[part 1 of 4: package /ComponentTypes]
AUTOSAR XML (schema 00050)
package /ComponentTypes
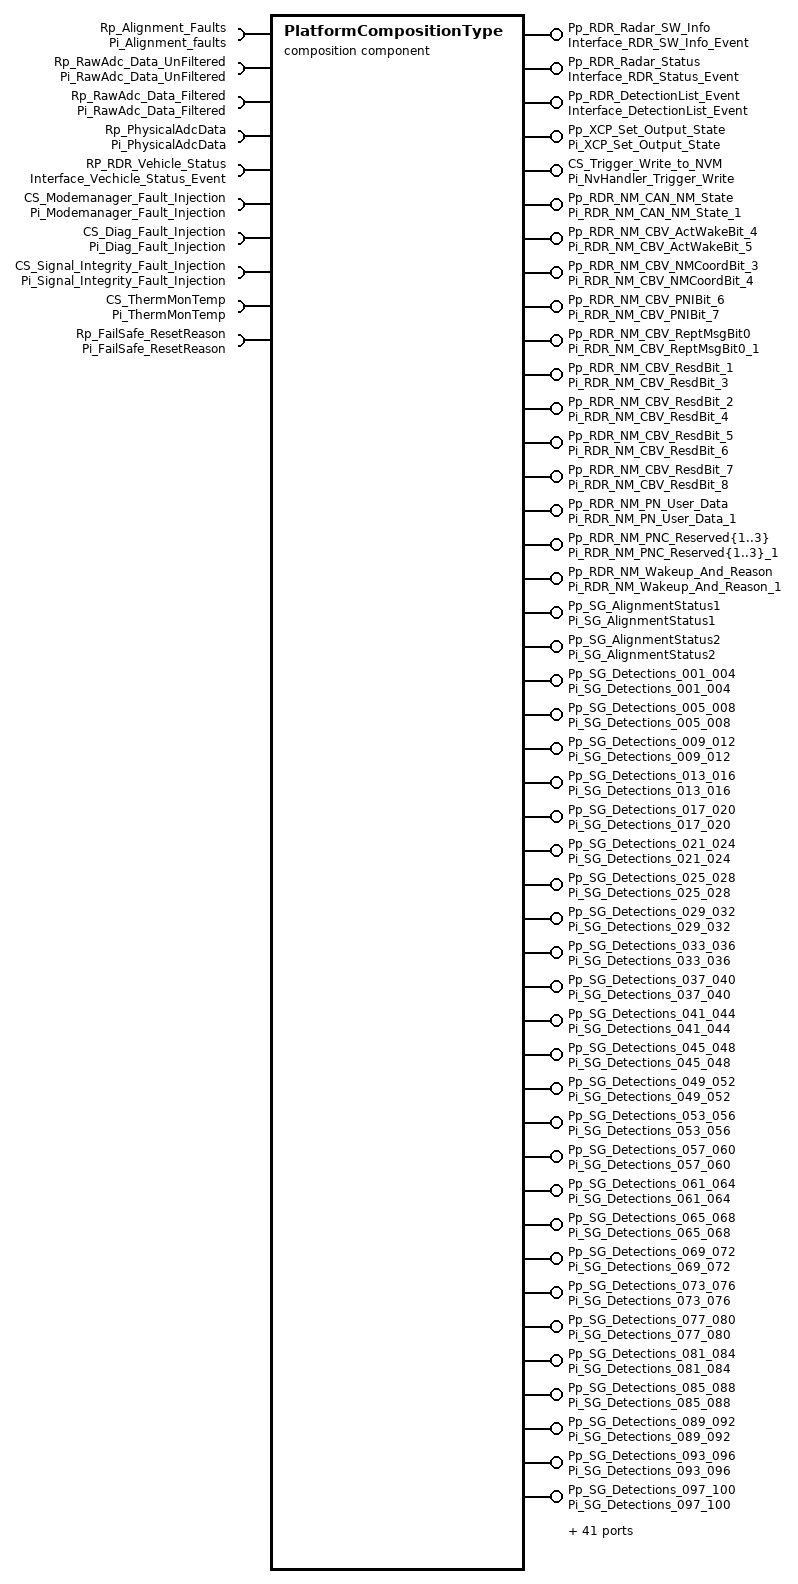
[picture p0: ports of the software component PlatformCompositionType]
  composition sw component type PlatformCompositionType
    4 x require port:
      Rp_Alignment_Faults: nonqueued-receiver-com-spec{data-element=De_Alignment_Faults, filter=data-filter-type=ALWAYS, init-value=constant-reference=C_Alignment_faults}, required-interface=Pi_Alignment_faults
      Rp_RawAdc_Data_UnFiltered: nonqueued-receiver-com-spec{data-element=RawAdcDataUnfiltered, filter=data-filter-type=ALWAYS, init-value=fields=[Adc_Board_Rev:0, Adc_Batt_Volt:0, Adc_Pos_Gnd_A:0, Adc_Pos_Gnd_B:0, Adc_Pos_Gnd_C:0, Adc_Pos_Gnd_D:0, Adc_Eth_0v9:0, Adc_Rdi_Detect:0, Adc_MMIC_Temp:0, Adc_Mcu_Temp:0, Validity_Flag:0]}, required-interface=Pi_RawAdc_Data_UnFiltered
      Rp_RawAdc_Data_Filtered: nonqueued-receiver-com-spec{data-element=De_RawAdcData, filter=data-filter-type=ALWAYS, init-value=fields=[Adc_Board_Rev:0, Adc_Batt_Volt:0, Adc_Pos_Gnd_A:0, Adc_Pos_Gnd_B:0, Adc_Pos_Gnd_C:0, Adc_Pos_Gnd_D:0, Adc_Eth_0v9:0, Adc_Rdi_Detect:0, Adc_MMIC_Temp:0, Adc_Mcu_Temp:0, Validity_Flag:0]}, required-interface=Pi_RawAdc_Data_Filtered
      Rp_PhysicalAdcData: nonqueued-receiver-com-spec{data-element=De_PhysicalAdcData, filter=data-filter-type=ALWAYS, init-value=fields=[Adc_Board_Rev:0, Adc_Batt_Volt:0, Adc_Pos_Gnd_A:0, Adc_Pos_Gnd_B:0, Adc_Pos_Gnd_C:0, Adc_Pos_Gnd_D:0, Adc_Eth_0v9:0, Adc_Rdi_Detect:0, Adc_MMIC_Temp:0, Adc_Mcu_Temp:0, Validity_Flag:0]}, required-interface=Pi_PhysicalAdcData
    provide port Pp_RDR_Radar_SW_Info: nonqueued-sender-com-spec{data-element=RDR_SW_Info, init-value=fields=[{short-label=INFO_CALIBRATION_VERSION, fields=[STS_SMC_CAL_VER_MAJOR:0, STS_SMC_CAL_VER_MINOR:0, STS_SMC_PLATFROM_VERSION:0, STS_SMC_SECTION_COMPTBLITY:0, STS_USC_CAL_VER_MAJOR:0, STS_USC_CAL_VER_MINOR:0, STS_USC_SECTION_COMPTBLITY:0]}, {short-label=INFO_MOUNTING_POS, fields=[STS_SENSOR_HEIGHT:0, STS_SENSOR_MOUNT_LOCATION:0, STS_SENSOR_MOUNT_ORNT_PITCH:0, STS_SENSOR_MOUNT_ORNT_ROLL:0, STS_SENSOR_MOUNT_ORNT_YAW:0, STS_SENSOR_MOUNT_POS_X:0, STS_SENSOR_MOUNT_POS_Y:0, STS_SENSOR_MOUNT_POS_Z:0, STS_SENSOR_POSITION:0]}, {short-label=INFO_SW_VERSION, fields=[STS_PBL_VERSION_FIELD1:0, STS_PBL_VERSION_FIELD2:0, STS_PBL_VERSION_FIELD3:0, STS_PBL_VERSION_FIELD4:0, STS_SW_VERSION_FIELD1:0, STS_SW_VERSION_FIELD2:0, STS_SW_VERSION_FIELD3:0, STS_SW_VERSION_FIELD4:0]}, {short-label=INFO_HW_CAN_VERSION, fields=[STS_DET_DBC_BASE_VER_MAJOR:0, STS_DET_DBC_BASE_VER_MINOR:0, STS_HARDWARE_VERSION:0, STS_PCAN_PROTOCOL_VER_MAJOR:0, STS_PCAN_PROTOCOL_VER_MINOR:0, STS_PLATFORM_VARIANT:0, STS_SERIAL_NUM_JULIAN_DAY:0, STS_SERIAL_NUM_JULIAN_YEAR:0, STS_SERIAL_NUMBER_SEQUENCE:0]}, {short-label=INFO_E2E_HDR, fields=[CRC:0, COUNTER:0, DATA_ID:0, LENGTH:0]}]}, provided-interface=Interface_RDR_SW_Info_Event
    provide port Pp_RDR_Radar_Status: nonqueued-sender-com-spec{data-element=RDR_Status, init-value=fields=[{short-label=STS_ALIGNMENT_HANDLER, fields=[STS_AlignmentAzimuth:0, STS_AlignmentElevation:0, STS_AlignmentError:0, STS_AlignmentModeIn:0, STS_AlignmentModeOut:0, STS_AzimuthStd:0, STS_CalDisplay:0, STS_CalTime:0, STS_CoordinateSystemInput:0, STS_ElevationStd:0, 0, 0, 0, 0, 0, 0, STS_ProgressPercent:0, STS_RadarTypeInput:0]}, {short-label=STS_ALIGNMENT_AUTO, fields=[STS_AAAzimuthStd:0, STS_AACurrentAzimuth:0, STS_AACurrentElevation:0, STS_AAElevationStd:0, STS_AlignmentAutoStatus:0, STS_AutoAlignmentFailRootCause:0, STS_AzimuthErrorNegative:0, STS_AzimuthErrorPositive:0, STS_AzimuthUpdates:0, STS_ElevationErrorNegative:0, STS_ElevationErrorPositive:0, STS_ElevationUpdates:0, STS_HostSpdCompensationFactorQF:0, STS_HostSpeedCompensationFactor:0, STS_RollErrorPositive:0, STS_StartAzimuth:0, STS_StartElevation:0]}, {short-label=STS_ALIGNMENT_STATIC, fields=[STS_AlignmentStaticStatus:0, STS_ImpactByInterference:0, STS_Measured_Range:0, STS_MeasuredRangeRate:0, STS_MeasuredRangeRateStd:0, STS_MeasuredRangeStd:0, STS_MeasuredRCS:0, STS_MeasuredRCSStd:0]}, {short-label=STS_ALIGNMENT_SERVICE, fields=[STS_AlignmentServiceStatus:0, STS_AverageNumberOfDetections:0, STS_AverageSpeed:0, STS_DistanceAbsolute:0, STS_DistanceEffective:0, STS_DurationAbsolute:0, STS_DurationEffective:0, STS_VehicleCondition:0]}, {short-label=STS_ALIGN_SHORT_TRACK, fields=STS_AlignmentShortTrackStatus:0}, {short-label=STS_CAPAB_RDR_PERF, fields=[CAP_BlockageActive:0, CAP_BlockageProbability:0, CAP_BlockageSensitivity:0, CAP_BlockageStatus:0, CAP_BlockageValue:0, CAP_FreeSightCheckActive:0, CAP_FreeSightCheckStatus:0, CAP_SLBlockageFilterValue:0, CAP_SLBlockageFlag:0]}, {short-label=STS_CAPAB_DAMPING, fields=[CAP_DampingActive:0, CAP_DampingCurrent:0, CAP_DampingStandardDeviation:0, CAP_DampingStatus:0]}, {short-label=STS_CAPAB_RANGE_DET, fields=[CAP_AngleAzimuthRangeEnd:0, CAP_AngleAzimuthRangeStart:0, CAP_MaxDetectionRangeCar:[0, 0, 0], CAP_MaxDetRangeMotorbike:[0, 0, 0], CAP_MaxDetRangePedestrian:[0, 0, 0], CAP_RangeEstimationActive:0, CAP_RangeEstimationStatus:0]}, {short-label=STS_CAPAB_SLL_MONITOR, fields=[CAP_SideLobeLevelBeamformer:0, CAP_SLLMonitoringActive:0, CAP_SLLMonitoringStatus:0]}, {short-label=STS_TIMESYNC_STATUS, fields=[STS_NO_TSYN_ERROR:0, STS_POINT_OF_TRIGGER:0, STS_TIME_SYNC_OFFSET:0]}, {short-label=STS_SENSOR_PERF, fields=STS_BRR_STATUS:0}, {short-label=STS_TEMPERATURE, fields=[STS_MCU_TEMP:0, STS_MMIC_TEMP_RX:0, STS_MMIC_TEMP_TX0:0, STS_MMIC_TEMP_TX1_2:0, STS_MMIC_TEMP_TX3_4:0]}, {short-label=STS_FAULTS, fields=STS_CORE_ACTIVE_FAULTS:0}, {short-label=STS_RADAR_PROFILE, fields=[STS_AF_CORE_THROUGHPUT:0, 0, STS_RDD_CORE_THROUGHPUT:0, STS_SCAN_TYPE:0, STS_XCVR_OPERATIONAL:0]}, {short-label=STS_VEHICLE, fields=[STS_STEERING_ANGLE:0, STS_STEERING_ANGLE_SIGN:0, STS_VEH_SPEED_DIRECTION:0, STS_VEHICLE_SPEED_CALC:0, STS_VEHICLE_SUPPLY_VOLTAGE:0, STS_YAW_RATE_BIAS:0]}, {short-label=STS_E2E_HDR, fields=[CRC:0, COUNTER:0, DATA_ID:0, LENGTH:0]}]}, provided-interface=Interface_RDR_Status_Event
    provide port Pp_RDR_DetectionList_Event: nonqueued-sender-com-spec{data-element=DetectionList_Event, init-value=fields=[{short-label=DET_HEADER_STRUCT, fields=[{short-label=HED_SENSOR_COVERAGE, fields=[HED_DET_RANGE_MAX:0, HED_DET_RANGE_MIN:0, HED_DET_SPEED_RANGE_MAX:0, HED_DET_SPEED_RANGE_MIN:0, HED_FOV_HOR_MAX:0, HED_FOV_HOR_MIN:0, HED_FOV_VER_MAX:0, HED_FOV_VER_MIN:0]}, {short-label=HED_RADAR_STATE, fields=[HED_DATA_QUALIFIER:0, HED_LOOK_ID:0, HED_LOOK_INDEX:0, HED_NUM_OF_VALID_DETECTIONS:0, HED_SCAN_INDEX:0]}, {short-label=HED_ALIGNMENT, fields=[HED_ALIGN_HOR_QF:0, HED_ALIGN_HOR_REF:0, HED_ALIGN_VER_QF:0, HED_ALIGN_VER_REF:0]}, {short-label=HED_TIMING_PROFILES, fields=[HED_AF_TIME_INST:0, HED_AF_TIME_PEAK:0, HED_MAIN_CORE_TIME_INST:0, HED_MAIN_CORE_TIME_PEAK:0, HED_RDD_CORE_TIME_INST:0, HED_RDD_CORE_TIME_PEAK:0, HED_SP_CORE_TIME_INST:0, HED_SP_CORE_TIME_PEAK:0]}, {short-label=HED_TIMESTAMP, fields=[HED_SENSOR_TIME_STAMP_NS:0, HED_SENSOR_TIME_STAMP_SEC:0, HED_TIME_SYNC_SRC_MASTER:0, HED_TIME_SYNC_VALIDITY_FLAG:0, HED_TRIGGER_TIME:0]}, {short-label=HED_DETECTION_INFO, fields=[HED_DET_BI_STATIC_COUNT:0, HED_DET_NUM_OF_1PASS:0, HED_DET_NUM_OF_2PASS:0, HED_MAX_NUM_OF_DETECTIONS:0, HED_NUM_OF_RESTBINS_USED:0, HED_OPERATION_MODE:0, HED_PROCESSED_RANGE:0, HED_SLOPE_CORR_EXECUTIONFLAG:0]}, {short-label=HED_INTERFACE_VERSION, fields=[HED_INTRFC_VERSION_ID_MAJOR:0, HED_INTRFC_VERSION_ID_MINOR:0, HED_INTRFC_VERSION_ID_PATCH:0]}]}, {short-label=DET_E2E_HDR, fields=[CRC:0, COUNTER:0, DATA_ID:0, LENGTH:0]}, DETECTIONS_ARRAY:400 x fields=[DET_AZIMUTH:0, DET_AZIMUTH_ERR:0, DET_BI_STATIC_FLAG:0, DET_CONFD_AZIMUTH:0, DET_CONFD_ELEVATION:0, DET_ELEVATION:0, DET_ELEVATION_ERR:0, DET_EXISTENCE_PROB:0, DET_HVC_FLAG:0, DET_OUTSIDE_SECTOR:0, DET_POINT_TARGET_PROB:0, DET_RANGE:0, DET_RANGE_ERR:0, DET_RANGE_VELOCITY:0, DET_RANGE_VELOCITY_ERR:0, DET_RCS:0, DET_SNR:0, DET_SUPER_RES_TARGET:0, DET_VALID_FLAG:0]]}, provided-interface=Interface_DetectionList_Event
    4 x require port:
      RP_RDR_Vehicle_Status: nonqueued-receiver-com-spec{data-element=Vehicle_Status, filter=data-filter-type=ALWAYS, init-value=fields=[{short-label=System_Status_Vehicle, fields=[SSTS_STEERING_ANGLE:0, SSTS_STEERING_ANGLE_SIGN:0, SSTS_VEH_ODOMETER:0, SSTS_VEH_POWER_MODE_STATUS:0, SSTS_VEH_SPD_COMP_FACTOR:0, SSTS_VEH_SYSTEM_VOLTAGE:0, SSTS_VEHICLE_SPEED_CALC:0, SSTS_VEHICLE_SPEED_CALC_QF:0, SSTS_VEHICLE_STATE:0, SSTS_YAW_RATE_BIAS:0, SSTS_YAW_RATE_CALC:0, SSTS_YAW_RATE_CALC_QF:0]}, {short-label=System_Status_Vehicle_State, fields=[SSTS_DRIVE_DIR:0, SSTS_DRIVE_REVERSE:0, SSTS_GEAR_POSITION:0, SSTS_IGN_STATUS:0, SSTS_LROS_DRIVE_DIR:0, SSTS_LROS_DRIVE_REVERSE:0]}, {short-label=System_Status_ADAS_Version, fields=[SSTS_CAN_PCAN_MINOR_ADAS:0, SSTS_CAN_PCAN_MAJOR_ADAS:0, SSTS_SW_VERSION_ADAS:0]}, {short-label=System_Status_Absolute_Time, fields=[SSTS_VEH_AbsoluteTime_Day:0, SSTS_VEH_AbsoluteTime_Hour:0, SSTS_VEH_AbsoluteTime_Minute:0, SSTS_VEH_AbsoluteTime_Month:0, SSTS_VEH_AbsoluteTime_Second:0, SSTS_VEH_AbsoluteTime_Year:0]}, {short-label=SSTS_EtoE_HDR, fields=[EtoE_CRC:0, EtoE_COUNTER:0, EtoE_DATA_ID:0, EtoE_LENGTH:0]}]}, required-interface=Interface_Vechicle_Status_Event
      CS_Modemanager_Fault_Injection: client-com-spec=Read, required-interface=Pi_Modemanager_Fault_Injection
      CS_Diag_Fault_Injection: client-com-spec=Read, required-interface=Pi_Diag_Fault_Injection
      CS_Signal_Integrity_Fault_Injection: client-com-spec=Read, required-interface=Pi_Signal_Integrity_Fault_Injection
    provide port Pp_XCP_Set_Output_State: nonqueued-sender-com-spec{data-element=De_XCP_Set_Output, init-value=constant-reference=C_XCP_Output_State}, provided-interface=Pi_XCP_Set_Output_State
    require port CS_ThermMonTemp: client-com-spec=Read, required-interface=Pi_ThermMonTemp
    require port Rp_FailSafe_ResetReason: nonqueued-receiver-com-spec{data-element=De_FailSafe_ResetReason, filter=data-filter-type=ALWAYS, init-value=constant-reference=C_FailSafe_ResetReason_T}, required-interface=Pi_FailSafe_ResetReason
    189 x provide port:
      CS_Trigger_Write_to_NVM: server-com-spec{operation=NvHandler_Trigger_Write_To_NVM, queue-length=1}, provided-interface=Pi_NvHandler_Trigger_Write
      Pp_RDR_NM_CAN_NM_State: nonqueued-sender-com-spec{data-element=Vdp_RDR_NM_CAN_NM_State, init-value=0}, provided-interface=Pi_RDR_NM_CAN_NM_State_1
      Pp_RDR_NM_CBV_ActWakeBit_4: nonqueued-sender-com-spec{data-element=Vdp_RDR_NM_CBV_ActWakeBit_4, init-value=0}, provided-interface=Pi_RDR_NM_CBV_ActWakeBit_5
      Pp_RDR_NM_CBV_NMCoordBit_3: nonqueued-sender-com-spec{data-element=Vdp_RDR_NM_CBV_NMCoordBit_3, init-value=0}, provided-interface=Pi_RDR_NM_CBV_NMCoordBit_4
      Pp_RDR_NM_CBV_PNIBit_6: nonqueued-sender-com-spec{data-element=Vdp_RDR_NM_CBV_PNIBit_6, init-value=0}, provided-interface=Pi_RDR_NM_CBV_PNIBit_7
      Pp_RDR_NM_CBV_ReptMsgBit0: nonqueued-sender-com-spec{data-element=Vdp_RDR_NM_CBV_ReptMsgBit0, init-value=0}, provided-interface=Pi_RDR_NM_CBV_ReptMsgBit0_1
      Pp_RDR_NM_CBV_ResdBit_1: nonqueued-sender-com-spec{data-element=Vdp_RDR_NM_CBV_ResdBit_1, init-value=0}, provided-interface=Pi_RDR_NM_CBV_ResdBit_3
      Pp_RDR_NM_CBV_ResdBit_2: nonqueued-sender-com-spec{data-element=Vdp_RDR_NM_CBV_ResdBit_2, init-value=0}, provided-interface=Pi_RDR_NM_CBV_ResdBit_4
      Pp_RDR_NM_CBV_ResdBit_5: nonqueued-sender-com-spec{data-element=Vdp_RDR_NM_CBV_ResdBit_5, init-value=0}, provided-interface=Pi_RDR_NM_CBV_ResdBit_6
      Pp_RDR_NM_CBV_ResdBit_7: nonqueued-sender-com-spec{data-element=Vdp_RDR_NM_CBV_ResdBit_7, init-value=0}, provided-interface=Pi_RDR_NM_CBV_ResdBit_8
      Pp_RDR_NM_PN_User_Data: nonqueued-sender-com-spec{data-element=Vdp_RDR_NM_PN_User_Data, init-value=0}, provided-interface=Pi_RDR_NM_PN_User_Data_1
      Pp_RDR_NM_PNC_Reserved{1..3}: nonqueued-sender-com-spec{data-element=Vdp_RDR_NM_PNC_Reserved{1..3}, init-value=0}, provided-interface=Pi_RDR_NM_PNC_Reserved{1..3}_1
      Pp_RDR_NM_Wakeup_And_Reason: nonqueued-sender-com-spec{data-element=Vdp_RDR_NM_Wakeup_And_Reason, init-value=0}, provided-interface=Pi_RDR_NM_Wakeup_And_Reason_1
      Pp_SG_AlignmentStatus1: nonqueued-sender-com-spec{data-element=Vdp_SG_AlignmentStatus1, init-value=fields=[AL_STS_001_CYCLE_COUNTER:0, AL_STS_001_MH_CRC16:0, STS_AAAzimuthStd:0, STS_AACurrentAzimuth:0, STS_AACurrentElevation:0, STS_AAElevationStd:0, STS_AlignmentAutoStatus:0, STS_AlignmentAzimuth:0, STS_AlignmentElevation:0, STS_AlignmentError:0, STS_AlignmentModeIn:0, STS_AlignmentModeOut:0, STS_AutoAlignmentFailRootCause:5, STS_AzimuthErrorNegative:0, STS_AzimuthErrorPositive:0, STS_AzimuthStd:0, STS_AzimuthUpdates:0, STS_CalDisplay:0, STS_CalTime:0, STS_CoordinateSystemInput:0, STS_ElevationErrorNegative:0, STS_ElevationErrorPositive:0, STS_ElevationStd:0, STS_ElevationUpdates:0, STS_HostSpdCompensationFactorQF:0, STS_HostSpeedCompensationFactor:100, 0, 0, 0, 0, 100, 0, STS_ProgressPercent:0, STS_RadarTypeInput:0, STS_RollErrorPositive:0, STS_StartAzimuth:0, STS_StartElevation:0]}, provided-interface=Pi_SG_AlignmentStatus1
      Pp_SG_AlignmentStatus2: nonqueued-sender-com-spec{data-element=Vdp_SG_AlignmentStatus2, init-value=fields=[AL_STS_002_CYCLE_COUNTER:0, AL_STS_002_MH_CRC16:0, STS_AlignmentServiceStatus:0, STS_AlignmentShortTrackStatus:0, STS_AlignmentStaticStatus:0, STS_AverageNumberOfDetections:0, STS_AverageSpeed:0, STS_DistanceAbsolute:0, STS_DistanceEffective:0, STS_DurationAbsolute:0, STS_DurationEffective:0, STS_ImpactByInterference:0, STS_Measured_Range:1200, STS_MeasuredRangeRate:0, STS_MeasuredRangeRateStd:0, STS_MeasuredRangeStd:0, STS_MeasuredRCS:0, STS_MeasuredRCSStd:0, STS_VehicleCondition:6]}, provided-interface=Pi_SG_AlignmentStatus2
      Pp_SG_Detections_001_004: nonqueued-sender-com-spec{data-element=Vdp_SG_Detections_001_004, init-value=fields=[DET_AZIMUTH_001:0, DET_AZIMUTH_002:0, DET_AZIMUTH_003:0, DET_AZIMUTH_004:0, DET_AZIMUTH_ERR_001:0, DET_AZIMUTH_ERR_002:0, DET_AZIMUTH_ERR_003:0, DET_AZIMUTH_ERR_004:0, DET_BI_STATIC_FLAG_001:0, DET_BI_STATIC_FLAG_002:0, DET_BI_STATIC_FLAG_003:0, DET_BI_STATIC_FLAG_004:0, DET_CONFD_AZIMUTH_001:0, DET_CONFD_AZIMUTH_002:0, DET_CONFD_AZIMUTH_003:0, DET_CONFD_AZIMUTH_004:0, DET_CONFD_ELEVATION_001:0, DET_CONFD_ELEVATION_002:0, DET_CONFD_ELEVATION_003:0, DET_CONFD_ELEVATION_004:0, DET_ELEVATION_001:0, DET_ELEVATION_002:0, DET_ELEVATION_003:0, DET_ELEVATION_004:0, DET_ELEVATION_ERR_001:0, DET_ELEVATION_ERR_002:0, DET_ELEVATION_ERR_003:0, DET_ELEVATION_ERR_004:0, DET_EXISTENCE_PROB_001:0, DET_EXISTENCE_PROB_002:0, DET_EXISTENCE_PROB_003:0, DET_EXISTENCE_PROB_004:0, DET_HVC_FLAG_001:0, DET_HVC_FLAG_002:0, DET_HVC_FLAG_003:0, DET_HVC_FLAG_004:0, DET_MH_CRC16_001_004:0, DET_MH_CYCLE_COUNTER_001_004:0, DET_MH_SCAN_INDEX_4LSB_001_004:0, DET_OUTSIDE_SECTOR_001:0, DET_OUTSIDE_SECTOR_002:0, DET_OUTSIDE_SECTOR_003:0, DET_OUTSIDE_SECTOR_004:0, DET_POINT_TARGET_PROB_001:0, DET_POINT_TARGET_PROB_002:0, DET_POINT_TARGET_PROB_003:0, DET_POINT_TARGET_PROB_004:0, DET_RANGE_001:0, DET_RANGE_002:0, DET_RANGE_003:0, DET_RANGE_004:0, DET_RANGE_ERR_001:0, DET_RANGE_ERR_002:0, DET_RANGE_ERR_003:0, DET_RANGE_ERR_004:0, DET_RANGE_VELOCITY_001:16384, DET_RANGE_VELOCITY_002:16384, DET_RANGE_VELOCITY_003:16384, DET_RANGE_VELOCITY_004:16384, DET_RANGE_VELOCITY_ERR_001:0, DET_RANGE_VELOCITY_ERR_002:0, DET_RANGE_VELOCITY_ERR_003:0, DET_RANGE_VELOCITY_ERR_004:0, DET_RCS_001:128, DET_RCS_002:128, DET_RCS_003:128, DET_RCS_004:128, DET_SNR_001:0, DET_SNR_002:0, DET_SNR_003:0, DET_SNR_004:0, DET_SUPER_RES_TARGET_001:0, DET_SUPER_RES_TARGET_002:0, DET_SUPER_RES_TARGET_003:0, DET_SUPER_RES_TARGET_004:0, DET_VALID_FLAG_001:0, DET_VALID_FLAG_002:0, DET_VALID_FLAG_003:0, DET_VALID_FLAG_004:0]}, provided-interface=Pi_SG_Detections_001_004
      Pp_SG_Detections_005_008: nonqueued-sender-com-spec{data-element=Vdp_SG_Detections_005_008, init-value=fields=[DET_AZIMUTH_005:0, DET_AZIMUTH_006:0, DET_AZIMUTH_007:0, DET_AZIMUTH_008:0, DET_AZIMUTH_ERR_005:0, DET_AZIMUTH_ERR_006:0, DET_AZIMUTH_ERR_007:0, DET_AZIMUTH_ERR_008:0, DET_BI_STATIC_FLAG_005:0, DET_BI_STATIC_FLAG_006:0, DET_BI_STATIC_FLAG_007:0, DET_BI_STATIC_FLAG_008:0, DET_CONFD_AZIMUTH_005:0, DET_CONFD_AZIMUTH_006:0, DET_CONFD_AZIMUTH_007:0, DET_CONFD_AZIMUTH_008:0, DET_CONFD_ELEVATION_005:0, DET_CONFD_ELEVATION_006:0, DET_CONFD_ELEVATION_007:0, DET_CONFD_ELEVATION_008:0, DET_ELEVATION_005:0, DET_ELEVATION_006:0, DET_ELEVATION_007:0, DET_ELEVATION_008:0, DET_ELEVATION_ERR_005:0, DET_ELEVATION_ERR_006:0, DET_ELEVATION_ERR_007:0, DET_ELEVATION_ERR_008:0, DET_EXISTENCE_PROB_005:0, DET_EXISTENCE_PROB_006:0, DET_EXISTENCE_PROB_007:0, DET_EXISTENCE_PROB_008:0, DET_HVC_FLAG_005:0, DET_HVC_FLAG_006:0, DET_HVC_FLAG_007:0, DET_HVC_FLAG_008:0, DET_MH_CRC16_005_008:0, DET_MH_CYCLE_COUNTER_005_008:0, DET_MH_SCAN_INDEX_4LSB_005_008:0, DET_OUTSIDE_SECTOR_005:0, DET_OUTSIDE_SECTOR_006:0, DET_OUTSIDE_SECTOR_007:0, DET_OUTSIDE_SECTOR_008:0, DET_POINT_TARGET_PROB_005:0, DET_POINT_TARGET_PROB_006:0, DET_POINT_TARGET_PROB_007:0, DET_POINT_TARGET_PROB_008:0, DET_RANGE_005:0, DET_RANGE_006:0, DET_RANGE_007:0, DET_RANGE_008:0, DET_RANGE_ERR_005:0, DET_RANGE_ERR_006:0, DET_RANGE_ERR_007:0, DET_RANGE_ERR_008:0, DET_RANGE_VELOCITY_005:16384, DET_RANGE_VELOCITY_006:16384, DET_RANGE_VELOCITY_007:16384, DET_RANGE_VELOCITY_008:16384, DET_RANGE_VELOCITY_ERR_005:0, DET_RANGE_VELOCITY_ERR_006:0, DET_RANGE_VELOCITY_ERR_007:0, DET_RANGE_VELOCITY_ERR_008:0, DET_RCS_005:128, DET_RCS_006:128, DET_RCS_007:128, DET_RCS_008:128, DET_SNR_005:0, DET_SNR_006:0, DET_SNR_007:0, DET_SNR_008:0, DET_SUPER_RES_TARGET_005:0, DET_SUPER_RES_TARGET_006:0, DET_SUPER_RES_TARGET_007:0, DET_SUPER_RES_TARGET_008:0, DET_VALID_FLAG_005:0, DET_VALID_FLAG_006:0, DET_VALID_FLAG_007:0, DET_VALID_FLAG_008:0]}, provided-interface=Pi_SG_Detections_005_008
      Pp_SG_Detections_009_012: nonqueued-sender-com-spec{data-element=Vdp_SG_Detections_009_012, init-value=fields=[DET_AZIMUTH_009:0, DET_AZIMUTH_010:0, DET_AZIMUTH_011:0, DET_AZIMUTH_012:0, DET_AZIMUTH_ERR_009:0, DET_AZIMUTH_ERR_010:0, DET_AZIMUTH_ERR_011:0, DET_AZIMUTH_ERR_012:0, DET_BI_STATIC_FLAG_009:0, DET_BI_STATIC_FLAG_010:0, DET_BI_STATIC_FLAG_011:0, DET_BI_STATIC_FLAG_012:0, DET_CONFD_AZIMUTH_009:0, DET_CONFD_AZIMUTH_010:0, DET_CONFD_AZIMUTH_011:0, DET_CONFD_AZIMUTH_012:0, DET_CONFD_ELEVATION_009:0, DET_CONFD_ELEVATION_010:0, DET_CONFD_ELEVATION_011:0, DET_CONFD_ELEVATION_012:0, DET_ELEVATION_009:0, DET_ELEVATION_010:0, DET_ELEVATION_011:0, DET_ELEVATION_012:0, DET_ELEVATION_ERR_009:0, DET_ELEVATION_ERR_010:0, DET_ELEVATION_ERR_011:0, DET_ELEVATION_ERR_012:0, DET_EXISTENCE_PROB_009:0, DET_EXISTENCE_PROB_010:0, DET_EXISTENCE_PROB_011:0, DET_EXISTENCE_PROB_012:0, DET_HVC_FLAG_009:0, DET_HVC_FLAG_010:0, DET_HVC_FLAG_011:0, DET_HVC_FLAG_012:0, DET_MH_CRC16_009_012:0, DET_MH_CYCLE_COUNTER_009_012:0, DET_MH_SCAN_INDEX_4LSB_009_012:0, DET_OUTSIDE_SECTOR_009:0, DET_OUTSIDE_SECTOR_010:0, DET_OUTSIDE_SECTOR_011:0, DET_OUTSIDE_SECTOR_012:0, DET_POINT_TARGET_PROB_009:0, DET_POINT_TARGET_PROB_010:0, DET_POINT_TARGET_PROB_011:0, DET_POINT_TARGET_PROB_012:0, DET_RANGE_009:0, DET_RANGE_010:0, DET_RANGE_011:0, DET_RANGE_012:0, DET_RANGE_ERR_009:0, DET_RANGE_ERR_010:0, DET_RANGE_ERR_011:0, DET_RANGE_ERR_012:0, DET_RANGE_VELOCITY_009:16384, DET_RANGE_VELOCITY_010:16384, DET_RANGE_VELOCITY_011:16384, DET_RANGE_VELOCITY_012:16384, DET_RANGE_VELOCITY_ERR_009:0, DET_RANGE_VELOCITY_ERR_010:0, DET_RANGE_VELOCITY_ERR_011:0, DET_RANGE_VELOCITY_ERR_012:0, DET_RCS_009:128, DET_RCS_010:128, DET_RCS_011:128, DET_RCS_012:128, DET_SNR_009:0, DET_SNR_010:0, DET_SNR_011:0, DET_SNR_012:0, DET_SUPER_RES_TARGET_009:0, DET_SUPER_RES_TARGET_010:0, DET_SUPER_RES_TARGET_011:0, DET_SUPER_RES_TARGET_012:0, DET_VALID_FLAG_009:0, DET_VALID_FLAG_010:0, DET_VALID_FLAG_011:0, DET_VALID_FLAG_012:0]}, provided-interface=Pi_SG_Detections_009_012
      Pp_SG_Detections_013_016: nonqueued-sender-com-spec{data-element=Vdp_SG_Detections_013_016, init-value=fields=[DET_AZIMUTH_013:0, DET_AZIMUTH_014:0, DET_AZIMUTH_015:0, DET_AZIMUTH_016:0, DET_AZIMUTH_ERR_013:0, DET_AZIMUTH_ERR_014:0, DET_AZIMUTH_ERR_015:0, DET_AZIMUTH_ERR_016:0, DET_BI_STATIC_FLAG_013:0, DET_BI_STATIC_FLAG_014:0, DET_BI_STATIC_FLAG_015:0, DET_BI_STATIC_FLAG_016:0, DET_CONFD_AZIMUTH_013:0, DET_CONFD_AZIMUTH_014:0, DET_CONFD_AZIMUTH_015:0, DET_CONFD_AZIMUTH_016:0, DET_CONFD_ELEVATION_013:0, DET_CONFD_ELEVATION_014:0, DET_CONFD_ELEVATION_015:0, DET_CONFD_ELEVATION_016:0, DET_ELEVATION_013:0, DET_ELEVATION_014:0, DET_ELEVATION_015:0, DET_ELEVATION_016:0, DET_ELEVATION_ERR_013:0, DET_ELEVATION_ERR_014:0, DET_ELEVATION_ERR_015:0, DET_ELEVATION_ERR_016:0, DET_EXISTENCE_PROB_013:0, DET_EXISTENCE_PROB_014:0, DET_EXISTENCE_PROB_015:0, DET_EXISTENCE_PROB_016:0, DET_HVC_FLAG_013:0, DET_HVC_FLAG_014:0, DET_HVC_FLAG_015:0, DET_HVC_FLAG_016:0, DET_MH_CRC16_013_016:0, DET_MH_CYCLE_COUNTER_013_016:0, DET_MH_SCAN_INDEX_4LSB_013_016:0, DET_OUTSIDE_SECTOR_013:0, DET_OUTSIDE_SECTOR_014:0, DET_OUTSIDE_SECTOR_015:0, DET_OUTSIDE_SECTOR_016:0, DET_POINT_TARGET_PROB_013:0, DET_POINT_TARGET_PROB_014:0, DET_POINT_TARGET_PROB_015:0, DET_POINT_TARGET_PROB_016:0, DET_RANGE_013:0, DET_RANGE_014:0, DET_RANGE_015:0, DET_RANGE_016:0, DET_RANGE_ERR_013:0, DET_RANGE_ERR_014:0, DET_RANGE_ERR_015:0, DET_RANGE_ERR_016:0, DET_RANGE_VELOCITY_013:16384, DET_RANGE_VELOCITY_014:16384, DET_RANGE_VELOCITY_015:16384, DET_RANGE_VELOCITY_016:16384, DET_RANGE_VELOCITY_ERR_013:0, DET_RANGE_VELOCITY_ERR_014:0, DET_RANGE_VELOCITY_ERR_015:0, DET_RANGE_VELOCITY_ERR_016:0, DET_RCS_013:128, DET_RCS_014:128, DET_RCS_015:128, DET_RCS_016:128, DET_SNR_013:0, DET_SNR_014:0, DET_SNR_015:0, DET_SNR_016:0, DET_SUPER_RES_TARGET_013:0, DET_SUPER_RES_TARGET_014:0, DET_SUPER_RES_TARGET_015:0, DET_SUPER_RES_TARGET_016:0, DET_VALID_FLAG_013:0, DET_VALID_FLAG_014:0, DET_VALID_FLAG_015:0, DET_VALID_FLAG_016:0]}, provided-interface=Pi_SG_Detections_013_016
      Pp_SG_Detections_017_020: nonqueued-sender-com-spec{data-element=Vdp_SG_Detections_017_020, init-value=fields=[DET_AZIMUTH_017:0, DET_AZIMUTH_018:0, DET_AZIMUTH_019:0, DET_AZIMUTH_020:0, DET_AZIMUTH_ERR_017:0, DET_AZIMUTH_ERR_018:0, DET_AZIMUTH_ERR_019:0, DET_AZIMUTH_ERR_020:0, DET_BI_STATIC_FLAG_017:0, DET_BI_STATIC_FLAG_018:0, DET_BI_STATIC_FLAG_019:0, DET_BI_STATIC_FLAG_020:0, DET_CONFD_AZIMUTH_017:0, DET_CONFD_AZIMUTH_018:0, DET_CONFD_AZIMUTH_019:0, DET_CONFD_AZIMUTH_020:0, DET_CONFD_ELEVATION_017:0, DET_CONFD_ELEVATION_018:0, DET_CONFD_ELEVATION_019:0, DET_CONFD_ELEVATION_020:0, DET_ELEVATION_017:0, DET_ELEVATION_018:0, DET_ELEVATION_019:0, DET_ELEVATION_020:0, DET_ELEVATION_ERR_017:0, DET_ELEVATION_ERR_018:0, DET_ELEVATION_ERR_019:0, DET_ELEVATION_ERR_020:0, DET_EXISTENCE_PROB_017:0, DET_EXISTENCE_PROB_018:0, DET_EXISTENCE_PROB_019:0, DET_EXISTENCE_PROB_020:0, DET_HVC_FLAG_017:0, DET_HVC_FLAG_018:0, DET_HVC_FLAG_019:0, DET_HVC_FLAG_020:0, DET_MH_CRC16_017_020:0, DET_MH_CYCLE_COUNTER_017_020:0, DET_MH_SCAN_INDEX_4LSB_017_020:0, DET_OUTSIDE_SECTOR_017:0, DET_OUTSIDE_SECTOR_018:0, DET_OUTSIDE_SECTOR_019:0, DET_OUTSIDE_SECTOR_020:0, DET_POINT_TARGET_PROB_017:0, DET_POINT_TARGET_PROB_018:0, DET_POINT_TARGET_PROB_019:0, DET_POINT_TARGET_PROB_020:0, DET_RANGE_017:0, DET_RANGE_018:0, DET_RANGE_019:0, DET_RANGE_020:0, DET_RANGE_ERR_017:0, DET_RANGE_ERR_018:0, DET_RANGE_ERR_019:0, DET_RANGE_ERR_020:0, DET_RANGE_VELOCITY_017:16384, DET_RANGE_VELOCITY_018:16384, DET_RANGE_VELOCITY_019:16384, DET_RANGE_VELOCITY_020:16384, DET_RANGE_VELOCITY_ERR_017:0, DET_RANGE_VELOCITY_ERR_018:0, DET_RANGE_VELOCITY_ERR_019:0, DET_RANGE_VELOCITY_ERR_020:0, DET_RCS_017:128, DET_RCS_018:128, DET_RCS_019:128, DET_RCS_020:128, DET_SNR_017:0, DET_SNR_018:0, DET_SNR_019:0, DET_SNR_020:0, DET_SUPER_RES_TARGET_017:0, DET_SUPER_RES_TARGET_018:0, DET_SUPER_RES_TARGET_019:0, DET_SUPER_RES_TARGET_020:0, DET_VALID_FLAG_017:0, DET_VALID_FLAG_018:0, DET_VALID_FLAG_019:0, DET_VALID_FLAG_020:0]}, provided-interface=Pi_SG_Detections_017_020
      Pp_SG_Detections_021_024: nonqueued-sender-com-spec{data-element=Vdp_SG_Detections_021_024, init-value=fields=[DET_AZIMUTH_021:0, DET_AZIMUTH_022:0, DET_AZIMUTH_023:0, DET_AZIMUTH_024:0, DET_AZIMUTH_ERR_021:0, DET_AZIMUTH_ERR_022:0, DET_AZIMUTH_ERR_023:0, DET_AZIMUTH_ERR_024:0, DET_BI_STATIC_FLAG_021:0, DET_BI_STATIC_FLAG_022:0, DET_BI_STATIC_FLAG_023:0, DET_BI_STATIC_FLAG_024:0, DET_CONFD_AZIMUTH_021:0, DET_CONFD_AZIMUTH_022:0, DET_CONFD_AZIMUTH_023:0, DET_CONFD_AZIMUTH_024:0, DET_CONFD_ELEVATION_021:0, DET_CONFD_ELEVATION_022:0, DET_CONFD_ELEVATION_023:0, DET_CONFD_ELEVATION_024:0, DET_ELEVATION_021:0, DET_ELEVATION_022:0, DET_ELEVATION_023:0, DET_ELEVATION_024:0, DET_ELEVATION_ERR_021:0, DET_ELEVATION_ERR_022:0, DET_ELEVATION_ERR_023:0, DET_ELEVATION_ERR_024:0, DET_EXISTENCE_PROB_021:0, DET_EXISTENCE_PROB_022:0, DET_EXISTENCE_PROB_023:0, DET_EXISTENCE_PROB_024:0, DET_HVC_FLAG_021:0, DET_HVC_FLAG_022:0, DET_HVC_FLAG_023:0, DET_HVC_FLAG_024:0, DET_MH_CRC16_021_024:0, DET_MH_CYCLE_COUNTER_021_024:0, DET_MH_SCAN_INDEX_4LSB_021_024:0, DET_OUTSIDE_SECTOR_021:0, DET_OUTSIDE_SECTOR_022:0, DET_OUTSIDE_SECTOR_023:0, DET_OUTSIDE_SECTOR_024:0, DET_POINT_TARGET_PROB_021:0, DET_POINT_TARGET_PROB_022:0, DET_POINT_TARGET_PROB_023:0, DET_POINT_TARGET_PROB_024:0, DET_RANGE_021:0, DET_RANGE_022:0, DET_RANGE_023:0, DET_RANGE_024:0, DET_RANGE_ERR_021:0, DET_RANGE_ERR_022:0, DET_RANGE_ERR_023:0, DET_RANGE_ERR_024:0, DET_RANGE_VELOCITY_021:16384, DET_RANGE_VELOCITY_022:16384, DET_RANGE_VELOCITY_023:16384, DET_RANGE_VELOCITY_024:16384, DET_RANGE_VELOCITY_ERR_021:0, DET_RANGE_VELOCITY_ERR_022:0, DET_RANGE_VELOCITY_ERR_023:0, DET_RANGE_VELOCITY_ERR_024:0, DET_RCS_021:128, DET_RCS_022:128, DET_RCS_023:128, DET_RCS_024:128, DET_SNR_021:0, DET_SNR_022:0, DET_SNR_023:0, DET_SNR_024:0, DET_SUPER_RES_TARGET_021:0, DET_SUPER_RES_TARGET_022:0, DET_SUPER_RES_TARGET_023:0, DET_SUPER_RES_TARGET_024:0, DET_VALID_FLAG_021:0, DET_VALID_FLAG_022:0, DET_VALID_FLAG_023:0, DET_VALID_FLAG_024:0]}, provided-interface=Pi_SG_Detections_021_024
      Pp_SG_Detections_025_028: nonqueued-sender-com-spec{data-element=Vdp_SG_Detections_025_028, init-value=fields=[DET_AZIMUTH_025:0, DET_AZIMUTH_026:0, DET_AZIMUTH_027:0, DET_AZIMUTH_028:0, DET_AZIMUTH_ERR_025:0, DET_AZIMUTH_ERR_026:0, DET_AZIMUTH_ERR_027:0, DET_AZIMUTH_ERR_028:0, DET_BI_STATIC_FLAG_025:0, DET_BI_STATIC_FLAG_026:0, DET_BI_STATIC_FLAG_027:0, DET_BI_STATIC_FLAG_028:0, DET_CONFD_AZIMUTH_025:0, DET_CONFD_AZIMUTH_026:0, DET_CONFD_AZIMUTH_027:0, DET_CONFD_AZIMUTH_028:0, DET_CONFD_ELEVATION_025:0, DET_CONFD_ELEVATION_026:0, DET_CONFD_ELEVATION_027:0, DET_CONFD_ELEVATION_028:0, DET_ELEVATION_025:0, DET_ELEVATION_026:0, DET_ELEVATION_027:0, DET_ELEVATION_028:0, DET_ELEVATION_ERR_025:0, DET_ELEVATION_ERR_026:0, DET_ELEVATION_ERR_027:0, DET_ELEVATION_ERR_028:0, DET_EXISTENCE_PROB_025:0, DET_EXISTENCE_PROB_026:0, DET_EXISTENCE_PROB_027:0, DET_EXISTENCE_PROB_028:0, DET_HVC_FLAG_025:0, DET_HVC_FLAG_026:0, DET_HVC_FLAG_027:0, DET_HVC_FLAG_028:0, DET_MH_CRC16_025_028:0, DET_MH_CYCLE_COUNTER_025_028:0, DET_MH_SCAN_INDEX_4LSB_025_028:0, DET_OUTSIDE_SECTOR_025:0, DET_OUTSIDE_SECTOR_026:0, DET_OUTSIDE_SECTOR_027:0, DET_OUTSIDE_SECTOR_028:0, DET_POINT_TARGET_PROB_025:0, DET_POINT_TARGET_PROB_026:0, DET_POINT_TARGET_PROB_027:0, DET_POINT_TARGET_PROB_028:0, DET_RANGE_025:0, DET_RANGE_026:0, DET_RANGE_027:0, DET_RANGE_028:0, DET_RANGE_ERR_025:0, DET_RANGE_ERR_026:0, DET_RANGE_ERR_027:0, DET_RANGE_ERR_028:0, DET_RANGE_VELOCITY_025:16384, DET_RANGE_VELOCITY_026:16384, DET_RANGE_VELOCITY_027:16384, DET_RANGE_VELOCITY_028:16384, DET_RANGE_VELOCITY_ERR_025:0, DET_RANGE_VELOCITY_ERR_026:0, DET_RANGE_VELOCITY_ERR_027:0, DET_RANGE_VELOCITY_ERR_028:0, DET_RCS_025:128, DET_RCS_026:128, DET_RCS_027:128, DET_RCS_028:128, DET_SNR_025:0, DET_SNR_026:0, DET_SNR_027:0, DET_SNR_028:0, DET_SUPER_RES_TARGET_025:0, DET_SUPER_RES_TARGET_026:0, DET_SUPER_RES_TARGET_027:0, DET_SUPER_RES_TARGET_028:0, DET_VALID_FLAG_025:0, DET_VALID_FLAG_026:0, DET_VALID_FLAG_027:0, DET_VALID_FLAG_028:0]}, provided-interface=Pi_SG_Detections_025_028
      Pp_SG_Detections_029_032: nonqueued-sender-com-spec{data-element=Vdp_SG_Detections_029_032, init-value=fields=[DET_AZIMUTH_029:0, DET_AZIMUTH_030:0, DET_AZIMUTH_031:0, DET_AZIMUTH_032:0, DET_AZIMUTH_ERR_029:0, DET_AZIMUTH_ERR_030:0, DET_AZIMUTH_ERR_031:0, DET_AZIMUTH_ERR_032:0, DET_BI_STATIC_FLAG_029:0, DET_BI_STATIC_FLAG_030:0, DET_BI_STATIC_FLAG_031:0, DET_BI_STATIC_FLAG_032:0, DET_CONFD_AZIMUTH_029:0, DET_CONFD_AZIMUTH_030:0, DET_CONFD_AZIMUTH_031:0, DET_CONFD_AZIMUTH_032:0, DET_CONFD_ELEVATION_029:0, DET_CONFD_ELEVATION_030:0, DET_CONFD_ELEVATION_031:0, DET_CONFD_ELEVATION_032:0, DET_ELEVATION_029:0, DET_ELEVATION_030:0, DET_ELEVATION_031:0, DET_ELEVATION_032:0, DET_ELEVATION_ERR_029:0, DET_ELEVATION_ERR_030:0, DET_ELEVATION_ERR_031:0, DET_ELEVATION_ERR_032:0, DET_EXISTENCE_PROB_029:0, DET_EXISTENCE_PROB_030:0, DET_EXISTENCE_PROB_031:0, DET_EXISTENCE_PROB_032:0, DET_HVC_FLAG_029:0, DET_HVC_FLAG_030:0, DET_HVC_FLAG_031:0, DET_HVC_FLAG_032:0, DET_MH_CRC16_029_032:0, DET_MH_CYCLE_COUNTER_029_032:0, DET_MH_SCAN_INDEX_4LSB_029_032:0, DET_OUTSIDE_SECTOR_029:0, DET_OUTSIDE_SECTOR_030:0, DET_OUTSIDE_SECTOR_031:0, DET_OUTSIDE_SECTOR_032:0, DET_POINT_TARGET_PROB_029:0, DET_POINT_TARGET_PROB_030:0, DET_POINT_TARGET_PROB_031:0, DET_POINT_TARGET_PROB_032:0, DET_RANGE_029:0, DET_RANGE_030:0, DET_RANGE_031:0, DET_RANGE_032:0, DET_RANGE_ERR_029:0, DET_RANGE_ERR_030:0, DET_RANGE_ERR_031:0, DET_RANGE_ERR_032:0, DET_RANGE_VELOCITY_029:16384, DET_RANGE_VELOCITY_030:16384, DET_RANGE_VELOCITY_031:16384, DET_RANGE_VELOCITY_032:16384, DET_RANGE_VELOCITY_ERR_029:0, DET_RANGE_VELOCITY_ERR_030:0, DET_RANGE_VELOCITY_ERR_031:0, DET_RANGE_VELOCITY_ERR_032:0, DET_RCS_029:128, DET_RCS_030:128, DET_RCS_031:128, DET_RCS_032:128, DET_SNR_029:0, DET_SNR_030:0, DET_SNR_031:0, DET_SNR_032:0, DET_SUPER_RES_TARGET_029:0, DET_SUPER_RES_TARGET_030:0, DET_SUPER_RES_TARGET_031:0, DET_SUPER_RES_TARGET_032:0, DET_VALID_FLAG_029:0, DET_VALID_FLAG_030:0, DET_VALID_FLAG_031:0, DET_VALID_FLAG_032:0]}, provided-interface=Pi_SG_Detections_029_032
      Pp_SG_Detections_033_036: nonqueued-sender-com-spec{data-element=Vdp_SG_Detections_033_036, init-value=fields=[DET_AZIMUTH_033:0, DET_AZIMUTH_034:0, DET_AZIMUTH_035:0, DET_AZIMUTH_036:0, DET_AZIMUTH_ERR_033:0, DET_AZIMUTH_ERR_034:0, DET_AZIMUTH_ERR_035:0, DET_AZIMUTH_ERR_036:0, DET_BI_STATIC_FLAG_033:0, DET_BI_STATIC_FLAG_034:0, DET_BI_STATIC_FLAG_035:0, DET_BI_STATIC_FLAG_036:0, DET_CONFD_AZIMUTH_033:0, DET_CONFD_AZIMUTH_034:0, DET_CONFD_AZIMUTH_035:0, DET_CONFD_AZIMUTH_036:0, DET_CONFD_ELEVATION_033:0, DET_CONFD_ELEVATION_034:0, DET_CONFD_ELEVATION_035:0, DET_CONFD_ELEVATION_036:0, DET_ELEVATION_033:0, DET_ELEVATION_034:0, DET_ELEVATION_035:0, DET_ELEVATION_036:0, DET_ELEVATION_ERR_033:0, DET_ELEVATION_ERR_034:0, DET_ELEVATION_ERR_035:0, DET_ELEVATION_ERR_036:0, DET_EXISTENCE_PROB_033:0, DET_EXISTENCE_PROB_034:0, DET_EXISTENCE_PROB_035:0, DET_EXISTENCE_PROB_036:0, DET_HVC_FLAG_033:0, DET_HVC_FLAG_034:0, DET_HVC_FLAG_035:0, DET_HVC_FLAG_036:0, DET_MH_CRC16_033_036:0, DET_MH_CYCLE_COUNTER_033_036:0, DET_MH_SCAN_INDEX_4LSB_033_036:0, DET_OUTSIDE_SECTOR_033:0, DET_OUTSIDE_SECTOR_034:0, DET_OUTSIDE_SECTOR_035:0, DET_OUTSIDE_SECTOR_036:0, DET_POINT_TARGET_PROB_033:0, DET_POINT_TARGET_PROB_034:0, DET_POINT_TARGET_PROB_035:0, DET_POINT_TARGET_PROB_036:0, DET_RANGE_033:0, DET_RANGE_034:0, DET_RANGE_035:0, DET_RANGE_036:0, DET_RANGE_ERR_033:0, DET_RANGE_ERR_034:0, DET_RANGE_ERR_035:0, DET_RANGE_ERR_036:0, DET_RANGE_VELOCITY_033:16384, DET_RANGE_VELOCITY_034:16384, DET_RANGE_VELOCITY_035:16384, DET_RANGE_VELOCITY_036:16384, DET_RANGE_VELOCITY_ERR_033:0, DET_RANGE_VELOCITY_ERR_034:0, DET_RANGE_VELOCITY_ERR_035:0, DET_RANGE_VELOCITY_ERR_036:0, DET_RCS_033:128, DET_RCS_034:128, DET_RCS_035:128, DET_RCS_036:128, DET_SNR_033:0, DET_SNR_034:0, DET_SNR_035:0, DET_SNR_036:0, DET_SUPER_RES_TARGET_033:0, DET_SUPER_RES_TARGET_034:0, DET_SUPER_RES_TARGET_035:0, DET_SUPER_RES_TARGET_036:0, DET_VALID_FLAG_033:0, DET_VALID_FLAG_034:0, DET_VALID_FLAG_035:0, DET_VALID_FLAG_036:0]}, provided-interface=Pi_SG_Detections_033_036
      Pp_SG_Detections_037_040: nonqueued-sender-com-spec{data-element=Vdp_SG_Detections_037_040, init-value=fields=[DET_AZIMUTH_037:0, DET_AZIMUTH_038:0, DET_AZIMUTH_039:0, DET_AZIMUTH_040:0, DET_AZIMUTH_ERR_037:0, DET_AZIMUTH_ERR_038:0, DET_AZIMUTH_ERR_039:0, DET_AZIMUTH_ERR_040:0, DET_BI_STATIC_FLAG_037:0, DET_BI_STATIC_FLAG_038:0, DET_BI_STATIC_FLAG_039:0, DET_BI_STATIC_FLAG_040:0, DET_CONFD_AZIMUTH_037:0, DET_CONFD_AZIMUTH_038:0, DET_CONFD_AZIMUTH_039:0, DET_CONFD_AZIMUTH_040:0, DET_CONFD_ELEVATION_037:0, DET_CONFD_ELEVATION_038:0, DET_CONFD_ELEVATION_039:0, DET_CONFD_ELEVATION_040:0, DET_ELEVATION_037:0, DET_ELEVATION_038:0, DET_ELEVATION_039:0, DET_ELEVATION_040:0, DET_ELEVATION_ERR_037:0, DET_ELEVATION_ERR_038:0, DET_ELEVATION_ERR_039:0, DET_ELEVATION_ERR_040:0, DET_EXISTENCE_PROB_037:0, DET_EXISTENCE_PROB_038:0, DET_EXISTENCE_PROB_039:0, DET_EXISTENCE_PROB_040:0, DET_HVC_FLAG_037:0, DET_HVC_FLAG_038:0, DET_HVC_FLAG_039:0, DET_HVC_FLAG_040:0, DET_MH_CRC16_037_040:0, DET_MH_CYCLE_COUNTER_037_040:0, DET_MH_SCAN_INDEX_4LSB_037_040:0, DET_OUTSIDE_SECTOR_037:0, DET_OUTSIDE_SECTOR_038:0, DET_OUTSIDE_SECTOR_039:0, DET_OUTSIDE_SECTOR_040:0, DET_POINT_TARGET_PROB_037:0, DET_POINT_TARGET_PROB_038:0, DET_POINT_TARGET_PROB_039:0, DET_POINT_TARGET_PROB_040:0, DET_RANGE_037:0, DET_RANGE_038:0, DET_RANGE_039:0, DET_RANGE_040:0, DET_RANGE_ERR_037:0, DET_RANGE_ERR_038:0, DET_RANGE_ERR_039:0, DET_RANGE_ERR_040:0, DET_RANGE_VELOCITY_037:16384, DET_RANGE_VELOCITY_038:16384, DET_RANGE_VELOCITY_039:16384, DET_RANGE_VELOCITY_040:16384, DET_RANGE_VELOCITY_ERR_037:0, DET_RANGE_VELOCITY_ERR_038:0, DET_RANGE_VELOCITY_ERR_039:0, DET_RANGE_VELOCITY_ERR_040:0, DET_RCS_037:128, DET_RCS_038:128, DET_RCS_039:128, DET_RCS_040:128, DET_SNR_037:0, DET_SNR_038:0, DET_SNR_039:0, DET_SNR_040:0, DET_SUPER_RES_TARGET_037:0, DET_SUPER_RES_TARGET_038:0, DET_SUPER_RES_TARGET_039:0, DET_SUPER_RES_TARGET_040:0, DET_VALID_FLAG_037:0, DET_VALID_FLAG_038:0, DET_VALID_FLAG_039:0, DET_VALID_FLAG_040:0]}, provided-interface=Pi_SG_Detections_037_040
      Pp_SG_Detections_041_044: nonqueued-sender-com-spec{data-element=Vdp_SG_Detections_041_044, init-value=fields=[DET_AZIMUTH_041:0, DET_AZIMUTH_042:0, DET_AZIMUTH_043:0, DET_AZIMUTH_044:0, DET_AZIMUTH_ERR_041:0, DET_AZIMUTH_ERR_042:0, DET_AZIMUTH_ERR_043:0, DET_AZIMUTH_ERR_044:0, DET_BI_STATIC_FLAG_041:0, DET_BI_STATIC_FLAG_042:0, DET_BI_STATIC_FLAG_043:0, DET_BI_STATIC_FLAG_044:0, DET_CONFD_AZIMUTH_041:0, DET_CONFD_AZIMUTH_042:0, DET_CONFD_AZIMUTH_043:0, DET_CONFD_AZIMUTH_044:0, DET_CONFD_ELEVATION_041:0, DET_CONFD_ELEVATION_042:0, DET_CONFD_ELEVATION_043:0, DET_CONFD_ELEVATION_044:0, DET_ELEVATION_041:0, DET_ELEVATION_042:0, DET_ELEVATION_043:0, DET_ELEVATION_044:0, DET_ELEVATION_ERR_041:0, DET_ELEVATION_ERR_042:0, DET_ELEVATION_ERR_043:0, DET_ELEVATION_ERR_044:0, DET_EXISTENCE_PROB_041:0, DET_EXISTENCE_PROB_042:0, DET_EXISTENCE_PROB_043:0, DET_EXISTENCE_PROB_044:0, DET_HVC_FLAG_041:0, DET_HVC_FLAG_042:0, DET_HVC_FLAG_043:0, DET_HVC_FLAG_044:0, DET_MH_CRC16_041_044:0, DET_MH_CYCLE_COUNTER_041_044:0, DET_MH_SCAN_INDEX_4LSB_041_044:0, DET_OUTSIDE_SECTOR_041:0, DET_OUTSIDE_SECTOR_042:0, DET_OUTSIDE_SECTOR_043:0, DET_OUTSIDE_SECTOR_044:0, DET_POINT_TARGET_PROB_041:0, DET_POINT_TARGET_PROB_042:0, DET_POINT_TARGET_PROB_043:0, DET_POINT_TARGET_PROB_044:0, DET_RANGE_041:0, DET_RANGE_042:0, DET_RANGE_043:0, DET_RANGE_044:0, DET_RANGE_ERR_041:0, DET_RANGE_ERR_042:0, DET_RANGE_ERR_043:0, DET_RANGE_ERR_044:0, DET_RANGE_VELOCITY_041:16384, DET_RANGE_VELOCITY_042:16384, DET_RANGE_VELOCITY_043:16384, DET_RANGE_VELOCITY_044:16384, DET_RANGE_VELOCITY_ERR_041:0, DET_RANGE_VELOCITY_ERR_042:0, DET_RANGE_VELOCITY_ERR_043:0, DET_RANGE_VELOCITY_ERR_044:0, DET_RCS_041:128, DET_RCS_042:128, DET_RCS_043:128, DET_RCS_044:128, DET_SNR_041:0, DET_SNR_042:0, DET_SNR_043:0, DET_SNR_044:0, DET_SUPER_RES_TARGET_041:0, DET_SUPER_RES_TARGET_042:0, DET_SUPER_RES_TARGET_043:0, DET_SUPER_RES_TARGET_044:0, DET_VALID_FLAG_041:0, DET_VALID_FLAG_042:0, DET_VALID_FLAG_043:0, DET_VALID_FLAG_044:0]}, provided-interface=Pi_SG_Detections_041_044
      Pp_SG_Detections_045_048: nonqueued-sender-com-spec{data-element=Vdp_SG_Detections_045_048, init-value=fields=[DET_AZIMUTH_045:0, DET_AZIMUTH_046:0, DET_AZIMUTH_047:0, DET_AZIMUTH_048:0, DET_AZIMUTH_ERR_045:0, DET_AZIMUTH_ERR_046:0, DET_AZIMUTH_ERR_047:0, DET_AZIMUTH_ERR_048:0, DET_BI_STATIC_FLAG_045:0, DET_BI_STATIC_FLAG_046:0, DET_BI_STATIC_FLAG_047:0, DET_BI_STATIC_FLAG_048:0, DET_CONFD_AZIMUTH_045:0, DET_CONFD_AZIMUTH_046:0, DET_CONFD_AZIMUTH_047:0, DET_CONFD_AZIMUTH_048:0, DET_CONFD_ELEVATION_045:0, DET_CONFD_ELEVATION_046:0, DET_CONFD_ELEVATION_047:0, DET_CONFD_ELEVATION_048:0, DET_ELEVATION_045:0, DET_ELEVATION_046:0, DET_ELEVATION_047:0, DET_ELEVATION_048:0, DET_ELEVATION_ERR_045:0, DET_ELEVATION_ERR_046:0, DET_ELEVATION_ERR_047:0, DET_ELEVATION_ERR_048:0, DET_EXISTENCE_PROB_045:0, DET_EXISTENCE_PROB_046:0, DET_EXISTENCE_PROB_047:0, DET_EXISTENCE_PROB_048:0, DET_HVC_FLAG_045:0, DET_HVC_FLAG_046:0, DET_HVC_FLAG_047:0, DET_HVC_FLAG_048:0, DET_MH_CRC16_045_048:0, DET_MH_CYCLE_COUNTER_045_048:0, DET_MH_SCAN_INDEX_4LSB_045_048:0, DET_OUTSIDE_SECTOR_045:0, DET_OUTSIDE_SECTOR_046:0, DET_OUTSIDE_SECTOR_047:0, DET_OUTSIDE_SECTOR_048:0, DET_POINT_TARGET_PROB_045:0, DET_POINT_TARGET_PROB_046:0, DET_POINT_TARGET_PROB_047:0, DET_POINT_TARGET_PROB_048:0, DET_RANGE_045:0, DET_RANGE_046:0, DET_RANGE_047:0, DET_RANGE_048:0, DET_RANGE_ERR_045:0, DET_RANGE_ERR_046:0, DET_RANGE_ERR_047:0, DET_RANGE_ERR_048:0, DET_RANGE_VELOCITY_045:16384, DET_RANGE_VELOCITY_046:16384, DET_RANGE_VELOCITY_047:16384, DET_RANGE_VELOCITY_048:16384, DET_RANGE_VELOCITY_ERR_045:0, DET_RANGE_VELOCITY_ERR_046:0, DET_RANGE_VELOCITY_ERR_047:0, DET_RANGE_VELOCITY_ERR_048:0, DET_RCS_045:128, DET_RCS_046:128, DET_RCS_047:128, DET_RCS_048:128, DET_SNR_045:0, DET_SNR_046:0, DET_SNR_047:0, DET_SNR_048:0, DET_SUPER_RES_TARGET_045:0, DET_SUPER_RES_TARGET_046:0, DET_SUPER_RES_TARGET_047:0, DET_SUPER_RES_TARGET_048:0, DET_VALID_FLAG_045:0, DET_VALID_FLAG_046:0, DET_VALID_FLAG_047:0, DET_VALID_FLAG_048:0]}, provided-interface=Pi_SG_Detections_045_048
      Pp_SG_Detections_049_052: nonqueued-sender-com-spec{data-element=Vdp_SG_Detections_049_052, init-value=fields=[DET_AZIMUTH_049:0, DET_AZIMUTH_050:0, DET_AZIMUTH_051:0, DET_AZIMUTH_052:0, DET_AZIMUTH_ERR_049:0, DET_AZIMUTH_ERR_050:0, DET_AZIMUTH_ERR_051:0, DET_AZIMUTH_ERR_052:0, DET_BI_STATIC_FLAG_049:0, DET_BI_STATIC_FLAG_050:0, DET_BI_STATIC_FLAG_051:0, DET_BI_STATIC_FLAG_052:0, DET_CONFD_AZIMUTH_049:0, DET_CONFD_AZIMUTH_050:0, DET_CONFD_AZIMUTH_051:0, DET_CONFD_AZIMUTH_052:0, DET_CONFD_ELEVATION_049:0, DET_CONFD_ELEVATION_050:0, DET_CONFD_ELEVATION_051:0, DET_CONFD_ELEVATION_052:0, DET_ELEVATION_049:0, DET_ELEVATION_050:0, DET_ELEVATION_051:0, DET_ELEVATION_052:0, DET_ELEVATION_ERR_049:0, DET_ELEVATION_ERR_050:0, DET_ELEVATION_ERR_051:0, DET_ELEVATION_ERR_052:0, DET_EXISTENCE_PROB_049:0, DET_EXISTENCE_PROB_050:0, DET_EXISTENCE_PROB_051:0, DET_EXISTENCE_PROB_052:0, DET_HVC_FLAG_049:0, DET_HVC_FLAG_050:0, DET_HVC_FLAG_051:0, DET_HVC_FLAG_052:0, DET_MH_CRC16_049_052:0, DET_MH_CYCLE_COUNTER_049_052:0, DET_MH_SCAN_INDEX_4LSB_049_052:0, DET_OUTSIDE_SECTOR_049:0, DET_OUTSIDE_SECTOR_050:0, DET_OUTSIDE_SECTOR_051:0, DET_OUTSIDE_SECTOR_052:0, DET_POINT_TARGET_PROB_049:0, DET_POINT_TARGET_PROB_050:0, DET_POINT_TARGET_PROB_051:0, DET_POINT_TARGET_PROB_052:0, DET_RANGE_049:0, DET_RANGE_050:0, DET_RANGE_051:0, DET_RANGE_052:0, DET_RANGE_ERR_049:0, DET_RANGE_ERR_050:0, DET_RANGE_ERR_051:0, DET_RANGE_ERR_052:0, DET_RANGE_VELOCITY_049:16384, DET_RANGE_VELOCITY_050:16384, DET_RANGE_VELOCITY_051:16384, DET_RANGE_VELOCITY_052:16384, DET_RANGE_VELOCITY_ERR_049:0, DET_RANGE_VELOCITY_ERR_050:0, DET_RANGE_VELOCITY_ERR_051:0, DET_RANGE_VELOCITY_ERR_052:0, DET_RCS_049:128, DET_RCS_050:128, DET_RCS_051:128, DET_RCS_052:128, DET_SNR_049:0, DET_SNR_050:0, DET_SNR_051:0, DET_SNR_052:0, DET_SUPER_RES_TARGET_049:0, DET_SUPER_RES_TARGET_050:0, DET_SUPER_RES_TARGET_051:0, DET_SUPER_RES_TARGET_052:0, DET_VALID_FLAG_049:0, DET_VALID_FLAG_050:0, DET_VALID_FLAG_051:0, DET_VALID_FLAG_052:0]}, provided-interface=Pi_SG_Detections_049_052
      Pp_SG_Detections_053_056: nonqueued-sender-com-spec{data-element=Vdp_SG_Detections_053_056, init-value=fields=[DET_AZIMUTH_053:0, DET_AZIMUTH_054:0, DET_AZIMUTH_055:0, DET_AZIMUTH_056:0, DET_AZIMUTH_ERR_053:0, DET_AZIMUTH_ERR_054:0, DET_AZIMUTH_ERR_055:0, DET_AZIMUTH_ERR_056:0, DET_BI_STATIC_FLAG_053:0, DET_BI_STATIC_FLAG_054:0, DET_BI_STATIC_FLAG_055:0, DET_BI_STATIC_FLAG_056:0, DET_CONFD_AZIMUTH_053:0, DET_CONFD_AZIMUTH_054:0, DET_CONFD_AZIMUTH_055:0, DET_CONFD_AZIMUTH_056:0, DET_CONFD_ELEVATION_053:0, DET_CONFD_ELEVATION_054:0, DET_CONFD_ELEVATION_055:0, DET_CONFD_ELEVATION_056:0, DET_ELEVATION_053:0, DET_ELEVATION_054:0, DET_ELEVATION_055:0, DET_ELEVATION_056:0, DET_ELEVATION_ERR_053:0, DET_ELEVATION_ERR_054:0, DET_ELEVATION_ERR_055:0, DET_ELEVATION_ERR_056:0, DET_EXISTENCE_PROB_053:0, DET_EXISTENCE_PROB_054:0, DET_EXISTENCE_PROB_055:0, DET_EXISTENCE_PROB_056:0, DET_HVC_FLAG_053:0, DET_HVC_FLAG_054:0, DET_HVC_FLAG_055:0, DET_HVC_FLAG_056:0, DET_MH_CRC16_053_056:0, DET_MH_CYCLE_COUNTER_053_056:0, DET_MH_SCAN_INDEX_4LSB_053_056:0, DET_OUTSIDE_SECTOR_053:0, DET_OUTSIDE_SECTOR_054:0, DET_OUTSIDE_SECTOR_055:0, DET_OUTSIDE_SECTOR_056:0, DET_POINT_TARGET_PROB_053:0, DET_POINT_TARGET_PROB_054:0, DET_POINT_TARGET_PROB_055:0, DET_POINT_TARGET_PROB_056:0, DET_RANGE_053:0, DET_RANGE_054:0, DET_RANGE_055:0, DET_RANGE_056:0, DET_RANGE_ERR_053:0, DET_RANGE_ERR_054:0, DET_RANGE_ERR_055:0, DET_RANGE_ERR_056:0, DET_RANGE_VELOCITY_053:16384, DET_RANGE_VELOCITY_054:16384, DET_RANGE_VELOCITY_055:16384, DET_RANGE_VELOCITY_056:16384, DET_RANGE_VELOCITY_ERR_053:0, DET_RANGE_VELOCITY_ERR_054:0, DET_RANGE_VELOCITY_ERR_055:0, DET_RANGE_VELOCITY_ERR_056:0, DET_RCS_053:128, DET_RCS_054:128, DET_RCS_055:128, DET_RCS_056:128, DET_SNR_053:0, DET_SNR_054:0, DET_SNR_055:0, DET_SNR_056:0, DET_SUPER_RES_TARGET_053:0, DET_SUPER_RES_TARGET_054:0, DET_SUPER_RES_TARGET_055:0, DET_SUPER_RES_TARGET_056:0, DET_VALID_FLAG_053:0, DET_VALID_FLAG_054:0, DET_VALID_FLAG_055:0, DET_VALID_FLAG_056:0]}, provided-interface=Pi_SG_Detections_053_056
      Pp_SG_Detections_057_060: nonqueued-sender-com-spec{data-element=Vdp_SG_Detections_057_060, init-value=fields=[DET_AZIMUTH_057:0, DET_AZIMUTH_058:0, DET_AZIMUTH_059:0, DET_AZIMUTH_060:0, DET_AZIMUTH_ERR_057:0, DET_AZIMUTH_ERR_058:0, DET_AZIMUTH_ERR_059:0, DET_AZIMUTH_ERR_060:0, DET_BI_STATIC_FLAG_057:0, DET_BI_STATIC_FLAG_058:0, DET_BI_STATIC_FLAG_059:0, DET_BI_STATIC_FLAG_060:0, DET_CONFD_AZIMUTH_057:0, DET_CONFD_AZIMUTH_058:0, DET_CONFD_AZIMUTH_059:0, DET_CONFD_AZIMUTH_060:0, DET_CONFD_ELEVATION_057:0, DET_CONFD_ELEVATION_058:0, DET_CONFD_ELEVATION_059:0, DET_CONFD_ELEVATION_060:0, DET_ELEVATION_057:0, DET_ELEVATION_058:0, DET_ELEVATION_059:0, DET_ELEVATION_060:0, DET_ELEVATION_ERR_057:0, DET_ELEVATION_ERR_058:0, DET_ELEVATION_ERR_059:0, DET_ELEVATION_ERR_060:0, DET_EXISTENCE_PROB_057:0, DET_EXISTENCE_PROB_058:0, DET_EXISTENCE_PROB_059:0, DET_EXISTENCE_PROB_060:0, DET_HVC_FLAG_057:0, DET_HVC_FLAG_058:0, DET_HVC_FLAG_059:0, DET_HVC_FLAG_060:0, DET_MH_CRC16_057_060:0, DET_MH_CYCLE_COUNTER_057_060:0, DET_MH_SCAN_INDEX_4LSB_057_060:0, DET_OUTSIDE_SECTOR_057:0, DET_OUTSIDE_SECTOR_058:0, DET_OUTSIDE_SECTOR_059:0, DET_OUTSIDE_SECTOR_060:0, DET_POINT_TARGET_PROB_057:0, DET_POINT_TARGET_PROB_058:0, DET_POINT_TARGET_PROB_059:0, DET_POINT_TARGET_PROB_060:0, DET_RANGE_057:0, DET_RANGE_058:0, DET_RANGE_059:0, DET_RANGE_060:0, DET_RANGE_ERR_057:0, DET_RANGE_ERR_058:0, DET_RANGE_ERR_059:0, DET_RANGE_ERR_060:0, DET_RANGE_VELOCITY_057:16384, DET_RANGE_VELOCITY_058:16384, DET_RANGE_VELOCITY_059:16384, DET_RANGE_VELOCITY_060:16384, DET_RANGE_VELOCITY_ERR_057:0, DET_RANGE_VELOCITY_ERR_058:0, DET_RANGE_VELOCITY_ERR_059:0, DET_RANGE_VELOCITY_ERR_060:0, DET_RCS_057:128, DET_RCS_058:128, DET_RCS_059:128, DET_RCS_060:128, DET_SNR_057:0, DET_SNR_058:0, DET_SNR_059:0, DET_SNR_060:0, DET_SUPER_RES_TARGET_057:0, DET_SUPER_RES_TARGET_058:0, DET_SUPER_RES_TARGET_059:0, DET_SUPER_RES_TARGET_060:0, DET_VALID_FLAG_057:0, DET_VALID_FLAG_058:0, DET_VALID_FLAG_059:0, DET_VALID_FLAG_060:0]}, provided-interface=Pi_SG_Detections_057_060
      Pp_SG_Detections_061_064: nonqueued-sender-com-spec{data-element=Vdp_SG_Detections_061_064, init-value=fields=[DET_AZIMUTH_061:0, DET_AZIMUTH_062:0, DET_AZIMUTH_063:0, DET_AZIMUTH_064:0, DET_AZIMUTH_ERR_061:0, DET_AZIMUTH_ERR_062:0, DET_AZIMUTH_ERR_063:0, DET_AZIMUTH_ERR_064:0, DET_BI_STATIC_FLAG_061:0, DET_BI_STATIC_FLAG_062:0, DET_BI_STATIC_FLAG_063:0, DET_BI_STATIC_FLAG_064:0, DET_CONFD_AZIMUTH_061:0, DET_CONFD_AZIMUTH_062:0, DET_CONFD_AZIMUTH_063:0, DET_CONFD_AZIMUTH_064:0, DET_CONFD_ELEVATION_061:0, DET_CONFD_ELEVATION_062:0, DET_CONFD_ELEVATION_063:0, DET_CONFD_ELEVATION_064:0, DET_ELEVATION_061:0, DET_ELEVATION_062:0, DET_ELEVATION_063:0, DET_ELEVATION_064:0, DET_ELEVATION_ERR_061:0, DET_ELEVATION_ERR_062:0, DET_ELEVATION_ERR_063:0, DET_ELEVATION_ERR_064:0, DET_EXISTENCE_PROB_061:0, DET_EXISTENCE_PROB_062:0, DET_EXISTENCE_PROB_063:0, DET_EXISTENCE_PROB_064:0, DET_HVC_FLAG_061:0, DET_HVC_FLAG_062:0, DET_HVC_FLAG_063:0, DET_HVC_FLAG_064:0, DET_MH_CRC16_061_064:0, DET_MH_CYCLE_COUNTER_061_064:0, DET_MH_SCAN_INDEX_4LSB_061_064:0, DET_OUTSIDE_SECTOR_061:0, DET_OUTSIDE_SECTOR_062:0, DET_OUTSIDE_SECTOR_063:0, DET_OUTSIDE_SECTOR_064:0, DET_POINT_TARGET_PROB_061:0, DET_POINT_TARGET_PROB_062:0, DET_POINT_TARGET_PROB_063:0, DET_POINT_TARGET_PROB_064:0, DET_RANGE_061:0, DET_RANGE_062:0, DET_RANGE_063:0, DET_RANGE_064:0, DET_RANGE_ERR_061:0, DET_RANGE_ERR_062:0, DET_RANGE_ERR_063:0, DET_RANGE_ERR_064:0, DET_RANGE_VELOCITY_061:16384, DET_RANGE_VELOCITY_062:16384, DET_RANGE_VELOCITY_063:16384, DET_RANGE_VELOCITY_064:16384, DET_RANGE_VELOCITY_ERR_061:0, DET_RANGE_VELOCITY_ERR_062:0, DET_RANGE_VELOCITY_ERR_063:0, DET_RANGE_VELOCITY_ERR_064:0, DET_RCS_061:128, DET_RCS_062:128, DET_RCS_063:128, DET_RCS_064:128, DET_SNR_061:0, DET_SNR_062:0, DET_SNR_063:0, DET_SNR_064:0, DET_SUPER_RES_TARGET_061:0, DET_SUPER_RES_TARGET_062:0, DET_SUPER_RES_TARGET_063:0, DET_SUPER_RES_TARGET_064:0, DET_VALID_FLAG_061:0, DET_VALID_FLAG_062:0, DET_VALID_FLAG_063:0, DET_VALID_FLAG_064:0]}, provided-interface=Pi_SG_Detections_061_064
      Pp_SG_Detections_065_068: nonqueued-sender-com-spec{data-element=Vdp_SG_Detections_065_068, init-value=fields=[DET_AZIMUTH_065:0, DET_AZIMUTH_066:0, DET_AZIMUTH_067:0, DET_AZIMUTH_068:0, DET_AZIMUTH_ERR_065:0, DET_AZIMUTH_ERR_066:0, DET_AZIMUTH_ERR_067:0, DET_AZIMUTH_ERR_068:0, DET_BI_STATIC_FLAG_065:0, DET_BI_STATIC_FLAG_066:0, DET_BI_STATIC_FLAG_067:0, DET_BI_STATIC_FLAG_068:0, DET_CONFD_AZIMUTH_065:0, DET_CONFD_AZIMUTH_066:0, DET_CONFD_AZIMUTH_067:0, DET_CONFD_AZIMUTH_068:0, DET_CONFD_ELEVATION_065:0, DET_CONFD_ELEVATION_066:0, DET_CONFD_ELEVATION_067:0, DET_CONFD_ELEVATION_068:0, DET_ELEVATION_065:0, DET_ELEVATION_066:0, DET_ELEVATION_067:0, DET_ELEVATION_068:0, DET_ELEVATION_ERR_065:0, DET_ELEVATION_ERR_066:0, DET_ELEVATION_ERR_067:0, DET_ELEVATION_ERR_068:0, DET_EXISTENCE_PROB_065:0, DET_EXISTENCE_PROB_066:0, DET_EXISTENCE_PROB_067:0, DET_EXISTENCE_PROB_068:0, DET_HVC_FLAG_065:0, DET_HVC_FLAG_066:0, DET_HVC_FLAG_067:0, DET_HVC_FLAG_068:0, DET_MH_CRC16_065_068:0, DET_MH_CYCLE_COUNTER_065_068:0, DET_MH_SCAN_INDEX_4LSB_065_068:0, DET_OUTSIDE_SECTOR_065:0, DET_OUTSIDE_SECTOR_066:0, DET_OUTSIDE_SECTOR_067:0, DET_OUTSIDE_SECTOR_068:0, DET_POINT_TARGET_PROB_065:0, DET_POINT_TARGET_PROB_066:0, DET_POINT_TARGET_PROB_067:0, DET_POINT_TARGET_PROB_068:0, DET_RANGE_065:0, DET_RANGE_066:0, DET_RANGE_067:0, DET_RANGE_068:0, DET_RANGE_ERR_065:0, DET_RANGE_ERR_066:0, DET_RANGE_ERR_067:0, DET_RANGE_ERR_068:0, DET_RANGE_VELOCITY_065:16384, DET_RANGE_VELOCITY_066:16384, DET_RANGE_VELOCITY_067:16384, DET_RANGE_VELOCITY_068:16384, DET_RANGE_VELOCITY_ERR_065:0, DET_RANGE_VELOCITY_ERR_066:0, DET_RANGE_VELOCITY_ERR_067:0, DET_RANGE_VELOCITY_ERR_068:0, DET_RCS_065:128, DET_RCS_066:128, DET_RCS_067:128, DET_RCS_068:128, DET_SNR_065:0, DET_SNR_066:0, DET_SNR_067:0, DET_SNR_068:0, DET_SUPER_RES_TARGET_065:0, DET_SUPER_RES_TARGET_066:0, DET_SUPER_RES_TARGET_067:0, DET_SUPER_RES_TARGET_068:0, DET_VALID_FLAG_065:0, DET_VALID_FLAG_066:0, DET_VALID_FLAG_067:0, DET_VALID_FLAG_068:0]}, provided-interface=Pi_SG_Detections_065_068
      Pp_SG_Detections_069_072: nonqueued-sender-com-spec{data-element=Vdp_SG_Detections_069_072, init-value=fields=[DET_AZIMUTH_069:0, DET_AZIMUTH_070:0, DET_AZIMUTH_071:0, DET_AZIMUTH_072:0, DET_AZIMUTH_ERR_069:0, DET_AZIMUTH_ERR_070:0, DET_AZIMUTH_ERR_071:0, DET_AZIMUTH_ERR_072:0, DET_BI_STATIC_FLAG_069:0, DET_BI_STATIC_FLAG_070:0, DET_BI_STATIC_FLAG_071:0, DET_BI_STATIC_FLAG_072:0, DET_CONFD_AZIMUTH_069:0, DET_CONFD_AZIMUTH_070:0, DET_CONFD_AZIMUTH_071:0, DET_CONFD_AZIMUTH_072:0, DET_CONFD_ELEVATION_069:0, DET_CONFD_ELEVATION_070:0, DET_CONFD_ELEVATION_071:0, DET_CONFD_ELEVATION_072:0, DET_ELEVATION_069:0, DET_ELEVATION_070:0, DET_ELEVATION_071:0, DET_ELEVATION_072:0, DET_ELEVATION_ERR_069:0, DET_ELEVATION_ERR_070:0, DET_ELEVATION_ERR_071:0, DET_ELEVATION_ERR_072:0, DET_EXISTENCE_PROB_069:0, DET_EXISTENCE_PROB_070:0, DET_EXISTENCE_PROB_071:0, DET_EXISTENCE_PROB_072:0, DET_HVC_FLAG_069:0, DET_HVC_FLAG_070:0, DET_HVC_FLAG_071:0, DET_HVC_FLAG_072:0, DET_MH_CRC16_069_072:0, DET_MH_CYCLE_COUNTER_069_072:0, DET_MH_SCAN_INDEX_4LSB_069_072:0, DET_OUTSIDE_SECTOR_069:0, DET_OUTSIDE_SECTOR_070:0, DET_OUTSIDE_SECTOR_071:0, DET_OUTSIDE_SECTOR_072:0, DET_POINT_TARGET_PROB_069:0, DET_POINT_TARGET_PROB_070:0, DET_POINT_TARGET_PROB_071:0, DET_POINT_TARGET_PROB_072:0, DET_RANGE_069:0, DET_RANGE_070:0, DET_RANGE_071:0, DET_RANGE_072:0, DET_RANGE_ERR_069:0, DET_RANGE_ERR_070:0, DET_RANGE_ERR_071:0, DET_RANGE_ERR_072:0, DET_RANGE_VELOCITY_069:16384, DET_RANGE_VELOCITY_070:16384, DET_RANGE_VELOCITY_071:16384, DET_RANGE_VELOCITY_072:16384, DET_RANGE_VELOCITY_ERR_069:0, DET_RANGE_VELOCITY_ERR_070:0, DET_RANGE_VELOCITY_ERR_071:0, DET_RANGE_VELOCITY_ERR_072:0, DET_RCS_069:128, DET_RCS_070:128, DET_RCS_071:128, DET_RCS_072:128, DET_SNR_069:0, DET_SNR_070:0, DET_SNR_071:0, DET_SNR_072:0, DET_SUPER_RES_TARGET_069:0, DET_SUPER_RES_TARGET_070:0, DET_SUPER_RES_TARGET_071:0, DET_SUPER_RES_TARGET_072:0, DET_VALID_FLAG_069:0, DET_VALID_FLAG_070:0, DET_VALID_FLAG_071:0, DET_VALID_FLAG_072:0]}, provided-interface=Pi_SG_Detections_069_072
      Pp_SG_Detections_073_076: nonqueued-sender-com-spec{data-element=Vdp_SG_Detections_073_076, init-value=fields=[DET_AZIMUTH_073:0, DET_AZIMUTH_074:0, DET_AZIMUTH_075:0, DET_AZIMUTH_076:0, DET_AZIMUTH_ERR_073:0, DET_AZIMUTH_ERR_074:0, DET_AZIMUTH_ERR_075:0, DET_AZIMUTH_ERR_076:0, DET_BI_STATIC_FLAG_073:0, DET_BI_STATIC_FLAG_074:0, DET_BI_STATIC_FLAG_075:0, DET_BI_STATIC_FLAG_076:0, DET_CONFD_AZIMUTH_073:0, DET_CONFD_AZIMUTH_074:0, DET_CONFD_AZIMUTH_075:0, DET_CONFD_AZIMUTH_076:0, DET_CONFD_ELEVATION_073:0, DET_CONFD_ELEVATION_074:0, DET_CONFD_ELEVATION_075:0, DET_CONFD_ELEVATION_076:0, DET_ELEVATION_073:0, DET_ELEVATION_074:0, DET_ELEVATION_075:0, DET_ELEVATION_076:0, DET_ELEVATION_ERR_073:0, DET_ELEVATION_ERR_074:0, DET_ELEVATION_ERR_075:0, DET_ELEVATION_ERR_076:0, DET_EXISTENCE_PROB_073:0, DET_EXISTENCE_PROB_074:0, DET_EXISTENCE_PROB_075:0, DET_EXISTENCE_PROB_076:0, DET_HVC_FLAG_073:0, DET_HVC_FLAG_074:0, DET_HVC_FLAG_075:0, DET_HVC_FLAG_076:0, DET_MH_CRC16_073_076:0, DET_MH_CYCLE_COUNTER_073_076:0, DET_MH_SCAN_INDEX_4LSB_073_076:0, DET_OUTSIDE_SECTOR_073:0, DET_OUTSIDE_SECTOR_074:0, DET_OUTSIDE_SECTOR_075:0, DET_OUTSIDE_SECTOR_076:0, DET_POINT_TARGET_PROB_073:0, DET_POINT_TARGET_PROB_074:0, DET_POINT_TARGET_PROB_075:0, DET_POINT_TARGET_PROB_076:0, DET_RANGE_073:0, DET_RANGE_074:0, DET_RANGE_075:0, DET_RANGE_076:0, DET_RANGE_ERR_073:0, DET_RANGE_ERR_074:0, DET_RANGE_ERR_075:0, DET_RANGE_ERR_076:0, DET_RANGE_VELOCITY_073:16384, DET_RANGE_VELOCITY_074:16384, DET_RANGE_VELOCITY_075:16384, DET_RANGE_VELOCITY_076:16384, DET_RANGE_VELOCITY_ERR_073:0, DET_RANGE_VELOCITY_ERR_074:0, DET_RANGE_VELOCITY_ERR_075:0, DET_RANGE_VELOCITY_ERR_076:0, DET_RCS_073:128, DET_RCS_074:128, DET_RCS_075:128, DET_RCS_076:128, DET_SNR_073:0, DET_SNR_074:0, DET_SNR_075:0, DET_SNR_076:0, DET_SUPER_RES_TARGET_073:0, DET_SUPER_RES_TARGET_074:0, DET_SUPER_RES_TARGET_075:0, DET_SUPER_RES_TARGET_076:0, DET_VALID_FLAG_073:0, DET_VALID_FLAG_074:0, DET_VALID_FLAG_075:0, DET_VALID_FLAG_076:0]}, provided-interface=Pi_SG_Detections_073_076
      Pp_SG_Detections_077_080: nonqueued-sender-com-spec{data-element=Vdp_SG_Detections_077_080, init-value=fields=[DET_AZIMUTH_077:0, DET_AZIMUTH_078:0, DET_AZIMUTH_079:0, DET_AZIMUTH_080:0, DET_AZIMUTH_ERR_077:0, DET_AZIMUTH_ERR_078:0, DET_AZIMUTH_ERR_079:0, DET_AZIMUTH_ERR_080:0, DET_BI_STATIC_FLAG_077:0, DET_BI_STATIC_FLAG_078:0, DET_BI_STATIC_FLAG_079:0, DET_BI_STATIC_FLAG_080:0, DET_CONFD_AZIMUTH_077:0, DET_CONFD_AZIMUTH_078:0, DET_CONFD_AZIMUTH_079:0, DET_CONFD_AZIMUTH_080:0, DET_CONFD_ELEVATION_077:0, DET_CONFD_ELEVATION_078:0, DET_CONFD_ELEVATION_079:0, DET_CONFD_ELEVATION_080:0, DET_ELEVATION_077:0, DET_ELEVATION_078:0, DET_ELEVATION_079:0, DET_ELEVATION_080:0, DET_ELEVATION_ERR_077:0, DET_ELEVATION_ERR_078:0, DET_ELEVATION_ERR_079:0, DET_ELEVATION_ERR_080:0, DET_EXISTENCE_PROB_077:0, DET_EXISTENCE_PROB_078:0, DET_EXISTENCE_PROB_079:0, DET_EXISTENCE_PROB_080:0, DET_HVC_FLAG_077:0, DET_HVC_FLAG_078:0, DET_HVC_FLAG_079:0, DET_HVC_FLAG_080:0, DET_MH_CRC16_077_080:0, DET_MH_CYCLE_COUNTER_077_080:0, DET_MH_SCAN_INDEX_4LSB_077_080:0, DET_OUTSIDE_SECTOR_077:0, DET_OUTSIDE_SECTOR_078:0, DET_OUTSIDE_SECTOR_079:0, DET_OUTSIDE_SECTOR_080:0, DET_POINT_TARGET_PROB_077:0, DET_POINT_TARGET_PROB_078:0, DET_POINT_TARGET_PROB_079:0, DET_POINT_TARGET_PROB_080:0, DET_RANGE_077:0, DET_RANGE_078:0, DET_RANGE_079:0, DET_RANGE_080:0, DET_RANGE_ERR_077:0, DET_RANGE_ERR_078:0, DET_RANGE_ERR_079:0, DET_RANGE_ERR_080:0, DET_RANGE_VELOCITY_077:16384, DET_RANGE_VELOCITY_078:16384, DET_RANGE_VELOCITY_079:16384, DET_RANGE_VELOCITY_080:16384, DET_RANGE_VELOCITY_ERR_077:0, DET_RANGE_VELOCITY_ERR_078:0, DET_RANGE_VELOCITY_ERR_079:0, DET_RANGE_VELOCITY_ERR_080:0, DET_RCS_077:128, DET_RCS_078:128, DET_RCS_079:128, DET_RCS_080:128, DET_SNR_077:0, DET_SNR_078:0, DET_SNR_079:0, DET_SNR_080:0, DET_SUPER_RES_TARGET_077:0, DET_SUPER_RES_TARGET_078:0, DET_SUPER_RES_TARGET_079:0, DET_SUPER_RES_TARGET_080:0, DET_VALID_FLAG_077:0, DET_VALID_FLAG_078:0, DET_VALID_FLAG_079:0, DET_VALID_FLAG_080:0]}, provided-interface=Pi_SG_Detections_077_080
      Pp_SG_Detections_081_084: nonqueued-sender-com-spec{data-element=Vdp_SG_Detections_081_084, init-value=fields=[DET_AZIMUTH_081:0, DET_AZIMUTH_082:0, DET_AZIMUTH_083:0, DET_AZIMUTH_084:0, DET_AZIMUTH_ERR_081:0, DET_AZIMUTH_ERR_082:0, DET_AZIMUTH_ERR_083:0, DET_AZIMUTH_ERR_084:0, DET_BI_STATIC_FLAG_081:0, DET_BI_STATIC_FLAG_082:0, DET_BI_STATIC_FLAG_083:0, DET_BI_STATIC_FLAG_084:0, DET_CONFD_AZIMUTH_081:0, DET_CONFD_AZIMUTH_082:0, DET_CONFD_AZIMUTH_083:0, DET_CONFD_AZIMUTH_084:0, DET_CONFD_ELEVATION_081:0, DET_CONFD_ELEVATION_082:0, DET_CONFD_ELEVATION_083:0, DET_CONFD_ELEVATION_084:0, DET_ELEVATION_081:0, DET_ELEVATION_082:0, DET_ELEVATION_083:0, DET_ELEVATION_084:0, DET_ELEVATION_ERR_081:0, DET_ELEVATION_ERR_082:0, DET_ELEVATION_ERR_083:0, DET_ELEVATION_ERR_084:0, DET_EXISTENCE_PROB_081:0, DET_EXISTENCE_PROB_082:0, DET_EXISTENCE_PROB_083:0, DET_EXISTENCE_PROB_084:0, DET_HVC_FLAG_081:0, DET_HVC_FLAG_082:0, DET_HVC_FLAG_083:0, DET_HVC_FLAG_084:0, DET_MH_CRC16_081_084:0, DET_MH_CYCLE_COUNTER_081_084:0, DET_MH_SCAN_INDEX_4LSB_081_084:0, DET_OUTSIDE_SECTOR_081:0, DET_OUTSIDE_SECTOR_082:0, DET_OUTSIDE_SECTOR_083:0, DET_OUTSIDE_SECTOR_084:0, DET_POINT_TARGET_PROB_081:0, DET_POINT_TARGET_PROB_082:0, DET_POINT_TARGET_PROB_083:0, DET_POINT_TARGET_PROB_084:0, DET_RANGE_081:0, DET_RANGE_082:0, DET_RANGE_083:0, DET_RANGE_084:0, DET_RANGE_ERR_081:0, DET_RANGE_ERR_082:0, DET_RANGE_ERR_083:0, DET_RANGE_ERR_084:0, DET_RANGE_VELOCITY_081:16384, DET_RANGE_VELOCITY_082:16384, DET_RANGE_VELOCITY_083:16384, DET_RANGE_VELOCITY_084:16384, DET_RANGE_VELOCITY_ERR_081:0, DET_RANGE_VELOCITY_ERR_082:0, DET_RANGE_VELOCITY_ERR_083:0, DET_RANGE_VELOCITY_ERR_084:0, DET_RCS_081:128, DET_RCS_082:128, DET_RCS_083:128, DET_RCS_084:128, DET_SNR_081:0, DET_SNR_082:0, DET_SNR_083:0, DET_SNR_084:0, DET_SUPER_RES_TARGET_081:0, DET_SUPER_RES_TARGET_082:0, DET_SUPER_RES_TARGET_083:0, DET_SUPER_RES_TARGET_084:0, DET_VALID_FLAG_081:0, DET_VALID_FLAG_082:0, DET_VALID_FLAG_083:0, DET_VALID_FLAG_084:0]}, provided-interface=Pi_SG_Detections_081_084
      Pp_SG_Detections_085_088: nonqueued-sender-com-spec{data-element=Vdp_SG_Detections_085_088, init-value=fields=[DET_AZIMUTH_085:0, DET_AZIMUTH_086:0, DET_AZIMUTH_087:0, DET_AZIMUTH_088:0, DET_AZIMUTH_ERR_085:0, DET_AZIMUTH_ERR_086:0, DET_AZIMUTH_ERR_087:0, DET_AZIMUTH_ERR_088:0, DET_BI_STATIC_FLAG_085:0, DET_BI_STATIC_FLAG_086:0, DET_BI_STATIC_FLAG_087:0, DET_BI_STATIC_FLAG_088:0, DET_CONFD_AZIMUTH_085:0, DET_CONFD_AZIMUTH_086:0, DET_CONFD_AZIMUTH_087:0, DET_CONFD_AZIMUTH_088:0, DET_CONFD_ELEVATION_085:0, DET_CONFD_ELEVATION_086:0, DET_CONFD_ELEVATION_087:0, DET_CONFD_ELEVATION_088:0, DET_ELEVATION_085:0, DET_ELEVATION_086:0, DET_ELEVATION_087:0, DET_ELEVATION_088:0, DET_ELEVATION_ERR_085:0, DET_ELEVATION_ERR_086:0, DET_ELEVATION_ERR_087:0, DET_ELEVATION_ERR_088:0, DET_EXISTENCE_PROB_085:0, DET_EXISTENCE_PROB_086:0, DET_EXISTENCE_PROB_087:0, DET_EXISTENCE_PROB_088:0, DET_HVC_FLAG_085:0, DET_HVC_FLAG_086:0, DET_HVC_FLAG_087:0, DET_HVC_FLAG_088:0, DET_MH_CRC16_085_088:0, DET_MH_CYCLE_COUNTER_085_088:0, DET_MH_SCAN_INDEX_4LSB_085_088:0, DET_OUTSIDE_SECTOR_085:0, DET_OUTSIDE_SECTOR_086:0, DET_OUTSIDE_SECTOR_087:0, DET_OUTSIDE_SECTOR_088:0, DET_POINT_TARGET_PROB_085:0, DET_POINT_TARGET_PROB_086:0, DET_POINT_TARGET_PROB_087:0, DET_POINT_TARGET_PROB_088:0, DET_RANGE_085:0, DET_RANGE_086:0, DET_RANGE_087:0, DET_RANGE_088:0, DET_RANGE_ERR_085:0, DET_RANGE_ERR_086:0, DET_RANGE_ERR_087:0, DET_RANGE_ERR_088:0, DET_RANGE_VELOCITY_085:16384, DET_RANGE_VELOCITY_086:16384, DET_RANGE_VELOCITY_087:16384, DET_RANGE_VELOCITY_088:16384, DET_RANGE_VELOCITY_ERR_085:0, DET_RANGE_VELOCITY_ERR_086:0, DET_RANGE_VELOCITY_ERR_087:0, DET_RANGE_VELOCITY_ERR_088:0, DET_RCS_085:128, DET_RCS_086:128, DET_RCS_087:128, DET_RCS_088:128, DET_SNR_085:0, DET_SNR_086:0, DET_SNR_087:0, DET_SNR_088:0, DET_SUPER_RES_TARGET_085:0, DET_SUPER_RES_TARGET_086:0, DET_SUPER_RES_TARGET_087:0, DET_SUPER_RES_TARGET_088:0, DET_VALID_FLAG_085:0, DET_VALID_FLAG_086:0, DET_VALID_FLAG_087:0, DET_VALID_FLAG_088:0]}, provided-interface=Pi_SG_Detections_085_088
      Pp_SG_Detections_089_092: nonqueued-sender-com-spec{data-element=Vdp_SG_Detections_089_092, init-value=fields=[DET_AZIMUTH_089:0, DET_AZIMUTH_090:0, DET_AZIMUTH_091:0, DET_AZIMUTH_092:0, DET_AZIMUTH_ERR_089:0, DET_AZIMUTH_ERR_090:0, DET_AZIMUTH_ERR_091:0, DET_AZIMUTH_ERR_092:0, DET_BI_STATIC_FLAG_089:0, DET_BI_STATIC_FLAG_090:0, DET_BI_STATIC_FLAG_091:0, DET_BI_STATIC_FLAG_092:0, DET_CONFD_AZIMUTH_089:0, DET_CONFD_AZIMUTH_090:0, DET_CONFD_AZIMUTH_091:0, DET_CONFD_AZIMUTH_092:0, DET_CONFD_ELEVATION_089:0, DET_CONFD_ELEVATION_090:0, DET_CONFD_ELEVATION_091:0, DET_CONFD_ELEVATION_092:0, DET_ELEVATION_089:0, DET_ELEVATION_090:0, DET_ELEVATION_091:0, DET_ELEVATION_092:0, DET_ELEVATION_ERR_089:0, DET_ELEVATION_ERR_090:0, DET_ELEVATION_ERR_091:0, DET_ELEVATION_ERR_092:0, DET_EXISTENCE_PROB_089:0, DET_EXISTENCE_PROB_090:0, DET_EXISTENCE_PROB_091:0, DET_EXISTENCE_PROB_092:0, DET_HVC_FLAG_089:0, DET_HVC_FLAG_090:0, DET_HVC_FLAG_091:0, DET_HVC_FLAG_092:0, DET_MH_CRC16_089_092:0, DET_MH_CYCLE_COUNTER_089_092:0, DET_MH_SCAN_INDEX_4LSB_089_092:0, DET_OUTSIDE_SECTOR_089:0, DET_OUTSIDE_SECTOR_090:0, DET_OUTSIDE_SECTOR_091:0, DET_OUTSIDE_SECTOR_092:0, DET_POINT_TARGET_PROB_089:0, DET_POINT_TARGET_PROB_090:0, DET_POINT_TARGET_PROB_091:0, DET_POINT_TARGET_PROB_092:0, DET_RANGE_089:0, DET_RANGE_090:0, DET_RANGE_091:0, DET_RANGE_092:0, DET_RANGE_ERR_089:0, DET_RANGE_ERR_090:0, DET_RANGE_ERR_091:0, DET_RANGE_ERR_092:0, DET_RANGE_VELOCITY_089:16384, DET_RANGE_VELOCITY_090:16384, DET_RANGE_VELOCITY_091:16384, DET_RANGE_VELOCITY_092:16384, DET_RANGE_VELOCITY_ERR_089:0, DET_RANGE_VELOCITY_ERR_090:0, DET_RANGE_VELOCITY_ERR_091:0, DET_RANGE_VELOCITY_ERR_092:0, DET_RCS_089:128, DET_RCS_090:128, DET_RCS_091:128, DET_RCS_092:128, DET_SNR_089:0, DET_SNR_090:0, DET_SNR_091:0, DET_SNR_092:0, DET_SUPER_RES_TARGET_089:0, DET_SUPER_RES_TARGET_090:0, DET_SUPER_RES_TARGET_091:0, DET_SUPER_RES_TARGET_092:0, DET_VALID_FLAG_089:0, DET_VALID_FLAG_090:0, DET_VALID_FLAG_091:0, DET_VALID_FLAG_092:0]}, provided-interface=Pi_SG_Detections_089_092
      Pp_SG_Detections_093_096: nonqueued-sender-com-spec{data-element=Vdp_SG_Detections_093_096, init-value=fields=[DET_AZIMUTH_093:0, DET_AZIMUTH_094:0, DET_AZIMUTH_095:0, DET_AZIMUTH_096:0, DET_AZIMUTH_ERR_093:0, DET_AZIMUTH_ERR_094:0, DET_AZIMUTH_ERR_095:0, DET_AZIMUTH_ERR_096:0, DET_BI_STATIC_FLAG_093:0, DET_BI_STATIC_FLAG_094:0, DET_BI_STATIC_FLAG_095:0, DET_BI_STATIC_FLAG_096:0, DET_CONFD_AZIMUTH_093:0, DET_CONFD_AZIMUTH_094:0, DET_CONFD_AZIMUTH_095:0, DET_CONFD_AZIMUTH_096:0, DET_CONFD_ELEVATION_093:0, DET_CONFD_ELEVATION_094:0, DET_CONFD_ELEVATION_095:0, DET_CONFD_ELEVATION_096:0, DET_ELEVATION_093:0, DET_ELEVATION_094:0, DET_ELEVATION_095:0, DET_ELEVATION_096:0, DET_ELEVATION_ERR_093:0, DET_ELEVATION_ERR_094:0, DET_ELEVATION_ERR_095:0, DET_ELEVATION_ERR_096:0, DET_EXISTENCE_PROB_093:0, DET_EXISTENCE_PROB_094:0, DET_EXISTENCE_PROB_095:0, DET_EXISTENCE_PROB_096:0, DET_HVC_FLAG_093:0, DET_HVC_FLAG_094:0, DET_HVC_FLAG_095:0, DET_HVC_FLAG_096:0, DET_MH_CRC16_093_096:0, DET_MH_CYCLE_COUNTER_093_096:0, DET_MH_SCAN_INDEX_4LSB_093_096:0, DET_OUTSIDE_SECTOR_093:0, DET_OUTSIDE_SECTOR_094:0, DET_OUTSIDE_SECTOR_095:0, DET_OUTSIDE_SECTOR_096:0, DET_POINT_TARGET_PROB_093:0, DET_POINT_TARGET_PROB_094:0, DET_POINT_TARGET_PROB_095:0, DET_POINT_TARGET_PROB_096:0, DET_RANGE_093:0, DET_RANGE_094:0, DET_RANGE_095:0, DET_RANGE_096:0, DET_RANGE_ERR_093:0, DET_RANGE_ERR_094:0, DET_RANGE_ERR_095:0, DET_RANGE_ERR_096:0, DET_RANGE_VELOCITY_093:16384, DET_RANGE_VELOCITY_094:16384, DET_RANGE_VELOCITY_095:16384, DET_RANGE_VELOCITY_096:16384, DET_RANGE_VELOCITY_ERR_093:0, DET_RANGE_VELOCITY_ERR_094:0, DET_RANGE_VELOCITY_ERR_095:0, DET_RANGE_VELOCITY_ERR_096:0, DET_RCS_093:128, DET_RCS_094:128, DET_RCS_095:128, DET_RCS_096:128, DET_SNR_093:0, DET_SNR_094:0, DET_SNR_095:0, DET_SNR_096:0, DET_SUPER_RES_TARGET_093:0, DET_SUPER_RES_TARGET_094:0, DET_SUPER_RES_TARGET_095:0, DET_SUPER_RES_TARGET_096:0, DET_VALID_FLAG_093:0, DET_VALID_FLAG_094:0, DET_VALID_FLAG_095:0, DET_VALID_FLAG_096:0]}, provided-interface=Pi_SG_Detections_093_096
      Pp_SG_Detections_097_100: nonqueued-sender-com-spec{data-element=Vdp_SG_Detections_097_100, init-value=fields=[DET_AZIMUTH_097:0, DET_AZIMUTH_098:0, DET_AZIMUTH_099:0, DET_AZIMUTH_100:0, DET_AZIMUTH_ERR_097:0, DET_AZIMUTH_ERR_098:0, DET_AZIMUTH_ERR_099:0, DET_AZIMUTH_ERR_100:0, DET_BI_STATIC_FLAG_097:0, DET_BI_STATIC_FLAG_098:0, DET_BI_STATIC_FLAG_099:0, DET_BI_STATIC_FLAG_100:0, DET_CONFD_AZIMUTH_097:0, DET_CONFD_AZIMUTH_098:0, DET_CONFD_AZIMUTH_099:0, DET_CONFD_AZIMUTH_100:0, DET_CONFD_ELEVATION_097:0, DET_CONFD_ELEVATION_098:0, DET_CONFD_ELEVATION_099:0, DET_CONFD_ELEVATION_100:0, DET_ELEVATION_097:0, DET_ELEVATION_098:0, DET_ELEVATION_099:0, DET_ELEVATION_100:0, DET_ELEVATION_ERR_097:0, DET_ELEVATION_ERR_098:0, DET_ELEVATION_ERR_099:0, DET_ELEVATION_ERR_100:0, DET_EXISTENCE_PROB_097:0, DET_EXISTENCE_PROB_098:0, DET_EXISTENCE_PROB_099:0, DET_EXISTENCE_PROB_100:0, DET_HVC_FLAG_097:0, DET_HVC_FLAG_098:0, DET_HVC_FLAG_099:0, DET_HVC_FLAG_100:0, DET_MH_CRC16_097_100:0, DET_MH_CYCLE_COUNTER_097_100:0, DET_MH_SCAN_INDEX_4LSB_097_100:0, DET_OUTSIDE_SECTOR_097:0, DET_OUTSIDE_SECTOR_098:0, DET_OUTSIDE_SECTOR_099:0, DET_OUTSIDE_SECTOR_100:0, DET_POINT_TARGET_PROB_097:0, DET_POINT_TARGET_PROB_098:0, DET_POINT_TARGET_PROB_099:0, DET_POINT_TARGET_PROB_100:0, DET_RANGE_097:0, DET_RANGE_098:0, DET_RANGE_099:0, DET_RANGE_100:0, DET_RANGE_ERR_097:0, DET_RANGE_ERR_098:0, DET_RANGE_ERR_099:0, DET_RANGE_ERR_100:0, DET_RANGE_VELOCITY_097:16384, DET_RANGE_VELOCITY_098:16384, DET_RANGE_VELOCITY_099:16384, DET_RANGE_VELOCITY_100:16384, DET_RANGE_VELOCITY_ERR_097:0, DET_RANGE_VELOCITY_ERR_098:0, DET_RANGE_VELOCITY_ERR_099:0, DET_RANGE_VELOCITY_ERR_100:0, DET_RCS_097:128, DET_RCS_098:128, DET_RCS_099:128, DET_RCS_100:128, DET_SNR_097:0, DET_SNR_098:0, DET_SNR_099:0, DET_SNR_100:0, DET_SUPER_RES_TARGET_097:0, DET_SUPER_RES_TARGET_098:0, DET_SUPER_RES_TARGET_099:0, DET_SUPER_RES_TARGET_100:0, DET_VALID_FLAG_097:0, DET_VALID_FLAG_098:0, DET_VALID_FLAG_099:0, DET_VALID_FLAG_100:0]}, provided-interface=Pi_SG_Detections_097_100
      Pp_SG_Detections_101_104: nonqueued-sender-com-spec{data-element=Vdp_SG_Detections_101_104, init-value=fields=[DET_AZIMUTH_101:0, DET_AZIMUTH_102:0, DET_AZIMUTH_103:0, DET_AZIMUTH_104:0, DET_AZIMUTH_ERR_101:0, DET_AZIMUTH_ERR_102:0, DET_AZIMUTH_ERR_103:0, DET_AZIMUTH_ERR_104:0, DET_BI_STATIC_FLAG_101:0, DET_BI_STATIC_FLAG_102:0, DET_BI_STATIC_FLAG_103:0, DET_BI_STATIC_FLAG_104:0, DET_CONFD_AZIMUTH_101:0, DET_CONFD_AZIMUTH_102:0, DET_CONFD_AZIMUTH_103:0, DET_CONFD_AZIMUTH_104:0, DET_CONFD_ELEVATION_101:0, DET_CONFD_ELEVATION_102:0, DET_CONFD_ELEVATION_103:0, DET_CONFD_ELEVATION_104:0, DET_ELEVATION_101:0, DET_ELEVATION_102:0, DET_ELEVATION_103:0, DET_ELEVATION_104:0, DET_ELEVATION_ERR_101:0, DET_ELEVATION_ERR_102:0, DET_ELEVATION_ERR_103:0, DET_ELEVATION_ERR_104:0, DET_EXISTENCE_PROB_101:0, DET_EXISTENCE_PROB_102:0, DET_EXISTENCE_PROB_103:0, DET_EXISTENCE_PROB_104:0, DET_HVC_FLAG_101:0, DET_HVC_FLAG_102:0, DET_HVC_FLAG_103:0, DET_HVC_FLAG_104:0, DET_MH_CRC16_101_104:0, DET_MH_CYCLE_COUNTER_101_104:0, DET_MH_SCAN_INDEX_4LSB_101_104:0, DET_OUTSIDE_SECTOR_101:0, DET_OUTSIDE_SECTOR_102:0, DET_OUTSIDE_SECTOR_103:0, DET_OUTSIDE_SECTOR_104:0, DET_POINT_TARGET_PROB_101:0, DET_POINT_TARGET_PROB_102:0, DET_POINT_TARGET_PROB_103:0, DET_POINT_TARGET_PROB_104:0, DET_RANGE_101:0, DET_RANGE_102:0, DET_RANGE_103:0, DET_RANGE_104:0, DET_RANGE_ERR_101:0, DET_RANGE_ERR_102:0, DET_RANGE_ERR_103:0, DET_RANGE_ERR_104:0, DET_RANGE_VELOCITY_101:16384, DET_RANGE_VELOCITY_102:16384, DET_RANGE_VELOCITY_103:16384, DET_RANGE_VELOCITY_104:16384, DET_RANGE_VELOCITY_ERR_101:0, DET_RANGE_VELOCITY_ERR_102:0, DET_RANGE_VELOCITY_ERR_103:0, DET_RANGE_VELOCITY_ERR_104:0, DET_RCS_101:128, DET_RCS_102:128, DET_RCS_103:128, DET_RCS_104:128, DET_SNR_101:0, DET_SNR_102:0, DET_SNR_103:0, DET_SNR_104:0, DET_SUPER_RES_TARGET_101:0, DET_SUPER_RES_TARGET_102:0, DET_SUPER_RES_TARGET_103:0, DET_SUPER_RES_TARGET_104:0, DET_VALID_FLAG_101:0, DET_VALID_FLAG_102:0, DET_VALID_FLAG_103:0, DET_VALID_FLAG_104:0]}, provided-interface=Pi_SG_Detections_101_104
      Pp_SG_Detections_105_108: nonqueued-sender-com-spec{data-element=Vdp_SG_Detections_105_108, init-value=fields=[DET_AZIMUTH_105:0, DET_AZIMUTH_106:0, DET_AZIMUTH_107:0, DET_AZIMUTH_108:0, DET_AZIMUTH_ERR_105:0, DET_AZIMUTH_ERR_106:0, DET_AZIMUTH_ERR_107:0, DET_AZIMUTH_ERR_108:0, DET_BI_STATIC_FLAG_105:0, DET_BI_STATIC_FLAG_106:0, DET_BI_STATIC_FLAG_107:0, DET_BI_STATIC_FLAG_108:0, DET_CONFD_AZIMUTH_105:0, DET_CONFD_AZIMUTH_106:0, DET_CONFD_AZIMUTH_107:0, DET_CONFD_AZIMUTH_108:0, DET_CONFD_ELEVATION_105:0, DET_CONFD_ELEVATION_106:0, DET_CONFD_ELEVATION_107:0, DET_CONFD_ELEVATION_108:0, DET_ELEVATION_105:0, DET_ELEVATION_106:0, DET_ELEVATION_107:0, DET_ELEVATION_108:0, DET_ELEVATION_ERR_105:0, DET_ELEVATION_ERR_106:0, DET_ELEVATION_ERR_107:0, DET_ELEVATION_ERR_108:0, DET_EXISTENCE_PROB_105:0, DET_EXISTENCE_PROB_106:0, DET_EXISTENCE_PROB_107:0, DET_EXISTENCE_PROB_108:0, DET_HVC_FLAG_105:0, DET_HVC_FLAG_106:0, DET_HVC_FLAG_107:0, DET_HVC_FLAG_108:0, DET_MH_CRC16_105_108:0, DET_MH_CYCLE_COUNTER_105_108:0, DET_MH_SCAN_INDEX_4LSB_105_108:0, DET_OUTSIDE_SECTOR_105:0, DET_OUTSIDE_SECTOR_106:0, DET_OUTSIDE_SECTOR_107:0, DET_OUTSIDE_SECTOR_108:0, DET_POINT_TARGET_PROB_105:0, DET_POINT_TARGET_PROB_106:0, DET_POINT_TARGET_PROB_107:0, DET_POINT_TARGET_PROB_108:0, DET_RANGE_105:0, DET_RANGE_106:0, DET_RANGE_107:0, DET_RANGE_108:0, DET_RANGE_ERR_105:0, DET_RANGE_ERR_106:0, DET_RANGE_ERR_107:0, DET_RANGE_ERR_108:0, DET_RANGE_VELOCITY_105:16384, DET_RANGE_VELOCITY_106:16384, DET_RANGE_VELOCITY_107:16384, DET_RANGE_VELOCITY_108:16384, DET_RANGE_VELOCITY_ERR_105:0, DET_RANGE_VELOCITY_ERR_106:0, DET_RANGE_VELOCITY_ERR_107:0, DET_RANGE_VELOCITY_ERR_108:0, DET_RCS_105:128, DET_RCS_106:128, DET_RCS_107:128, DET_RCS_108:128, DET_SNR_105:0, DET_SNR_106:0, DET_SNR_107:0, DET_SNR_108:0, DET_SUPER_RES_TARGET_105:0, DET_SUPER_RES_TARGET_106:0, DET_SUPER_RES_TARGET_107:0, DET_SUPER_RES_TARGET_108:0, DET_VALID_FLAG_105:0, DET_VALID_FLAG_106:0, DET_VALID_FLAG_107:0, DET_VALID_FLAG_108:0]}, provided-interface=Pi_SG_Detections_105_108
      Pp_SG_Detections_109_112: nonqueued-sender-com-spec{data-element=Vdp_SG_Detections_109_112, init-value=fields=[DET_AZIMUTH_109:0, DET_AZIMUTH_110:0, DET_AZIMUTH_111:0, DET_AZIMUTH_112:0, DET_AZIMUTH_ERR_109:0, DET_AZIMUTH_ERR_110:0, DET_AZIMUTH_ERR_111:0, DET_AZIMUTH_ERR_112:0, DET_BI_STATIC_FLAG_109:0, DET_BI_STATIC_FLAG_110:0, DET_BI_STATIC_FLAG_111:0, DET_BI_STATIC_FLAG_112:0, DET_CONFD_AZIMUTH_109:0, DET_CONFD_AZIMUTH_110:0, DET_CONFD_AZIMUTH_111:0, DET_CONFD_AZIMUTH_112:0, DET_CONFD_ELEVATION_109:0, DET_CONFD_ELEVATION_110:0, DET_CONFD_ELEVATION_111:0, DET_CONFD_ELEVATION_112:0, DET_ELEVATION_109:0, DET_ELEVATION_110:0, DET_ELEVATION_111:0, DET_ELEVATION_112:0, DET_ELEVATION_ERR_109:0, DET_ELEVATION_ERR_110:0, DET_ELEVATION_ERR_111:0, DET_ELEVATION_ERR_112:0, DET_EXISTENCE_PROB_109:0, DET_EXISTENCE_PROB_110:0, DET_EXISTENCE_PROB_111:0, DET_EXISTENCE_PROB_112:0, DET_HVC_FLAG_109:0, DET_HVC_FLAG_110:0, DET_HVC_FLAG_111:0, DET_HVC_FLAG_112:0, DET_MH_CRC16_109_112:0, DET_MH_CYCLE_COUNTER_109_112:0, DET_MH_SCAN_INDEX_4LSB_109_112:0, DET_OUTSIDE_SECTOR_109:0, DET_OUTSIDE_SECTOR_110:0, DET_OUTSIDE_SECTOR_111:0, DET_OUTSIDE_SECTOR_112:0, DET_POINT_TARGET_PROB_109:0, DET_POINT_TARGET_PROB_110:0, DET_POINT_TARGET_PROB_111:0, DET_POINT_TARGET_PROB_112:0, DET_RANGE_109:0, DET_RANGE_110:0, DET_RANGE_111:0, DET_RANGE_112:0, DET_RANGE_ERR_109:0, DET_RANGE_ERR_110:0, DET_RANGE_ERR_111:0, DET_RANGE_ERR_112:0, DET_RANGE_VELOCITY_109:16384, DET_RANGE_VELOCITY_110:16384, DET_RANGE_VELOCITY_111:16384, DET_RANGE_VELOCITY_112:16384, DET_RANGE_VELOCITY_ERR_109:0, DET_RANGE_VELOCITY_ERR_110:0, DET_RANGE_VELOCITY_ERR_111:0, DET_RANGE_VELOCITY_ERR_112:0, DET_RCS_109:128, DET_RCS_110:128, DET_RCS_111:128, DET_RCS_112:128, DET_SNR_109:0, DET_SNR_110:0, DET_SNR_111:0, DET_SNR_112:0, DET_SUPER_RES_TARGET_109:0, DET_SUPER_RES_TARGET_110:0, DET_SUPER_RES_TARGET_111:0, DET_SUPER_RES_TARGET_112:0, DET_VALID_FLAG_109:0, DET_VALID_FLAG_110:0, DET_VALID_FLAG_111:0, DET_VALID_FLAG_112:0]}, provided-interface=Pi_SG_Detections_109_112
      Pp_SG_Detections_113_116: nonqueued-sender-com-spec{data-element=Vdp_SG_Detections_113_116, init-value=fields=[DET_AZIMUTH_113:0, DET_AZIMUTH_114:0, DET_AZIMUTH_115:0, DET_AZIMUTH_116:0, DET_AZIMUTH_ERR_113:0, DET_AZIMUTH_ERR_114:0, DET_AZIMUTH_ERR_115:0, DET_AZIMUTH_ERR_116:0, DET_BI_STATIC_FLAG_113:0, DET_BI_STATIC_FLAG_114:0, DET_BI_STATIC_FLAG_115:0, DET_BI_STATIC_FLAG_116:0, DET_CONFD_AZIMUTH_113:0, DET_CONFD_AZIMUTH_114:0, DET_CONFD_AZIMUTH_115:0, DET_CONFD_AZIMUTH_116:0, DET_CONFD_ELEVATION_113:0, DET_CONFD_ELEVATION_114:0, DET_CONFD_ELEVATION_115:0, DET_CONFD_ELEVATION_116:0, DET_ELEVATION_113:0, DET_ELEVATION_114:0, DET_ELEVATION_115:0, DET_ELEVATION_116:0, DET_ELEVATION_ERR_113:0, DET_ELEVATION_ERR_114:0, DET_ELEVATION_ERR_115:0, DET_ELEVATION_ERR_116:0, DET_EXISTENCE_PROB_113:0, DET_EXISTENCE_PROB_114:0, DET_EXISTENCE_PROB_115:0, DET_EXISTENCE_PROB_116:0, DET_HVC_FLAG_113:0, DET_HVC_FLAG_114:0, DET_HVC_FLAG_115:0, DET_HVC_FLAG_116:0, DET_MH_CRC16_113_116:0, DET_MH_CYCLE_COUNTER_113_116:0, DET_MH_SCAN_INDEX_4LSB_113_116:0, DET_OUTSIDE_SECTOR_113:0, DET_OUTSIDE_SECTOR_114:0, DET_OUTSIDE_SECTOR_115:0, DET_OUTSIDE_SECTOR_116:0, DET_POINT_TARGET_PROB_113:0, DET_POINT_TARGET_PROB_114:0, DET_POINT_TARGET_PROB_115:0, DET_POINT_TARGET_PROB_116:0, DET_RANGE_113:0, DET_RANGE_114:0, DET_RANGE_115:0, DET_RANGE_116:0, DET_RANGE_ERR_113:0, DET_RANGE_ERR_114:0, DET_RANGE_ERR_115:0, DET_RANGE_ERR_116:0, DET_RANGE_VELOCITY_113:16384, DET_RANGE_VELOCITY_114:16384, DET_RANGE_VELOCITY_115:16384, DET_RANGE_VELOCITY_116:16384, DET_RANGE_VELOCITY_ERR_113:0, DET_RANGE_VELOCITY_ERR_114:0, DET_RANGE_VELOCITY_ERR_115:0, DET_RANGE_VELOCITY_ERR_116:0, DET_RCS_113:128, DET_RCS_114:128, DET_RCS_115:128, DET_RCS_116:128, DET_SNR_113:0, DET_SNR_114:0, DET_SNR_115:0, DET_SNR_116:0, DET_SUPER_RES_TARGET_113:0, DET_SUPER_RES_TARGET_114:0, DET_SUPER_RES_TARGET_115:0, DET_SUPER_RES_TARGET_116:0, DET_VALID_FLAG_113:0, DET_VALID_FLAG_114:0, DET_VALID_FLAG_115:0, DET_VALID_FLAG_116:0]}, provided-interface=Pi_SG_Detections_113_116
      Pp_SG_Detections_117_120: nonqueued-sender-com-spec{data-element=Vdp_SG_Detections_117_120, init-value=fields=[DET_AZIMUTH_117:0, DET_AZIMUTH_118:0, DET_AZIMUTH_119:0, DET_AZIMUTH_120:0, DET_AZIMUTH_ERR_117:0, DET_AZIMUTH_ERR_118:0, DET_AZIMUTH_ERR_119:0, DET_AZIMUTH_ERR_120:0, DET_BI_STATIC_FLAG_117:0, DET_BI_STATIC_FLAG_118:0, DET_BI_STATIC_FLAG_119:0, DET_BI_STATIC_FLAG_120:0, DET_CONFD_AZIMUTH_117:0, DET_CONFD_AZIMUTH_118:0, DET_CONFD_AZIMUTH_119:0, DET_CONFD_AZIMUTH_120:0, DET_CONFD_ELEVATION_117:0, DET_CONFD_ELEVATION_118:0, DET_CONFD_ELEVATION_119:0, DET_CONFD_ELEVATION_120:0, DET_ELEVATION_117:0, DET_ELEVATION_118:0, DET_ELEVATION_119:0, DET_ELEVATION_120:0, DET_ELEVATION_ERR_117:0, DET_ELEVATION_ERR_118:0, DET_ELEVATION_ERR_119:0, DET_ELEVATION_ERR_120:0, DET_EXISTENCE_PROB_117:0, DET_EXISTENCE_PROB_118:0, DET_EXISTENCE_PROB_119:0, DET_EXISTENCE_PROB_120:0, DET_HVC_FLAG_117:0, DET_HVC_FLAG_118:0, DET_HVC_FLAG_119:0, DET_HVC_FLAG_120:0, DET_MH_CRC16_117_120:0, DET_MH_CYCLE_COUNTER_117_120:0, DET_MH_SCAN_INDEX_4LSB_117_120:0, DET_OUTSIDE_SECTOR_117:0, DET_OUTSIDE_SECTOR_118:0, DET_OUTSIDE_SECTOR_119:0, DET_OUTSIDE_SECTOR_120:0, DET_POINT_TARGET_PROB_117:0, DET_POINT_TARGET_PROB_118:0, DET_POINT_TARGET_PROB_119:0, DET_POINT_TARGET_PROB_120:0, DET_RANGE_117:0, DET_RANGE_118:0, DET_RANGE_119:0, DET_RANGE_120:0, DET_RANGE_ERR_117:0, DET_RANGE_ERR_118:0, DET_RANGE_ERR_119:0, DET_RANGE_ERR_120:0, DET_RANGE_VELOCITY_117:16384, DET_RANGE_VELOCITY_118:16384, DET_RANGE_VELOCITY_119:16384, DET_RANGE_VELOCITY_120:16384, DET_RANGE_VELOCITY_ERR_117:0, DET_RANGE_VELOCITY_ERR_118:0, DET_RANGE_VELOCITY_ERR_119:0, DET_RANGE_VELOCITY_ERR_120:0, DET_RCS_117:128, DET_RCS_118:128, DET_RCS_119:128, DET_RCS_120:128, DET_SNR_117:0, DET_SNR_118:0, DET_SNR_119:0, DET_SNR_120:0, DET_SUPER_RES_TARGET_117:0, DET_SUPER_RES_TARGET_118:0, DET_SUPER_RES_TARGET_119:0, DET_SUPER_RES_TARGET_120:0, DET_VALID_FLAG_117:0, DET_VALID_FLAG_118:0, DET_VALID_FLAG_119:0, DET_VALID_FLAG_120:0]}, provided-interface=Pi_SG_Detections_117_120
      Pp_SG_Detections_121_124: nonqueued-sender-com-spec{data-element=Vdp_SG_Detections_121_124, init-value=fields=[DET_AZIMUTH_121:0, DET_AZIMUTH_122:0, DET_AZIMUTH_123:0, DET_AZIMUTH_124:0, DET_AZIMUTH_ERR_121:0, DET_AZIMUTH_ERR_122:0, DET_AZIMUTH_ERR_123:0, DET_AZIMUTH_ERR_124:0, DET_BI_STATIC_FLAG_121:0, DET_BI_STATIC_FLAG_122:0, DET_BI_STATIC_FLAG_123:0, DET_BI_STATIC_FLAG_124:0, DET_CONFD_AZIMUTH_121:0, DET_CONFD_AZIMUTH_122:0, DET_CONFD_AZIMUTH_123:0, DET_CONFD_AZIMUTH_124:0, DET_CONFD_ELEVATION_121:0, DET_CONFD_ELEVATION_122:0, DET_CONFD_ELEVATION_123:0, DET_CONFD_ELEVATION_124:0, DET_ELEVATION_121:0, DET_ELEVATION_122:0, DET_ELEVATION_123:0, DET_ELEVATION_124:0, DET_ELEVATION_ERR_121:0, DET_ELEVATION_ERR_122:0, DET_ELEVATION_ERR_123:0, DET_ELEVATION_ERR_124:0, DET_EXISTENCE_PROB_121:0, DET_EXISTENCE_PROB_122:0, DET_EXISTENCE_PROB_123:0, DET_EXISTENCE_PROB_124:0, DET_HVC_FLAG_121:0, DET_HVC_FLAG_122:0, DET_HVC_FLAG_123:0, DET_HVC_FLAG_124:0, DET_MH_CRC16_121_124:0, DET_MH_CYCLE_COUNTER_121_124:0, DET_MH_SCAN_INDEX_4LSB_121_124:0, DET_OUTSIDE_SECTOR_121:0, DET_OUTSIDE_SECTOR_122:0, DET_OUTSIDE_SECTOR_123:0, DET_OUTSIDE_SECTOR_124:0, DET_POINT_TARGET_PROB_121:0, DET_POINT_TARGET_PROB_122:0, DET_POINT_TARGET_PROB_123:0, DET_POINT_TARGET_PROB_124:0, DET_RANGE_121:0, DET_RANGE_122:0, DET_RANGE_123:0, DET_RANGE_124:0, DET_RANGE_ERR_121:0, DET_RANGE_ERR_122:0, DET_RANGE_ERR_123:0, DET_RANGE_ERR_124:0, DET_RANGE_VELOCITY_121:16384, DET_RANGE_VELOCITY_122:16384, DET_RANGE_VELOCITY_123:16384, DET_RANGE_VELOCITY_124:16384, DET_RANGE_VELOCITY_ERR_121:0, DET_RANGE_VELOCITY_ERR_122:0, DET_RANGE_VELOCITY_ERR_123:0, DET_RANGE_VELOCITY_ERR_124:0, DET_RCS_121:128, DET_RCS_122:128, DET_RCS_123:128, DET_RCS_124:128, DET_SNR_121:0, DET_SNR_122:0, DET_SNR_123:0, DET_SNR_124:0, DET_SUPER_RES_TARGET_121:0, DET_SUPER_RES_TARGET_122:0, DET_SUPER_RES_TARGET_123:0, DET_SUPER_RES_TARGET_124:0, DET_VALID_FLAG_121:0, DET_VALID_FLAG_122:0, DET_VALID_FLAG_123:0, DET_VALID_FLAG_124:0]}, provided-interface=Pi_SG_Detections_121_124
      Pp_SG_Detections_125_128: nonqueued-sender-com-spec{data-element=Vdp_SG_Detections_125_128, init-value=fields=[DET_AZIMUTH_125:0, DET_AZIMUTH_126:0, DET_AZIMUTH_127:0, DET_AZIMUTH_128:0, DET_AZIMUTH_ERR_125:0, DET_AZIMUTH_ERR_126:0, DET_AZIMUTH_ERR_127:0, DET_AZIMUTH_ERR_128:0, DET_BI_STATIC_FLAG_125:0, DET_BI_STATIC_FLAG_126:0, DET_BI_STATIC_FLAG_127:0, DET_BI_STATIC_FLAG_128:0, DET_CONFD_AZIMUTH_125:0, DET_CONFD_AZIMUTH_126:0, DET_CONFD_AZIMUTH_127:0, DET_CONFD_AZIMUTH_128:0, DET_CONFD_ELEVATION_125:0, DET_CONFD_ELEVATION_126:0, DET_CONFD_ELEVATION_127:0, DET_CONFD_ELEVATION_128:0, DET_ELEVATION_125:0, DET_ELEVATION_126:0, DET_ELEVATION_127:0, DET_ELEVATION_128:0, DET_ELEVATION_ERR_125:0, DET_ELEVATION_ERR_126:0, DET_ELEVATION_ERR_127:0, DET_ELEVATION_ERR_128:0, DET_EXISTENCE_PROB_125:0, DET_EXISTENCE_PROB_126:0, DET_EXISTENCE_PROB_127:0, DET_EXISTENCE_PROB_128:0, DET_HVC_FLAG_125:0, DET_HVC_FLAG_126:0, DET_HVC_FLAG_127:0, DET_HVC_FLAG_128:0, DET_MH_CRC16_125_128:0, DET_MH_CYCLE_COUNTER_125_128:0, DET_MH_SCAN_INDEX_4LSB_125_128:0, DET_OUTSIDE_SECTOR_125:0, DET_OUTSIDE_SECTOR_126:0, DET_OUTSIDE_SECTOR_127:0, DET_OUTSIDE_SECTOR_128:0, DET_POINT_TARGET_PROB_125:0, DET_POINT_TARGET_PROB_126:0, DET_POINT_TARGET_PROB_127:0, DET_POINT_TARGET_PROB_128:0, DET_RANGE_125:0, DET_RANGE_126:0, DET_RANGE_127:0, DET_RANGE_128:0, DET_RANGE_ERR_125:0, DET_RANGE_ERR_126:0, DET_RANGE_ERR_127:0, DET_RANGE_ERR_128:0, DET_RANGE_VELOCITY_125:16384, DET_RANGE_VELOCITY_126:16384, DET_RANGE_VELOCITY_127:16384, DET_RANGE_VELOCITY_128:16384, DET_RANGE_VELOCITY_ERR_125:0, DET_RANGE_VELOCITY_ERR_126:0, DET_RANGE_VELOCITY_ERR_127:0, DET_RANGE_VELOCITY_ERR_128:0, DET_RCS_125:128, DET_RCS_126:128, DET_RCS_127:128, DET_RCS_128:128, DET_SNR_125:0, DET_SNR_126:0, DET_SNR_127:0, DET_SNR_128:0, DET_SUPER_RES_TARGET_125:0, DET_SUPER_RES_TARGET_126:0, DET_SUPER_RES_TARGET_127:0, DET_SUPER_RES_TARGET_128:0, DET_VALID_FLAG_125:0, DET_VALID_FLAG_126:0, DET_VALID_FLAG_127:0, DET_VALID_FLAG_128:0]}, provided-interface=Pi_SG_Detections_125_128
      Pp_SG_Detections_129_132: nonqueued-sender-com-spec{data-element=Vdp_SG_Detections_129_132, init-value=fields=[DET_AZIMUTH_129:0, DET_AZIMUTH_130:0, DET_AZIMUTH_131:0, DET_AZIMUTH_132:0, DET_AZIMUTH_ERR_129:0, DET_AZIMUTH_ERR_130:0, DET_AZIMUTH_ERR_131:0, DET_AZIMUTH_ERR_132:0, DET_BI_STATIC_FLAG_129:0, DET_BI_STATIC_FLAG_130:0, DET_BI_STATIC_FLAG_131:0, DET_BI_STATIC_FLAG_132:0, DET_CONFD_AZIMUTH_129:0, DET_CONFD_AZIMUTH_130:0, DET_CONFD_AZIMUTH_131:0, DET_CONFD_AZIMUTH_132:0, DET_CONFD_ELEVATION_129:0, DET_CONFD_ELEVATION_130:0, DET_CONFD_ELEVATION_131:0, DET_CONFD_ELEVATION_132:0, DET_ELEVATION_129:0, DET_ELEVATION_130:0, DET_ELEVATION_131:0, DET_ELEVATION_132:0, DET_ELEVATION_ERR_129:0, DET_ELEVATION_ERR_130:0, DET_ELEVATION_ERR_131:0, DET_ELEVATION_ERR_132:0, DET_EXISTENCE_PROB_129:0, DET_EXISTENCE_PROB_130:0, DET_EXISTENCE_PROB_131:0, DET_EXISTENCE_PROB_132:0, DET_HVC_FLAG_129:0, DET_HVC_FLAG_130:0, DET_HVC_FLAG_131:0, DET_HVC_FLAG_132:0, DET_MH_CRC16_129_132:0, DET_MH_CYCLE_COUNTER_129_132:0, DET_MH_SCAN_INDEX_4LSB_129_132:0, DET_OUTSIDE_SECTOR_129:0, DET_OUTSIDE_SECTOR_130:0, DET_OUTSIDE_SECTOR_131:0, DET_OUTSIDE_SECTOR_132:0, DET_POINT_TARGET_PROB_129:0, DET_POINT_TARGET_PROB_130:0, DET_POINT_TARGET_PROB_131:0, DET_POINT_TARGET_PROB_132:0, DET_RANGE_129:0, DET_RANGE_130:0, DET_RANGE_131:0, DET_RANGE_132:0, DET_RANGE_ERR_129:0, DET_RANGE_ERR_130:0, DET_RANGE_ERR_131:0, DET_RANGE_ERR_132:0, DET_RANGE_VELOCITY_129:16384, DET_RANGE_VELOCITY_130:16384, DET_RANGE_VELOCITY_131:16384, DET_RANGE_VELOCITY_132:16384, DET_RANGE_VELOCITY_ERR_129:0, DET_RANGE_VELOCITY_ERR_130:0, DET_RANGE_VELOCITY_ERR_131:0, DET_RANGE_VELOCITY_ERR_132:0, DET_RCS_129:128, DET_RCS_130:128, DET_RCS_131:128, DET_RCS_132:128, DET_SNR_129:0, DET_SNR_130:0, DET_SNR_131:0, DET_SNR_132:0, DET_SUPER_RES_TARGET_129:0, DET_SUPER_RES_TARGET_130:0, DET_SUPER_RES_TARGET_131:0, DET_SUPER_RES_TARGET_132:0, DET_VALID_FLAG_129:0, DET_VALID_FLAG_130:0, DET_VALID_FLAG_131:0, DET_VALID_FLAG_132:0]}, provided-interface=Pi_SG_Detections_129_132
      Pp_SG_Detections_133_136: nonqueued-sender-com-spec{data-element=Vdp_SG_Detections_133_136, init-value=fields=[DET_AZIMUTH_133:0, DET_AZIMUTH_134:0, DET_AZIMUTH_135:0, DET_AZIMUTH_136:0, DET_AZIMUTH_ERR_133:0, DET_AZIMUTH_ERR_134:0, DET_AZIMUTH_ERR_135:0, DET_AZIMUTH_ERR_136:0, DET_BI_STATIC_FLAG_133:0, DET_BI_STATIC_FLAG_134:0, DET_BI_STATIC_FLAG_135:0, DET_BI_STATIC_FLAG_136:0, DET_CONFD_AZIMUTH_133:0, DET_CONFD_AZIMUTH_134:0, DET_CONFD_AZIMUTH_135:0, DET_CONFD_AZIMUTH_136:0, DET_CONFD_ELEVATION_133:0, DET_CONFD_ELEVATION_134:0, DET_CONFD_ELEVATION_135:0, DET_CONFD_ELEVATION_136:0, DET_ELEVATION_133:0, DET_ELEVATION_134:0, DET_ELEVATION_135:0, DET_ELEVATION_136:0, DET_ELEVATION_ERR_133:0, DET_ELEVATION_ERR_134:0, DET_ELEVATION_ERR_135:0, DET_ELEVATION_ERR_136:0, DET_EXISTENCE_PROB_133:0, DET_EXISTENCE_PROB_134:0, DET_EXISTENCE_PROB_135:0, DET_EXISTENCE_PROB_136:0, DET_HVC_FLAG_133:0, DET_HVC_FLAG_134:0, DET_HVC_FLAG_135:0, DET_HVC_FLAG_136:0, DET_MH_CRC16_133_136:0, DET_MH_CYCLE_COUNTER_133_136:0, DET_MH_SCAN_INDEX_4LSB_133_136:0, DET_OUTSIDE_SECTOR_133:0, DET_OUTSIDE_SECTOR_134:0, DET_OUTSIDE_SECTOR_135:0, DET_OUTSIDE_SECTOR_136:0, DET_POINT_TARGET_PROB_133:0, DET_POINT_TARGET_PROB_134:0, DET_POINT_TARGET_PROB_135:0, DET_POINT_TARGET_PROB_136:0, DET_RANGE_133:0, DET_RANGE_134:0, DET_RANGE_135:0, DET_RANGE_136:0, DET_RANGE_ERR_133:0, DET_RANGE_ERR_134:0, DET_RANGE_ERR_135:0, DET_RANGE_ERR_136:0, DET_RANGE_VELOCITY_133:16384, DET_RANGE_VELOCITY_134:16384, DET_RANGE_VELOCITY_135:16384, DET_RANGE_VELOCITY_136:16384, DET_RANGE_VELOCITY_ERR_133:0, DET_RANGE_VELOCITY_ERR_134:0, DET_RANGE_VELOCITY_ERR_135:0, DET_RANGE_VELOCITY_ERR_136:0, DET_RCS_133:128, DET_RCS_134:128, DET_RCS_135:128, DET_RCS_136:128, DET_SNR_133:0, DET_SNR_134:0, DET_SNR_135:0, DET_SNR_136:0, DET_SUPER_RES_TARGET_133:0, DET_SUPER_RES_TARGET_134:0, DET_SUPER_RES_TARGET_135:0, DET_SUPER_RES_TARGET_136:0, DET_VALID_FLAG_133:0, DET_VALID_FLAG_134:0, DET_VALID_FLAG_135:0, DET_VALID_FLAG_136:0]}, provided-interface=Pi_SG_Detections_133_136
      Pp_SG_Detections_137_140: nonqueued-sender-com-spec{data-element=Vdp_SG_Detections_137_140, init-value=fields=[DET_AZIMUTH_137:0, DET_AZIMUTH_138:0, DET_AZIMUTH_139:0, DET_AZIMUTH_140:0, DET_AZIMUTH_ERR_137:0, DET_AZIMUTH_ERR_138:0, DET_AZIMUTH_ERR_139:0, DET_AZIMUTH_ERR_140:0, DET_BI_STATIC_FLAG_137:0, DET_BI_STATIC_FLAG_138:0, DET_BI_STATIC_FLAG_139:0, DET_BI_STATIC_FLAG_140:0, DET_CONFD_AZIMUTH_137:0, DET_CONFD_AZIMUTH_138:0, DET_CONFD_AZIMUTH_139:0, DET_CONFD_AZIMUTH_140:0, DET_CONFD_ELEVATION_137:0, DET_CONFD_ELEVATION_138:0, DET_CONFD_ELEVATION_139:0, DET_CONFD_ELEVATION_140:0, DET_ELEVATION_137:0, DET_ELEVATION_138:0, DET_ELEVATION_139:0, DET_ELEVATION_140:0, DET_ELEVATION_ERR_137:0, DET_ELEVATION_ERR_138:0, DET_ELEVATION_ERR_139:0, DET_ELEVATION_ERR_140:0, DET_EXISTENCE_PROB_137:0, DET_EXISTENCE_PROB_138:0, DET_EXISTENCE_PROB_139:0, DET_EXISTENCE_PROB_140:0, DET_HVC_FLAG_137:0, DET_HVC_FLAG_138:0, DET_HVC_FLAG_139:0, DET_HVC_FLAG_140:0, DET_MH_CRC16_137_140:0, DET_MH_CYCLE_COUNTER_137_140:0, DET_MH_SCAN_INDEX_4LSB_137_140:0, DET_OUTSIDE_SECTOR_137:0, DET_OUTSIDE_SECTOR_138:0, DET_OUTSIDE_SECTOR_139:0, DET_OUTSIDE_SECTOR_140:0, DET_POINT_TARGET_PROB_137:0, DET_POINT_TARGET_PROB_138:0, DET_POINT_TARGET_PROB_139:0, DET_POINT_TARGET_PROB_140:0, DET_RANGE_137:0, DET_RANGE_138:0, DET_RANGE_139:0, DET_RANGE_140:0, DET_RANGE_ERR_137:0, DET_RANGE_ERR_138:0, DET_RANGE_ERR_139:0, DET_RANGE_ERR_140:0, DET_RANGE_VELOCITY_137:16384, DET_RANGE_VELOCITY_138:16384, DET_RANGE_VELOCITY_139:16384, DET_RANGE_VELOCITY_140:16384, DET_RANGE_VELOCITY_ERR_137:0, DET_RANGE_VELOCITY_ERR_138:0, DET_RANGE_VELOCITY_ERR_139:0, DET_RANGE_VELOCITY_ERR_140:0, DET_RCS_137:128, DET_RCS_138:128, DET_RCS_139:128, DET_RCS_140:128, DET_SNR_137:0, DET_SNR_138:0, DET_SNR_139:0, DET_SNR_140:0, DET_SUPER_RES_TARGET_137:0, DET_SUPER_RES_TARGET_138:0, DET_SUPER_RES_TARGET_139:0, DET_SUPER_RES_TARGET_140:0, DET_VALID_FLAG_137:0, DET_VALID_FLAG_138:0, DET_VALID_FLAG_139:0, DET_VALID_FLAG_140:0]}, provided-interface=Pi_SG_Detections_137_140
      Pp_SG_Detections_141_144: nonqueued-sender-com-spec{data-element=Vdp_SG_Detections_141_144, init-value=fields=[DET_AZIMUTH_141:0, DET_AZIMUTH_142:0, DET_AZIMUTH_143:0, DET_AZIMUTH_144:0, DET_AZIMUTH_ERR_141:0, DET_AZIMUTH_ERR_142:0, DET_AZIMUTH_ERR_143:0, DET_AZIMUTH_ERR_144:0, DET_BI_STATIC_FLAG_141:0, DET_BI_STATIC_FLAG_142:0, DET_BI_STATIC_FLAG_143:0, DET_BI_STATIC_FLAG_144:0, DET_CONFD_AZIMUTH_141:0, DET_CONFD_AZIMUTH_142:0, DET_CONFD_AZIMUTH_143:0, DET_CONFD_AZIMUTH_144:0, DET_CONFD_ELEVATION_141:0, DET_CONFD_ELEVATION_142:0, DET_CONFD_ELEVATION_143:0, DET_CONFD_ELEVATION_144:0, DET_ELEVATION_141:0, DET_ELEVATION_142:0, DET_ELEVATION_143:0, DET_ELEVATION_144:0, DET_ELEVATION_ERR_141:0, DET_ELEVATION_ERR_142:0, DET_ELEVATION_ERR_143:0, DET_ELEVATION_ERR_144:0, DET_EXISTENCE_PROB_141:0, DET_EXISTENCE_PROB_142:0, DET_EXISTENCE_PROB_143:0, DET_EXISTENCE_PROB_144:0, DET_HVC_FLAG_141:0, DET_HVC_FLAG_142:0, DET_HVC_FLAG_143:0, DET_HVC_FLAG_144:0, DET_MH_CRC16_141_144:0, DET_MH_CYCLE_COUNTER_141_144:0, DET_MH_SCAN_INDEX_4LSB_141_144:0, DET_OUTSIDE_SECTOR_141:0, DET_OUTSIDE_SECTOR_142:0, DET_OUTSIDE_SECTOR_143:0, DET_OUTSIDE_SECTOR_144:0, DET_POINT_TARGET_PROB_141:0, DET_POINT_TARGET_PROB_142:0, DET_POINT_TARGET_PROB_143:0, DET_POINT_TARGET_PROB_144:0, DET_RANGE_141:0, DET_RANGE_142:0, DET_RANGE_143:0, DET_RANGE_144:0, DET_RANGE_ERR_141:0, DET_RANGE_ERR_142:0, DET_RANGE_ERR_143:0, DET_RANGE_ERR_144:0, DET_RANGE_VELOCITY_141:16384, DET_RANGE_VELOCITY_142:16384, DET_RANGE_VELOCITY_143:16384, DET_RANGE_VELOCITY_144:16384, DET_RANGE_VELOCITY_ERR_141:0, DET_RANGE_VELOCITY_ERR_142:0, DET_RANGE_VELOCITY_ERR_143:0, DET_RANGE_VELOCITY_ERR_144:0, DET_RCS_141:128, DET_RCS_142:128, DET_RCS_143:128, DET_RCS_144:128, DET_SNR_141:0, DET_SNR_142:0, DET_SNR_143:0, DET_SNR_144:0, DET_SUPER_RES_TARGET_141:0, DET_SUPER_RES_TARGET_142:0, DET_SUPER_RES_TARGET_143:0, DET_SUPER_RES_TARGET_144:0, DET_VALID_FLAG_141:0, DET_VALID_FLAG_142:0, DET_VALID_FLAG_143:0, DET_VALID_FLAG_144:0]}, provided-interface=Pi_SG_Detections_141_144
      Pp_SG_Detections_145_148: nonqueued-sender-com-spec{data-element=Vdp_SG_Detections_145_148, init-value=fields=[DET_AZIMUTH_145:0, DET_AZIMUTH_146:0, DET_AZIMUTH_147:0, DET_AZIMUTH_148:0, DET_AZIMUTH_ERR_145:0, DET_AZIMUTH_ERR_146:0, DET_AZIMUTH_ERR_147:0, DET_AZIMUTH_ERR_148:0, DET_BI_STATIC_FLAG_145:0, DET_BI_STATIC_FLAG_146:0, DET_BI_STATIC_FLAG_147:0, DET_BI_STATIC_FLAG_148:0, DET_CONFD_AZIMUTH_145:0, DET_CONFD_AZIMUTH_146:0, DET_CONFD_AZIMUTH_147:0, DET_CONFD_AZIMUTH_148:0, DET_CONFD_ELEVATION_145:0, DET_CONFD_ELEVATION_146:0, DET_CONFD_ELEVATION_147:0, DET_CONFD_ELEVATION_148:0, DET_ELEVATION_145:0, DET_ELEVATION_146:0, DET_ELEVATION_147:0, DET_ELEVATION_148:0, DET_ELEVATION_ERR_145:0, DET_ELEVATION_ERR_146:0, DET_ELEVATION_ERR_147:0, DET_ELEVATION_ERR_148:0, DET_EXISTENCE_PROB_145:0, DET_EXISTENCE_PROB_146:0, DET_EXISTENCE_PROB_147:0, DET_EXISTENCE_PROB_148:0, DET_HVC_FLAG_145:0, DET_HVC_FLAG_146:0, DET_HVC_FLAG_147:0, DET_HVC_FLAG_148:0, DET_MH_CRC16_145_148:0, DET_MH_CYCLE_COUNTER_145_148:0, DET_MH_SCAN_INDEX_4LSB_145_148:0, DET_OUTSIDE_SECTOR_145:0, DET_OUTSIDE_SECTOR_146:0, DET_OUTSIDE_SECTOR_147:0, DET_OUTSIDE_SECTOR_148:0, DET_POINT_TARGET_PROB_145:0, DET_POINT_TARGET_PROB_146:0, DET_POINT_TARGET_PROB_147:0, DET_POINT_TARGET_PROB_148:0, DET_RANGE_145:0, DET_RANGE_146:0, DET_RANGE_147:0, DET_RANGE_148:0, DET_RANGE_ERR_145:0, DET_RANGE_ERR_146:0, DET_RANGE_ERR_147:0, DET_RANGE_ERR_148:0, DET_RANGE_VELOCITY_145:16384, DET_RANGE_VELOCITY_146:16384, DET_RANGE_VELOCITY_147:16384, DET_RANGE_VELOCITY_148:16384, DET_RANGE_VELOCITY_ERR_145:0, DET_RANGE_VELOCITY_ERR_146:0, DET_RANGE_VELOCITY_ERR_147:0, DET_RANGE_VELOCITY_ERR_148:0, DET_RCS_145:128, DET_RCS_146:128, DET_RCS_147:128, DET_RCS_148:128, DET_SNR_145:0, DET_SNR_146:0, DET_SNR_147:0, DET_SNR_148:0, DET_SUPER_RES_TARGET_145:0, DET_SUPER_RES_TARGET_146:0, DET_SUPER_RES_TARGET_147:0, DET_SUPER_RES_TARGET_148:0, DET_VALID_FLAG_145:0, DET_VALID_FLAG_146:0, DET_VALID_FLAG_147:0, DET_VALID_FLAG_148:0]}, provided-interface=Pi_SG_Detections_145_148
      Pp_SG_Detections_149_152: nonqueued-sender-com-spec{data-element=Vdp_SG_Detections_149_152, init-value=fields=[DET_AZIMUTH_149:0, DET_AZIMUTH_150:0, DET_AZIMUTH_151:0, DET_AZIMUTH_152:0, DET_AZIMUTH_ERR_149:0, DET_AZIMUTH_ERR_150:0, DET_AZIMUTH_ERR_151:0, DET_AZIMUTH_ERR_152:0, DET_BI_STATIC_FLAG_149:0, DET_BI_STATIC_FLAG_150:0, DET_BI_STATIC_FLAG_151:0, DET_BI_STATIC_FLAG_152:0, DET_CONFD_AZIMUTH_149:0, DET_CONFD_AZIMUTH_150:0, DET_CONFD_AZIMUTH_151:0, DET_CONFD_AZIMUTH_152:0, DET_CONFD_ELEVATION_149:0, DET_CONFD_ELEVATION_150:0, DET_CONFD_ELEVATION_151:0, DET_CONFD_ELEVATION_152:0, DET_ELEVATION_149:0, DET_ELEVATION_150:0, DET_ELEVATION_151:0, DET_ELEVATION_152:0, DET_ELEVATION_ERR_149:0, DET_ELEVATION_ERR_150:0, DET_ELEVATION_ERR_151:0, DET_ELEVATION_ERR_152:0, DET_EXISTENCE_PROB_149:0, DET_EXISTENCE_PROB_150:0, DET_EXISTENCE_PROB_151:0, DET_EXISTENCE_PROB_152:0, DET_HVC_FLAG_149:0, DET_HVC_FLAG_150:0, DET_HVC_FLAG_151:0, DET_HVC_FLAG_152:0, DET_MH_CRC16_149_152:0, DET_MH_CYCLE_COUNTER_149_152:0, DET_MH_SCAN_INDEX_4LSB_149_152:0, DET_OUTSIDE_SECTOR_149:0, DET_OUTSIDE_SECTOR_150:0, DET_OUTSIDE_SECTOR_151:0, DET_OUTSIDE_SECTOR_152:0, DET_POINT_TARGET_PROB_149:0, DET_POINT_TARGET_PROB_150:0, DET_POINT_TARGET_PROB_151:0, DET_POINT_TARGET_PROB_152:0, DET_RANGE_149:0, DET_RANGE_150:0, DET_RANGE_151:0, DET_RANGE_152:0, DET_RANGE_ERR_149:0, DET_RANGE_ERR_150:0, DET_RANGE_ERR_151:0, DET_RANGE_ERR_152:0, DET_RANGE_VELOCITY_149:16384, DET_RANGE_VELOCITY_150:16384, DET_RANGE_VELOCITY_151:16384, DET_RANGE_VELOCITY_152:16384, DET_RANGE_VELOCITY_ERR_149:0, DET_RANGE_VELOCITY_ERR_150:0, DET_RANGE_VELOCITY_ERR_151:0, DET_RANGE_VELOCITY_ERR_152:0, DET_RCS_149:128, DET_RCS_150:128, DET_RCS_151:128, DET_RCS_152:128, DET_SNR_149:0, DET_SNR_150:0, DET_SNR_151:0, DET_SNR_152:0, DET_SUPER_RES_TARGET_149:0, DET_SUPER_RES_TARGET_150:0, DET_SUPER_RES_TARGET_151:0, DET_SUPER_RES_TARGET_152:0, DET_VALID_FLAG_149:0, DET_VALID_FLAG_150:0, DET_VALID_FLAG_151:0, DET_VALID_FLAG_152:0]}, provided-interface=Pi_SG_Detections_149_152
      Pp_SG_Detections_153_156: nonqueued-sender-com-spec{data-element=Vdp_SG_Detections_153_156, init-value=fields=[DET_AZIMUTH_153:0, DET_AZIMUTH_154:0, DET_AZIMUTH_155:0, DET_AZIMUTH_156:0, DET_AZIMUTH_ERR_153:0, DET_AZIMUTH_ERR_154:0, DET_AZIMUTH_ERR_155:0, DET_AZIMUTH_ERR_156:0, DET_BI_STATIC_FLAG_153:0, DET_BI_STATIC_FLAG_154:0, DET_BI_STATIC_FLAG_155:0, DET_BI_STATIC_FLAG_156:0, DET_CONFD_AZIMUTH_153:0, DET_CONFD_AZIMUTH_154:0, DET_CONFD_AZIMUTH_155:0, DET_CONFD_AZIMUTH_156:0, DET_CONFD_ELEVATION_153:0, DET_CONFD_ELEVATION_154:0, DET_CONFD_ELEVATION_155:0, DET_CONFD_ELEVATION_156:0, DET_ELEVATION_153:0, DET_ELEVATION_154:0, DET_ELEVATION_155:0, DET_ELEVATION_156:0, DET_ELEVATION_ERR_153:0, DET_ELEVATION_ERR_154:0, DET_ELEVATION_ERR_155:0, DET_ELEVATION_ERR_156:0, DET_EXISTENCE_PROB_153:0, DET_EXISTENCE_PROB_154:0, DET_EXISTENCE_PROB_155:0, DET_EXISTENCE_PROB_156:0, DET_HVC_FLAG_153:0, DET_HVC_FLAG_154:0, DET_HVC_FLAG_155:0, DET_HVC_FLAG_156:0, DET_MH_CRC16_153_156:0, DET_MH_CYCLE_COUNTER_153_156:0, DET_MH_SCAN_INDEX_4LSB_153_156:0, DET_OUTSIDE_SECTOR_153:0, DET_OUTSIDE_SECTOR_154:0, DET_OUTSIDE_SECTOR_155:0, DET_OUTSIDE_SECTOR_156:0, DET_POINT_TARGET_PROB_153:0, DET_POINT_TARGET_PROB_154:0, DET_POINT_TARGET_PROB_155:0, DET_POINT_TARGET_PROB_156:0, DET_RANGE_153:0, DET_RANGE_154:0, DET_RANGE_155:0, DET_RANGE_156:0, DET_RANGE_ERR_153:0, DET_RANGE_ERR_154:0, DET_RANGE_ERR_155:0, DET_RANGE_ERR_156:0, DET_RANGE_VELOCITY_153:16384, DET_RANGE_VELOCITY_154:16384, DET_RANGE_VELOCITY_155:16384, DET_RANGE_VELOCITY_156:16384, DET_RANGE_VELOCITY_ERR_153:0, DET_RANGE_VELOCITY_ERR_154:0, DET_RANGE_VELOCITY_ERR_155:0, DET_RANGE_VELOCITY_ERR_156:0, DET_RCS_153:128, DET_RCS_154:128, DET_RCS_155:128, DET_RCS_156:128, DET_SNR_153:0, DET_SNR_154:0, DET_SNR_155:0, DET_SNR_156:0, DET_SUPER_RES_TARGET_153:0, DET_SUPER_RES_TARGET_154:0, DET_SUPER_RES_TARGET_155:0, DET_SUPER_RES_TARGET_156:0, DET_VALID_FLAG_153:0, DET_VALID_FLAG_154:0, DET_VALID_FLAG_155:0, DET_VALID_FLAG_156:0]}, provided-interface=Pi_SG_Detections_153_156
      Pp_SG_Detections_157_160: nonqueued-sender-com-spec{data-element=Vdp_SG_Detections_157_160, init-value=fields=[DET_AZIMUTH_157:0, DET_AZIMUTH_158:0, DET_AZIMUTH_159:0, DET_AZIMUTH_160:0, DET_AZIMUTH_ERR_157:0, DET_AZIMUTH_ERR_158:0, DET_AZIMUTH_ERR_159:0, DET_AZIMUTH_ERR_160:0, DET_BI_STATIC_FLAG_157:0, DET_BI_STATIC_FLAG_158:0, DET_BI_STATIC_FLAG_159:0, DET_BI_STATIC_FLAG_160:0, DET_CONFD_AZIMUTH_157:0, DET_CONFD_AZIMUTH_158:0, DET_CONFD_AZIMUTH_159:0, DET_CONFD_AZIMUTH_160:0, DET_CONFD_ELEVATION_157:0, DET_CONFD_ELEVATION_158:0, DET_CONFD_ELEVATION_159:0, DET_CONFD_ELEVATION_160:0, DET_ELEVATION_157:0, DET_ELEVATION_158:0, DET_ELEVATION_159:0, DET_ELEVATION_160:0, DET_ELEVATION_ERR_157:0, DET_ELEVATION_ERR_158:0, DET_ELEVATION_ERR_159:0, DET_ELEVATION_ERR_160:0, DET_EXISTENCE_PROB_157:0, DET_EXISTENCE_PROB_158:0, DET_EXISTENCE_PROB_159:0, DET_EXISTENCE_PROB_160:0, DET_HVC_FLAG_157:0, DET_HVC_FLAG_158:0, DET_HVC_FLAG_159:0, DET_HVC_FLAG_160:0, DET_MH_CRC16_157_160:0, DET_MH_CYCLE_COUNTER_157_160:0, DET_MH_SCAN_INDEX_4LSB_157_160:0, DET_OUTSIDE_SECTOR_157:0, DET_OUTSIDE_SECTOR_158:0, DET_OUTSIDE_SECTOR_159:0, DET_OUTSIDE_SECTOR_160:0, DET_POINT_TARGET_PROB_157:0, DET_POINT_TARGET_PROB_158:0, DET_POINT_TARGET_PROB_159:0, DET_POINT_TARGET_PROB_160:0, DET_RANGE_157:0, DET_RANGE_158:0, DET_RANGE_159:0, DET_RANGE_160:0, DET_RANGE_ERR_157:0, DET_RANGE_ERR_158:0, DET_RANGE_ERR_159:0, DET_RANGE_ERR_160:0, DET_RANGE_VELOCITY_157:16384, DET_RANGE_VELOCITY_158:16384, DET_RANGE_VELOCITY_159:16384, DET_RANGE_VELOCITY_160:16384, DET_RANGE_VELOCITY_ERR_157:0, DET_RANGE_VELOCITY_ERR_158:0, DET_RANGE_VELOCITY_ERR_159:0, DET_RANGE_VELOCITY_ERR_160:0, DET_RCS_157:128, DET_RCS_158:128, DET_RCS_159:128, DET_RCS_160:128, DET_SNR_157:0, DET_SNR_158:0, DET_SNR_159:0, DET_SNR_160:0, DET_SUPER_RES_TARGET_157:0, DET_SUPER_RES_TARGET_158:0, DET_SUPER_RES_TARGET_159:0, DET_SUPER_RES_TARGET_160:0, DET_VALID_FLAG_157:0, DET_VALID_FLAG_158:0, DET_VALID_FLAG_159:0, DET_VALID_FLAG_160:0]}, provided-interface=Pi_SG_Detections_157_160
      Pp_SG_Detections_161_164: nonqueued-sender-com-spec{data-element=Vdp_SG_Detections_161_164, init-value=fields=[DET_AZIMUTH_161:0, DET_AZIMUTH_162:0, DET_AZIMUTH_163:0, DET_AZIMUTH_164:0, DET_AZIMUTH_ERR_161:0, DET_AZIMUTH_ERR_162:0, DET_AZIMUTH_ERR_163:0, DET_AZIMUTH_ERR_164:0, DET_BI_STATIC_FLAG_161:0, DET_BI_STATIC_FLAG_162:0, DET_BI_STATIC_FLAG_163:0, DET_BI_STATIC_FLAG_164:0, DET_CONFD_AZIMUTH_161:0, DET_CONFD_AZIMUTH_162:0, DET_CONFD_AZIMUTH_163:0, DET_CONFD_AZIMUTH_164:0, DET_CONFD_ELEVATION_161:0, DET_CONFD_ELEVATION_162:0, DET_CONFD_ELEVATION_163:0, DET_CONFD_ELEVATION_164:0, DET_ELEVATION_161:0, DET_ELEVATION_162:0, DET_ELEVATION_163:0, DET_ELEVATION_164:0, DET_ELEVATION_ERR_161:0, DET_ELEVATION_ERR_162:0, DET_ELEVATION_ERR_163:0, DET_ELEVATION_ERR_164:0, DET_EXISTENCE_PROB_161:0, DET_EXISTENCE_PROB_162:0, DET_EXISTENCE_PROB_163:0, DET_EXISTENCE_PROB_164:0, DET_HVC_FLAG_161:0, DET_HVC_FLAG_162:0, DET_HVC_FLAG_163:0, DET_HVC_FLAG_164:0, DET_MH_CRC16_161_164:0, DET_MH_CYCLE_COUNTER_161_164:0, DET_MH_SCAN_INDEX_4LSB_161_164:0, DET_OUTSIDE_SECTOR_161:0, DET_OUTSIDE_SECTOR_162:0, DET_OUTSIDE_SECTOR_163:0, DET_OUTSIDE_SECTOR_164:0, DET_POINT_TARGET_PROB_161:0, DET_POINT_TARGET_PROB_162:0, DET_POINT_TARGET_PROB_163:0, DET_POINT_TARGET_PROB_164:0, DET_RANGE_161:0, DET_RANGE_162:0, DET_RANGE_163:0, DET_RANGE_164:0, DET_RANGE_ERR_161:0, DET_RANGE_ERR_162:0, DET_RANGE_ERR_163:0, DET_RANGE_ERR_164:0, DET_RANGE_VELOCITY_161:16384, DET_RANGE_VELOCITY_162:16384, DET_RANGE_VELOCITY_163:16384, DET_RANGE_VELOCITY_164:16384, DET_RANGE_VELOCITY_ERR_161:0, DET_RANGE_VELOCITY_ERR_162:0, DET_RANGE_VELOCITY_ERR_163:0, DET_RANGE_VELOCITY_ERR_164:0, DET_RCS_161:128, DET_RCS_162:128, DET_RCS_163:128, DET_RCS_164:128, DET_SNR_161:0, DET_SNR_162:0, DET_SNR_163:0, DET_SNR_164:0, DET_SUPER_RES_TARGET_161:0, DET_SUPER_RES_TARGET_162:0, DET_SUPER_RES_TARGET_163:0, DET_SUPER_RES_TARGET_164:0, DET_VALID_FLAG_161:0, DET_VALID_FLAG_162:0, DET_VALID_FLAG_163:0, DET_VALID_FLAG_164:0]}, provided-interface=Pi_SG_Detections_161_164
      Pp_SG_Detections_165_168: nonqueued-sender-com-spec{data-element=Vdp_SG_Detections_165_168, init-value=fields=[DET_AZIMUTH_165:0, DET_AZIMUTH_166:0, DET_AZIMUTH_167:0, DET_AZIMUTH_168:0, DET_AZIMUTH_ERR_165:0, DET_AZIMUTH_ERR_166:0, DET_AZIMUTH_ERR_167:0, DET_AZIMUTH_ERR_168:0, DET_BI_STATIC_FLAG_165:0, DET_BI_STATIC_FLAG_166:0, DET_BI_STATIC_FLAG_167:0, DET_BI_STATIC_FLAG_168:0, DET_CONFD_AZIMUTH_165:0, DET_CONFD_AZIMUTH_166:0, DET_CONFD_AZIMUTH_167:0, DET_CONFD_AZIMUTH_168:0, DET_CONFD_ELEVATION_165:0, DET_CONFD_ELEVATION_166:0, DET_CONFD_ELEVATION_167:0, DET_CONFD_ELEVATION_168:0, DET_ELEVATION_165:0, DET_ELEVATION_166:0, DET_ELEVATION_167:0, DET_ELEVATION_168:0, DET_ELEVATION_ERR_165:0, DET_ELEVATION_ERR_166:0, DET_ELEVATION_ERR_167:0, DET_ELEVATION_ERR_168:0, DET_EXISTENCE_PROB_165:0, DET_EXISTENCE_PROB_166:0, DET_EXISTENCE_PROB_167:0, DET_EXISTENCE_PROB_168:0, DET_HVC_FLAG_165:0, DET_HVC_FLAG_166:0, DET_HVC_FLAG_167:0, DET_HVC_FLAG_168:0, DET_MH_CRC16_165_168:0, DET_MH_CYCLE_COUNTER_165_168:0, DET_MH_SCAN_INDEX_4LSB_165_168:0, DET_OUTSIDE_SECTOR_165:0, DET_OUTSIDE_SECTOR_166:0, DET_OUTSIDE_SECTOR_167:0, DET_OUTSIDE_SECTOR_168:0, DET_POINT_TARGET_PROB_165:0, DET_POINT_TARGET_PROB_166:0, DET_POINT_TARGET_PROB_167:0, DET_POINT_TARGET_PROB_168:0, DET_RANGE_165:0, DET_RANGE_166:0, DET_RANGE_167:0, DET_RANGE_168:0, DET_RANGE_ERR_165:0, DET_RANGE_ERR_166:0, DET_RANGE_ERR_167:0, DET_RANGE_ERR_168:0, DET_RANGE_VELOCITY_165:16384, DET_RANGE_VELOCITY_166:16384, DET_RANGE_VELOCITY_167:16384, DET_RANGE_VELOCITY_168:16384, DET_RANGE_VELOCITY_ERR_165:0, DET_RANGE_VELOCITY_ERR_166:0, DET_RANGE_VELOCITY_ERR_167:0, DET_RANGE_VELOCITY_ERR_168:0, DET_RCS_165:128, DET_RCS_166:128, DET_RCS_167:128, DET_RCS_168:128, DET_SNR_165:0, DET_SNR_166:0, DET_SNR_167:0, DET_SNR_168:0, DET_SUPER_RES_TARGET_165:0, DET_SUPER_RES_TARGET_166:0, DET_SUPER_RES_TARGET_167:0, DET_SUPER_RES_TARGET_168:0, DET_VALID_FLAG_165:0, DET_VALID_FLAG_166:0, DET_VALID_FLAG_167:0, DET_VALID_FLAG_168:0]}, provided-interface=Pi_SG_Detections_165_168
      Pp_SG_Detections_169_172: nonqueued-sender-com-spec{data-element=Vdp_SG_Detections_169_172, init-value=fields=[DET_AZIMUTH_169:0, DET_AZIMUTH_170:0, DET_AZIMUTH_171:0, DET_AZIMUTH_172:0, DET_AZIMUTH_ERR_169:0, DET_AZIMUTH_ERR_170:0, DET_AZIMUTH_ERR_171:0, DET_AZIMUTH_ERR_172:0, DET_BI_STATIC_FLAG_169:0, DET_BI_STATIC_FLAG_170:0, DET_BI_STATIC_FLAG_171:0, DET_BI_STATIC_FLAG_172:0, DET_CONFD_AZIMUTH_169:0, DET_CONFD_AZIMUTH_170:0, DET_CONFD_AZIMUTH_171:0, DET_CONFD_AZIMUTH_172:0, DET_CONFD_ELEVATION_169:0, DET_CONFD_ELEVATION_170:0, DET_CONFD_ELEVATION_171:0, DET_CONFD_ELEVATION_172:0, DET_ELEVATION_169:0, DET_ELEVATION_170:0, DET_ELEVATION_171:0, DET_ELEVATION_172:0, DET_ELEVATION_ERR_169:0, DET_ELEVATION_ERR_170:0, DET_ELEVATION_ERR_171:0, DET_ELEVATION_ERR_172:0, DET_EXISTENCE_PROB_169:0, DET_EXISTENCE_PROB_170:0, DET_EXISTENCE_PROB_171:0, DET_EXISTENCE_PROB_172:0, DET_HVC_FLAG_169:0, DET_HVC_FLAG_170:0, DET_HVC_FLAG_171:0, DET_HVC_FLAG_172:0, DET_MH_CRC16_169_172:0, DET_MH_CYCLE_COUNTER_169_172:0, DET_MH_SCAN_INDEX_4LSB_169_172:0, DET_OUTSIDE_SECTOR_169:0, DET_OUTSIDE_SECTOR_170:0, DET_OUTSIDE_SECTOR_171:0, DET_OUTSIDE_SECTOR_172:0, DET_POINT_TARGET_PROB_169:0, DET_POINT_TARGET_PROB_170:0, DET_POINT_TARGET_PROB_171:0, DET_POINT_TARGET_PROB_172:0, DET_RANGE_169:0, DET_RANGE_170:0, DET_RANGE_171:0, DET_RANGE_172:0, DET_RANGE_ERR_169:0, DET_RANGE_ERR_170:0, DET_RANGE_ERR_171:0, DET_RANGE_ERR_172:0, DET_RANGE_VELOCITY_169:16384, DET_RANGE_VELOCITY_170:16384, DET_RANGE_VELOCITY_171:16384, DET_RANGE_VELOCITY_172:16384, DET_RANGE_VELOCITY_ERR_169:0, DET_RANGE_VELOCITY_ERR_170:0, DET_RANGE_VELOCITY_ERR_171:0, DET_RANGE_VELOCITY_ERR_172:0, DET_RCS_169:128, DET_RCS_170:128, DET_RCS_171:128, DET_RCS_172:128, DET_SNR_169:0, DET_SNR_170:0, DET_SNR_171:0, DET_SNR_172:0, DET_SUPER_RES_TARGET_169:0, DET_SUPER_RES_TARGET_170:0, DET_SUPER_RES_TARGET_171:0, DET_SUPER_RES_TARGET_172:0, DET_VALID_FLAG_169:0, DET_VALID_FLAG_170:0, DET_VALID_FLAG_171:0, DET_VALID_FLAG_172:0]}, provided-interface=Pi_SG_Detections_169_172
      Pp_SG_Detections_173_176: nonqueued-sender-com-spec{data-element=Vdp_SG_Detections_173_176, init-value=fields=[DET_AZIMUTH_173:0, DET_AZIMUTH_174:0, DET_AZIMUTH_175:0, DET_AZIMUTH_176:0, DET_AZIMUTH_ERR_173:0, DET_AZIMUTH_ERR_174:0, DET_AZIMUTH_ERR_175:0, DET_AZIMUTH_ERR_176:0, DET_BI_STATIC_FLAG_173:0, DET_BI_STATIC_FLAG_174:0, DET_BI_STATIC_FLAG_175:0, DET_BI_STATIC_FLAG_176:0, DET_CONFD_AZIMUTH_173:0, DET_CONFD_AZIMUTH_174:0, DET_CONFD_AZIMUTH_175:0, DET_CONFD_AZIMUTH_176:0, DET_CONFD_ELEVATION_173:0, DET_CONFD_ELEVATION_174:0, DET_CONFD_ELEVATION_175:0, DET_CONFD_ELEVATION_176:0, DET_ELEVATION_173:0, DET_ELEVATION_174:0, DET_ELEVATION_175:0, DET_ELEVATION_176:0, DET_ELEVATION_ERR_173:0, DET_ELEVATION_ERR_174:0, DET_ELEVATION_ERR_175:0, DET_ELEVATION_ERR_176:0, DET_EXISTENCE_PROB_173:0, DET_EXISTENCE_PROB_174:0, DET_EXISTENCE_PROB_175:0, DET_EXISTENCE_PROB_176:0, DET_HVC_FLAG_173:0, DET_HVC_FLAG_174:0, DET_HVC_FLAG_175:0, DET_HVC_FLAG_176:0, DET_MH_CRC16_173_176:0, DET_MH_CYCLE_COUNTER_173_176:0, DET_MH_SCAN_INDEX_4LSB_173_176:0, DET_OUTSIDE_SECTOR_173:0, DET_OUTSIDE_SECTOR_174:0, DET_OUTSIDE_SECTOR_175:0, DET_OUTSIDE_SECTOR_176:0, DET_POINT_TARGET_PROB_173:0, DET_POINT_TARGET_PROB_174:0, DET_POINT_TARGET_PROB_175:0, DET_POINT_TARGET_PROB_176:0, DET_RANGE_173:0, DET_RANGE_174:0, DET_RANGE_175:0, DET_RANGE_176:0, DET_RANGE_ERR_173:0, DET_RANGE_ERR_174:0, DET_RANGE_ERR_175:0, DET_RANGE_ERR_176:0, DET_RANGE_VELOCITY_173:16384, DET_RANGE_VELOCITY_174:16384, DET_RANGE_VELOCITY_175:16384, DET_RANGE_VELOCITY_176:16384, DET_RANGE_VELOCITY_ERR_173:0, DET_RANGE_VELOCITY_ERR_174:0, DET_RANGE_VELOCITY_ERR_175:0, DET_RANGE_VELOCITY_ERR_176:0, DET_RCS_173:128, DET_RCS_174:128, DET_RCS_175:128, DET_RCS_176:128, DET_SNR_173:0, DET_SNR_174:0, DET_SNR_175:0, DET_SNR_176:0, DET_SUPER_RES_TARGET_173:0, DET_SUPER_RES_TARGET_174:0, DET_SUPER_RES_TARGET_175:0, DET_SUPER_RES_TARGET_176:0, DET_VALID_FLAG_173:0, DET_VALID_FLAG_174:0, DET_VALID_FLAG_175:0, DET_VALID_FLAG_176:0]}, provided-interface=Pi_SG_Detections_173_176
      Pp_SG_Detections_177_180: nonqueued-sender-com-spec{data-element=Vdp_SG_Detections_177_180, init-value=fields=[DET_AZIMUTH_177:0, DET_AZIMUTH_178:0, DET_AZIMUTH_179:0, DET_AZIMUTH_180:0, DET_AZIMUTH_ERR_177:0, DET_AZIMUTH_ERR_178:0, DET_AZIMUTH_ERR_179:0, DET_AZIMUTH_ERR_180:0, DET_BI_STATIC_FLAG_177:0, DET_BI_STATIC_FLAG_178:0, DET_BI_STATIC_FLAG_179:0, DET_BI_STATIC_FLAG_180:0, DET_CONFD_AZIMUTH_177:0, DET_CONFD_AZIMUTH_178:0, DET_CONFD_AZIMUTH_179:0, DET_CONFD_AZIMUTH_180:0, DET_CONFD_ELEVATION_177:0, DET_CONFD_ELEVATION_178:0, DET_CONFD_ELEVATION_179:0, DET_CONFD_ELEVATION_180:0, DET_ELEVATION_177:0, DET_ELEVATION_178:0, DET_ELEVATION_179:0, DET_ELEVATION_180:0, DET_ELEVATION_ERR_177:0, DET_ELEVATION_ERR_178:0, DET_ELEVATION_ERR_179:0, DET_ELEVATION_ERR_180:0, DET_EXISTENCE_PROB_177:0, DET_EXISTENCE_PROB_178:0, DET_EXISTENCE_PROB_179:0, DET_EXISTENCE_PROB_180:0, DET_HVC_FLAG_177:0, DET_HVC_FLAG_178:0, DET_HVC_FLAG_179:0, DET_HVC_FLAG_180:0, DET_MH_CRC16_177_180:0, DET_MH_CYCLE_COUNTER_177_180:0, DET_MH_SCAN_INDEX_4LSB_177_180:0, DET_OUTSIDE_SECTOR_177:0, DET_OUTSIDE_SECTOR_178:0, DET_OUTSIDE_SECTOR_179:0, DET_OUTSIDE_SECTOR_180:0, DET_POINT_TARGET_PROB_177:0, DET_POINT_TARGET_PROB_178:0, DET_POINT_TARGET_PROB_179:0, DET_POINT_TARGET_PROB_180:0, DET_RANGE_177:0, DET_RANGE_178:0, DET_RANGE_179:0, DET_RANGE_180:0, DET_RANGE_ERR_177:0, DET_RANGE_ERR_178:0, DET_RANGE_ERR_179:0, DET_RANGE_ERR_180:0, DET_RANGE_VELOCITY_177:16384, DET_RANGE_VELOCITY_178:16384, DET_RANGE_VELOCITY_179:16384, DET_RANGE_VELOCITY_180:16384, DET_RANGE_VELOCITY_ERR_177:0, DET_RANGE_VELOCITY_ERR_178:0, DET_RANGE_VELOCITY_ERR_179:0, DET_RANGE_VELOCITY_ERR_180:0, DET_RCS_177:128, DET_RCS_178:128, DET_RCS_179:128, DET_RCS_180:128, DET_SNR_177:0, DET_SNR_178:0, DET_SNR_179:0, DET_SNR_180:0, DET_SUPER_RES_TARGET_177:0, DET_SUPER_RES_TARGET_178:0, DET_SUPER_RES_TARGET_179:0, DET_SUPER_RES_TARGET_180:0, DET_VALID_FLAG_177:0, DET_VALID_FLAG_178:0, DET_VALID_FLAG_179:0, DET_VALID_FLAG_180:0]}, provided-interface=Pi_SG_Detections_177_180
      Pp_SG_Detections_181_184: nonqueued-sender-com-spec{data-element=Vdp_SG_Detections_181_184, init-value=fields=[DET_AZIMUTH_181:0, DET_AZIMUTH_182:0, DET_AZIMUTH_183:0, DET_AZIMUTH_184:0, DET_AZIMUTH_ERR_181:0, DET_AZIMUTH_ERR_182:0, DET_AZIMUTH_ERR_183:0, DET_AZIMUTH_ERR_184:0, DET_BI_STATIC_FLAG_181:0, DET_BI_STATIC_FLAG_182:0, DET_BI_STATIC_FLAG_183:0, DET_BI_STATIC_FLAG_184:0, DET_CONFD_AZIMUTH_181:0, DET_CONFD_AZIMUTH_182:0, DET_CONFD_AZIMUTH_183:0, DET_CONFD_AZIMUTH_184:0, DET_CONFD_ELEVATION_181:0, DET_CONFD_ELEVATION_182:0, DET_CONFD_ELEVATION_183:0, DET_CONFD_ELEVATION_184:0, DET_ELEVATION_181:0, DET_ELEVATION_182:0, DET_ELEVATION_183:0, DET_ELEVATION_184:0, DET_ELEVATION_ERR_181:0, DET_ELEVATION_ERR_182:0, DET_ELEVATION_ERR_183:0, DET_ELEVATION_ERR_184:0, DET_EXISTENCE_PROB_181:0, DET_EXISTENCE_PROB_182:0, DET_EXISTENCE_PROB_183:0, DET_EXISTENCE_PROB_184:0, DET_HVC_FLAG_181:0, DET_HVC_FLAG_182:0, DET_HVC_FLAG_183:0, DET_HVC_FLAG_184:0, DET_MH_CRC16_181_184:0, DET_MH_CYCLE_COUNTER_181_184:0, DET_MH_SCAN_INDEX_4LSB_181_184:0, DET_OUTSIDE_SECTOR_181:0, DET_OUTSIDE_SECTOR_182:0, DET_OUTSIDE_SECTOR_183:0, DET_OUTSIDE_SECTOR_184:0, DET_POINT_TARGET_PROB_181:0, DET_POINT_TARGET_PROB_182:0, DET_POINT_TARGET_PROB_183:0, DET_POINT_TARGET_PROB_184:0, DET_RANGE_181:0, DET_RANGE_182:0, DET_RANGE_183:0, DET_RANGE_184:0, DET_RANGE_ERR_181:0, DET_RANGE_ERR_182:0, DET_RANGE_ERR_183:0, DET_RANGE_ERR_184:0, DET_RANGE_VELOCITY_181:16384, DET_RANGE_VELOCITY_182:16384, DET_RANGE_VELOCITY_183:16384, DET_RANGE_VELOCITY_184:16384, DET_RANGE_VELOCITY_ERR_181:0, DET_RANGE_VELOCITY_ERR_182:0, DET_RANGE_VELOCITY_ERR_183:0, DET_RANGE_VELOCITY_ERR_184:0, DET_RCS_181:128, DET_RCS_182:128, DET_RCS_183:128, DET_RCS_184:128, DET_SNR_181:0, DET_SNR_182:0, DET_SNR_183:0, DET_SNR_184:0, DET_SUPER_RES_TARGET_181:0, DET_SUPER_RES_TARGET_182:0, DET_SUPER_RES_TARGET_183:0, DET_SUPER_RES_TARGET_184:0, DET_VALID_FLAG_181:0, DET_VALID_FLAG_182:0, DET_VALID_FLAG_183:0, DET_VALID_FLAG_184:0]}, provided-interface=Pi_SG_Detections_181_184
      Pp_SG_Detections_185_188: nonqueued-sender-com-spec{data-element=Vdp_SG_Detections_185_188, init-value=fields=[DET_AZIMUTH_185:0, DET_AZIMUTH_186:0, DET_AZIMUTH_187:0, DET_AZIMUTH_188:0, DET_AZIMUTH_ERR_185:0, DET_AZIMUTH_ERR_186:0, DET_AZIMUTH_ERR_187:0, DET_AZIMUTH_ERR_188:0, DET_BI_STATIC_FLAG_185:0, DET_BI_STATIC_FLAG_186:0, DET_BI_STATIC_FLAG_187:0, DET_BI_STATIC_FLAG_188:0, DET_CONFD_AZIMUTH_185:0, DET_CONFD_AZIMUTH_186:0, DET_CONFD_AZIMUTH_187:0, DET_CONFD_AZIMUTH_188:0, DET_CONFD_ELEVATION_185:0, DET_CONFD_ELEVATION_186:0, DET_CONFD_ELEVATION_187:0, DET_CONFD_ELEVATION_188:0, DET_ELEVATION_185:0, DET_ELEVATION_186:0, DET_ELEVATION_187:0, DET_ELEVATION_188:0, DET_ELEVATION_ERR_185:0, DET_ELEVATION_ERR_186:0, DET_ELEVATION_ERR_187:0, DET_ELEVATION_ERR_188:0, DET_EXISTENCE_PROB_185:0, DET_EXISTENCE_PROB_186:0, DET_EXISTENCE_PROB_187:0, DET_EXISTENCE_PROB_188:0, DET_HVC_FLAG_185:0, DET_HVC_FLAG_186:0, DET_HVC_FLAG_187:0, DET_HVC_FLAG_188:0, DET_MH_CRC16_185_188:0, DET_MH_CYCLE_COUNTER_185_188:0, DET_MH_SCAN_INDEX_4LSB_185_188:0, DET_OUTSIDE_SECTOR_185:0, DET_OUTSIDE_SECTOR_186:0, DET_OUTSIDE_SECTOR_187:0, DET_OUTSIDE_SECTOR_188:0, DET_POINT_TARGET_PROB_185:0, DET_POINT_TARGET_PROB_186:0, DET_POINT_TARGET_PROB_187:0, DET_POINT_TARGET_PROB_188:0, DET_RANGE_185:0, DET_RANGE_186:0, DET_RANGE_187:0, DET_RANGE_188:0, DET_RANGE_ERR_185:0, DET_RANGE_ERR_186:0, DET_RANGE_ERR_187:0, DET_RANGE_ERR_188:0, DET_RANGE_VELOCITY_185:16384, DET_RANGE_VELOCITY_186:16384, DET_RANGE_VELOCITY_187:16384, DET_RANGE_VELOCITY_188:16384, DET_RANGE_VELOCITY_ERR_185:0, DET_RANGE_VELOCITY_ERR_186:0, DET_RANGE_VELOCITY_ERR_187:0, DET_RANGE_VELOCITY_ERR_188:0, DET_RCS_185:128, DET_RCS_186:128, DET_RCS_187:128, DET_RCS_188:128, DET_SNR_185:0, DET_SNR_186:0, DET_SNR_187:0, DET_SNR_188:0, DET_SUPER_RES_TARGET_185:0, DET_SUPER_RES_TARGET_186:0, DET_SUPER_RES_TARGET_187:0, DET_SUPER_RES_TARGET_188:0, DET_VALID_FLAG_185:0, DET_VALID_FLAG_186:0, DET_VALID_FLAG_187:0, DET_VALID_FLAG_188:0]}, provided-interface=Pi_SG_Detections_185_188
      Pp_SG_Detections_189_192: nonqueued-sender-com-spec{data-element=Vdp_SG_Detections_189_192, init-value=fields=[DET_AZIMUTH_189:0, DET_AZIMUTH_190:0, DET_AZIMUTH_191:0, DET_AZIMUTH_192:0, DET_AZIMUTH_ERR_189:0, DET_AZIMUTH_ERR_190:0, DET_AZIMUTH_ERR_191:0, DET_AZIMUTH_ERR_192:0, DET_BI_STATIC_FLAG_189:0, DET_BI_STATIC_FLAG_190:0, DET_BI_STATIC_FLAG_191:0, DET_BI_STATIC_FLAG_192:0, DET_CONFD_AZIMUTH_189:0, DET_CONFD_AZIMUTH_190:0, DET_CONFD_AZIMUTH_191:0, DET_CONFD_AZIMUTH_192:0, DET_CONFD_ELEVATION_189:0, DET_CONFD_ELEVATION_190:0, DET_CONFD_ELEVATION_191:0, DET_CONFD_ELEVATION_192:0, DET_ELEVATION_189:0, DET_ELEVATION_190:0, DET_ELEVATION_191:0, DET_ELEVATION_192:0, DET_ELEVATION_ERR_189:0, DET_ELEVATION_ERR_190:0, DET_ELEVATION_ERR_191:0, DET_ELEVATION_ERR_192:0, DET_EXISTENCE_PROB_189:0, DET_EXISTENCE_PROB_190:0, DET_EXISTENCE_PROB_191:0, DET_EXISTENCE_PROB_192:0, DET_HVC_FLAG_189:0, DET_HVC_FLAG_190:0, DET_HVC_FLAG_191:0, DET_HVC_FLAG_192:0, DET_MH_CRC16_189_192:0, DET_MH_CYCLE_COUNTER_189_192:0, DET_MH_SCAN_INDEX_4LSB_189_192:0, DET_OUTSIDE_SECTOR_189:0, DET_OUTSIDE_SECTOR_190:0, DET_OUTSIDE_SECTOR_191:0, DET_OUTSIDE_SECTOR_192:0, DET_POINT_TARGET_PROB_189:0, DET_POINT_TARGET_PROB_190:0, DET_POINT_TARGET_PROB_191:0, DET_POINT_TARGET_PROB_192:0, DET_RANGE_189:0, DET_RANGE_190:0, DET_RANGE_191:0, DET_RANGE_192:0, DET_RANGE_ERR_189:0, DET_RANGE_ERR_190:0, DET_RANGE_ERR_191:0, DET_RANGE_ERR_192:0, DET_RANGE_VELOCITY_189:16384, DET_RANGE_VELOCITY_190:16384, DET_RANGE_VELOCITY_191:16384, DET_RANGE_VELOCITY_192:16384, DET_RANGE_VELOCITY_ERR_189:0, DET_RANGE_VELOCITY_ERR_190:0, DET_RANGE_VELOCITY_ERR_191:0, DET_RANGE_VELOCITY_ERR_192:0, DET_RCS_189:128, DET_RCS_190:128, DET_RCS_191:128, DET_RCS_192:128, DET_SNR_189:0, DET_SNR_190:0, DET_SNR_191:0, DET_SNR_192:0, DET_SUPER_RES_TARGET_189:0, DET_SUPER_RES_TARGET_190:0, DET_SUPER_RES_TARGET_191:0, DET_SUPER_RES_TARGET_192:0, DET_VALID_FLAG_189:0, DET_VALID_FLAG_190:0, DET_VALID_FLAG_191:0, DET_VALID_FLAG_192:0]}, provided-interface=Pi_SG_Detections_189_192
      Pp_SG_Detections_193_196: nonqueued-sender-com-spec{data-element=Vdp_SG_Detections_193_196, init-value=fields=[DET_AZIMUTH_193:0, DET_AZIMUTH_194:0, DET_AZIMUTH_195:0, DET_AZIMUTH_196:0, DET_AZIMUTH_ERR_193:0, DET_AZIMUTH_ERR_194:0, DET_AZIMUTH_ERR_195:0, DET_AZIMUTH_ERR_196:0, DET_BI_STATIC_FLAG_193:0, DET_BI_STATIC_FLAG_194:0, DET_BI_STATIC_FLAG_195:0, DET_BI_STATIC_FLAG_196:0, DET_CONFD_AZIMUTH_193:0, DET_CONFD_AZIMUTH_194:0, DET_CONFD_AZIMUTH_195:0, DET_CONFD_AZIMUTH_196:0, DET_CONFD_ELEVATION_193:0, DET_CONFD_ELEVATION_194:0, DET_CONFD_ELEVATION_195:0, DET_CONFD_ELEVATION_196:0, DET_ELEVATION_193:0, DET_ELEVATION_194:0, DET_ELEVATION_195:0, DET_ELEVATION_196:0, DET_ELEVATION_ERR_193:0, DET_ELEVATION_ERR_194:0, DET_ELEVATION_ERR_195:0, DET_ELEVATION_ERR_196:0, DET_EXISTENCE_PROB_193:0, DET_EXISTENCE_PROB_194:0, DET_EXISTENCE_PROB_195:0, DET_EXISTENCE_PROB_196:0, DET_HVC_FLAG_193:0, DET_HVC_FLAG_194:0, DET_HVC_FLAG_195:0, DET_HVC_FLAG_196:0, DET_MH_CRC16_193_196:0, DET_MH_CYCLE_COUNTER_193_196:0, DET_MH_SCAN_INDEX_4LSB_193_196:0, DET_OUTSIDE_SECTOR_193:0, DET_OUTSIDE_SECTOR_194:0, DET_OUTSIDE_SECTOR_195:0, DET_OUTSIDE_SECTOR_196:0, DET_POINT_TARGET_PROB_193:0, DET_POINT_TARGET_PROB_194:0, DET_POINT_TARGET_PROB_195:0, DET_POINT_TARGET_PROB_196:0, DET_RANGE_193:0, DET_RANGE_194:0, DET_RANGE_195:0, DET_RANGE_196:0, DET_RANGE_ERR_193:0, DET_RANGE_ERR_194:0, DET_RANGE_ERR_195:0, DET_RANGE_ERR_196:0, DET_RANGE_VELOCITY_193:16384, DET_RANGE_VELOCITY_194:16384, DET_RANGE_VELOCITY_195:16384, DET_RANGE_VELOCITY_196:16384, DET_RANGE_VELOCITY_ERR_193:0, DET_RANGE_VELOCITY_ERR_194:0, DET_RANGE_VELOCITY_ERR_195:0, DET_RANGE_VELOCITY_ERR_196:0, DET_RCS_193:128, DET_RCS_194:128, DET_RCS_195:128, DET_RCS_196:128, DET_SNR_193:0, DET_SNR_194:0, DET_SNR_195:0, DET_SNR_196:0, DET_SUPER_RES_TARGET_193:0, DET_SUPER_RES_TARGET_194:0, DET_SUPER_RES_TARGET_195:0, DET_SUPER_RES_TARGET_196:0, DET_VALID_FLAG_193:0, DET_VALID_FLAG_194:0, DET_VALID_FLAG_195:0, DET_VALID_FLAG_196:0]}, provided-interface=Pi_SG_Detections_193_196
      Pp_SG_Detections_197_200: nonqueued-sender-com-spec{data-element=Vdp_SG_Detections_197_200, init-value=fields=[DET_AZIMUTH_197:0, DET_AZIMUTH_198:0, DET_AZIMUTH_199:0, DET_AZIMUTH_200:0, DET_AZIMUTH_ERR_197:0, DET_AZIMUTH_ERR_198:0, DET_AZIMUTH_ERR_199:0, DET_AZIMUTH_ERR_200:0, DET_BI_STATIC_FLAG_197:0, DET_BI_STATIC_FLAG_198:0, DET_BI_STATIC_FLAG_199:0, DET_BI_STATIC_FLAG_200:0, DET_CONFD_AZIMUTH_197:0, DET_CONFD_AZIMUTH_198:0, DET_CONFD_AZIMUTH_199:0, DET_CONFD_AZIMUTH_200:0, DET_CONFD_ELEVATION_197:0, DET_CONFD_ELEVATION_198:0, DET_CONFD_ELEVATION_199:0, DET_CONFD_ELEVATION_200:0, DET_ELEVATION_197:0, DET_ELEVATION_198:0, DET_ELEVATION_199:0, DET_ELEVATION_200:0, DET_ELEVATION_ERR_197:0, DET_ELEVATION_ERR_198:0, DET_ELEVATION_ERR_199:0, DET_ELEVATION_ERR_200:0, DET_EXISTENCE_PROB_197:0, DET_EXISTENCE_PROB_198:0, DET_EXISTENCE_PROB_199:0, DET_EXISTENCE_PROB_200:0, DET_HVC_FLAG_197:0, DET_HVC_FLAG_198:0, DET_HVC_FLAG_199:0, DET_HVC_FLAG_200:0, DET_MH_CRC16_197_200:0, DET_MH_CYCLE_COUNTER_197_200:0, DET_MH_SCAN_INDEX_4LSB_197_200:0, DET_OUTSIDE_SECTOR_197:0, DET_OUTSIDE_SECTOR_198:0, DET_OUTSIDE_SECTOR_199:0, DET_OUTSIDE_SECTOR_200:0, DET_POINT_TARGET_PROB_197:0, DET_POINT_TARGET_PROB_198:0, DET_POINT_TARGET_PROB_199:0, DET_POINT_TARGET_PROB_200:0, DET_RANGE_197:0, DET_RANGE_198:0, DET_RANGE_199:0, DET_RANGE_200:0, DET_RANGE_ERR_197:0, DET_RANGE_ERR_198:0, DET_RANGE_ERR_199:0, DET_RANGE_ERR_200:0, DET_RANGE_VELOCITY_197:16384, DET_RANGE_VELOCITY_198:16384, DET_RANGE_VELOCITY_199:16384, DET_RANGE_VELOCITY_200:16384, DET_RANGE_VELOCITY_ERR_197:0, DET_RANGE_VELOCITY_ERR_198:0, DET_RANGE_VELOCITY_ERR_199:0, DET_RANGE_VELOCITY_ERR_200:0, DET_RCS_197:128, DET_RCS_198:128, DET_RCS_199:128, DET_RCS_200:128, DET_SNR_197:0, DET_SNR_198:0, DET_SNR_199:0, DET_SNR_200:0, DET_SUPER_RES_TARGET_197:0, DET_SUPER_RES_TARGET_198:0, DET_SUPER_RES_TARGET_199:0, DET_SUPER_RES_TARGET_200:0, DET_VALID_FLAG_197:0, DET_VALID_FLAG_198:0, DET_VALID_FLAG_199:0, DET_VALID_FLAG_200:0]}, provided-interface=Pi_SG_Detections_197_200
      Pp_SG_Detections_201_204: nonqueued-sender-com-spec{data-element=Vdp_SG_Detections_201_204, init-value=fields=[DET_AZIMUTH_201:0, DET_AZIMUTH_202:0, DET_AZIMUTH_203:0, DET_AZIMUTH_204:0, DET_AZIMUTH_ERR_201:0, DET_AZIMUTH_ERR_202:0, DET_AZIMUTH_ERR_203:0, DET_AZIMUTH_ERR_204:0, DET_BI_STATIC_FLAG_201:0, DET_BI_STATIC_FLAG_202:0, DET_BI_STATIC_FLAG_203:0, DET_BI_STATIC_FLAG_204:0, DET_CONFD_AZIMUTH_201:0, DET_CONFD_AZIMUTH_202:0, DET_CONFD_AZIMUTH_203:0, DET_CONFD_AZIMUTH_204:0, DET_CONFD_ELEVATION_201:0, DET_CONFD_ELEVATION_202:0, DET_CONFD_ELEVATION_203:0, DET_CONFD_ELEVATION_204:0, DET_ELEVATION_201:0, DET_ELEVATION_202:0, DET_ELEVATION_203:0, DET_ELEVATION_204:0, DET_ELEVATION_ERR_201:0, DET_ELEVATION_ERR_202:0, DET_ELEVATION_ERR_203:0, DET_ELEVATION_ERR_204:0, DET_EXISTENCE_PROB_201:0, DET_EXISTENCE_PROB_202:0, DET_EXISTENCE_PROB_203:0, DET_EXISTENCE_PROB_204:0, DET_HVC_FLAG_201:0, DET_HVC_FLAG_202:0, DET_HVC_FLAG_203:0, DET_HVC_FLAG_204:0, DET_MH_CRC16_201_204:0, DET_MH_CYCLE_COUNTER_201_204:0, DET_MH_SCAN_INDEX_4LSB_201_204:0, DET_OUTSIDE_SECTOR_201:0, DET_OUTSIDE_SECTOR_202:0, DET_OUTSIDE_SECTOR_203:0, DET_OUTSIDE_SECTOR_204:0, DET_POINT_TARGET_PROB_201:0, DET_POINT_TARGET_PROB_202:0, DET_POINT_TARGET_PROB_203:0, DET_POINT_TARGET_PROB_204:0, DET_RANGE_201:0, DET_RANGE_202:0, DET_RANGE_203:0, DET_RANGE_204:0, DET_RANGE_ERR_201:0, DET_RANGE_ERR_202:0, DET_RANGE_ERR_203:0, DET_RANGE_ERR_204:0, DET_RANGE_VELOCITY_201:16384, DET_RANGE_VELOCITY_202:16384, DET_RANGE_VELOCITY_203:16384, DET_RANGE_VELOCITY_204:16384, DET_RANGE_VELOCITY_ERR_201:0, DET_RANGE_VELOCITY_ERR_202:0, DET_RANGE_VELOCITY_ERR_203:0, DET_RANGE_VELOCITY_ERR_204:0, DET_RCS_201:128, DET_RCS_202:128, DET_RCS_203:128, DET_RCS_204:128, DET_SNR_201:0, DET_SNR_202:0, DET_SNR_203:0, DET_SNR_204:0, DET_SUPER_RES_TARGET_201:0, DET_SUPER_RES_TARGET_202:0, DET_SUPER_RES_TARGET_203:0, DET_SUPER_RES_TARGET_204:0, DET_VALID_FLAG_201:0, DET_VALID_FLAG_202:0, DET_VALID_FLAG_203:0, DET_VALID_FLAG_204:0]}, provided-interface=Pi_SG_Detections_201_204
      Pp_SG_Detections_205_208: nonqueued-sender-com-spec{data-element=Vdp_SG_Detections_205_208, init-value=fields=[DET_AZIMUTH_205:0, DET_AZIMUTH_206:0, DET_AZIMUTH_207:0, DET_AZIMUTH_208:0, DET_AZIMUTH_ERR_205:0, DET_AZIMUTH_ERR_206:0, DET_AZIMUTH_ERR_207:0, DET_AZIMUTH_ERR_208:0, DET_BI_STATIC_FLAG_205:0, DET_BI_STATIC_FLAG_206:0, DET_BI_STATIC_FLAG_207:0, DET_BI_STATIC_FLAG_208:0, DET_CONFD_AZIMUTH_205:0, DET_CONFD_AZIMUTH_206:0, DET_CONFD_AZIMUTH_207:0, DET_CONFD_AZIMUTH_208:0, DET_CONFD_ELEVATION_205:0, DET_CONFD_ELEVATION_206:0, DET_CONFD_ELEVATION_207:0, DET_CONFD_ELEVATION_208:0, DET_ELEVATION_205:0, DET_ELEVATION_206:0, DET_ELEVATION_207:0, DET_ELEVATION_208:0, DET_ELEVATION_ERR_205:0, DET_ELEVATION_ERR_206:0, DET_ELEVATION_ERR_207:0, DET_ELEVATION_ERR_208:0, DET_EXISTENCE_PROB_205:0, DET_EXISTENCE_PROB_206:0, DET_EXISTENCE_PROB_207:0, DET_EXISTENCE_PROB_208:0, DET_HVC_FLAG_205:0, DET_HVC_FLAG_206:0, DET_HVC_FLAG_207:0, DET_HVC_FLAG_208:0, DET_MH_CRC16_205_208:0, DET_MH_CYCLE_COUNTER_205_208:0, DET_MH_SCAN_INDEX_4LSB_205_208:0, DET_OUTSIDE_SECTOR_205:0, DET_OUTSIDE_SECTOR_206:0, DET_OUTSIDE_SECTOR_207:0, DET_OUTSIDE_SECTOR_208:0, DET_POINT_TARGET_PROB_205:0, DET_POINT_TARGET_PROB_206:0, DET_POINT_TARGET_PROB_207:0, DET_POINT_TARGET_PROB_208:0, DET_RANGE_205:0, DET_RANGE_206:0, DET_RANGE_207:0, DET_RANGE_208:0, DET_RANGE_ERR_205:0, DET_RANGE_ERR_206:0, DET_RANGE_ERR_207:0, DET_RANGE_ERR_208:0, DET_RANGE_VELOCITY_205:16384, DET_RANGE_VELOCITY_206:16384, DET_RANGE_VELOCITY_207:16384, DET_RANGE_VELOCITY_208:16384, DET_RANGE_VELOCITY_ERR_205:0, DET_RANGE_VELOCITY_ERR_206:0, DET_RANGE_VELOCITY_ERR_207:0, DET_RANGE_VELOCITY_ERR_208:0, DET_RCS_205:128, DET_RCS_206:128, DET_RCS_207:128, DET_RCS_208:128, DET_SNR_205:0, DET_SNR_206:0, DET_SNR_207:0, DET_SNR_208:0, DET_SUPER_RES_TARGET_205:0, DET_SUPER_RES_TARGET_206:0, DET_SUPER_RES_TARGET_207:0, DET_SUPER_RES_TARGET_208:0, DET_VALID_FLAG_205:0, DET_VALID_FLAG_206:0, DET_VALID_FLAG_207:0, DET_VALID_FLAG_208:0]}, provided-interface=Pi_SG_Detections_205_208
      Pp_SG_Detections_209_212: nonqueued-sender-com-spec{data-element=Vdp_SG_Detections_209_212, init-value=fields=[DET_AZIMUTH_209:0, DET_AZIMUTH_210:0, DET_AZIMUTH_211:0, DET_AZIMUTH_212:0, DET_AZIMUTH_ERR_209:0, DET_AZIMUTH_ERR_210:0, DET_AZIMUTH_ERR_211:0, DET_AZIMUTH_ERR_212:0, DET_BI_STATIC_FLAG_209:0, DET_BI_STATIC_FLAG_210:0, DET_BI_STATIC_FLAG_211:0, DET_BI_STATIC_FLAG_212:0, DET_CONFD_AZIMUTH_209:0, DET_CONFD_AZIMUTH_210:0, DET_CONFD_AZIMUTH_211:0, DET_CONFD_AZIMUTH_212:0, DET_CONFD_ELEVATION_209:0, DET_CONFD_ELEVATION_210:0, DET_CONFD_ELEVATION_211:0, DET_CONFD_ELEVATION_212:0, DET_ELEVATION_209:0, DET_ELEVATION_210:0, DET_ELEVATION_211:0, DET_ELEVATION_212:0, DET_ELEVATION_ERR_209:0, DET_ELEVATION_ERR_210:0, DET_ELEVATION_ERR_211:0, DET_ELEVATION_ERR_212:0, DET_EXISTENCE_PROB_209:0, DET_EXISTENCE_PROB_210:0, DET_EXISTENCE_PROB_211:0, DET_EXISTENCE_PROB_212:0, DET_HVC_FLAG_209:0, DET_HVC_FLAG_210:0, DET_HVC_FLAG_211:0, DET_HVC_FLAG_212:0, DET_MH_CRC16_209_212:0, DET_MH_CYCLE_COUNTER_209_212:0, DET_MH_SCAN_INDEX_4LSB_209_212:0, DET_OUTSIDE_SECTOR_209:0, DET_OUTSIDE_SECTOR_210:0, DET_OUTSIDE_SECTOR_211:0, DET_OUTSIDE_SECTOR_212:0, DET_POINT_TARGET_PROB_209:0, DET_POINT_TARGET_PROB_210:0, DET_POINT_TARGET_PROB_211:0, DET_POINT_TARGET_PROB_212:0, DET_RANGE_209:0, DET_RANGE_210:0, DET_RANGE_211:0, DET_RANGE_212:0, DET_RANGE_ERR_209:0, DET_RANGE_ERR_210:0, DET_RANGE_ERR_211:0, DET_RANGE_ERR_212:0, DET_RANGE_VELOCITY_209:16384, DET_RANGE_VELOCITY_210:16384, DET_RANGE_VELOCITY_211:16384, DET_RANGE_VELOCITY_212:16384, DET_RANGE_VELOCITY_ERR_209:0, DET_RANGE_VELOCITY_ERR_210:0, DET_RANGE_VELOCITY_ERR_211:0, DET_RANGE_VELOCITY_ERR_212:0, DET_RCS_209:128, DET_RCS_210:128, DET_RCS_211:128, DET_RCS_212:128, DET_SNR_209:0, DET_SNR_210:0, DET_SNR_211:0, DET_SNR_212:0, DET_SUPER_RES_TARGET_209:0, DET_SUPER_RES_TARGET_210:0, DET_SUPER_RES_TARGET_211:0, DET_SUPER_RES_TARGET_212:0, DET_VALID_FLAG_209:0, DET_VALID_FLAG_210:0, DET_VALID_FLAG_211:0, DET_VALID_FLAG_212:0]}, provided-interface=Pi_SG_Detections_209_212
      Pp_SG_Detections_213_216: nonqueued-sender-com-spec{data-element=Vdp_SG_Detections_213_216, init-value=fields=[DET_AZIMUTH_213:0, DET_AZIMUTH_214:0, DET_AZIMUTH_215:0, DET_AZIMUTH_216:0, DET_AZIMUTH_ERR_213:0, DET_AZIMUTH_ERR_214:0, DET_AZIMUTH_ERR_215:0, DET_AZIMUTH_ERR_216:0, DET_BI_STATIC_FLAG_213:0, DET_BI_STATIC_FLAG_214:0, DET_BI_STATIC_FLAG_215:0, DET_BI_STATIC_FLAG_216:0, DET_CONFD_AZIMUTH_213:0, DET_CONFD_AZIMUTH_214:0, DET_CONFD_AZIMUTH_215:0, DET_CONFD_AZIMUTH_216:0, DET_CONFD_ELEVATION_213:0, DET_CONFD_ELEVATION_214:0, DET_CONFD_ELEVATION_215:0, DET_CONFD_ELEVATION_216:0, DET_ELEVATION_213:0, DET_ELEVATION_214:0, DET_ELEVATION_215:0, DET_ELEVATION_216:0, DET_ELEVATION_ERR_213:0, DET_ELEVATION_ERR_214:0, DET_ELEVATION_ERR_215:0, DET_ELEVATION_ERR_216:0, DET_EXISTENCE_PROB_213:0, DET_EXISTENCE_PROB_214:0, DET_EXISTENCE_PROB_215:0, DET_EXISTENCE_PROB_216:0, DET_HVC_FLAG_213:0, DET_HVC_FLAG_214:0, DET_HVC_FLAG_215:0, DET_HVC_FLAG_216:0, DET_MH_CRC16_213_216:0, DET_MH_CYCLE_COUNTER_213_216:0, DET_MH_SCAN_INDEX_4LSB_213_216:0, DET_OUTSIDE_SECTOR_213:0, DET_OUTSIDE_SECTOR_214:0, DET_OUTSIDE_SECTOR_215:0, DET_OUTSIDE_SECTOR_216:0, DET_POINT_TARGET_PROB_213:0, DET_POINT_TARGET_PROB_214:0, DET_POINT_TARGET_PROB_215:0, DET_POINT_TARGET_PROB_216:0, DET_RANGE_213:0, DET_RANGE_214:0, DET_RANGE_215:0, DET_RANGE_216:0, DET_RANGE_ERR_213:0, DET_RANGE_ERR_214:0, DET_RANGE_ERR_215:0, DET_RANGE_ERR_216:0, DET_RANGE_VELOCITY_213:16384, DET_RANGE_VELOCITY_214:16384, DET_RANGE_VELOCITY_215:16384, DET_RANGE_VELOCITY_216:16384, DET_RANGE_VELOCITY_ERR_213:0, DET_RANGE_VELOCITY_ERR_214:0, DET_RANGE_VELOCITY_ERR_215:0, DET_RANGE_VELOCITY_ERR_216:0, DET_RCS_213:128, DET_RCS_214:128, DET_RCS_215:128, DET_RCS_216:128, DET_SNR_213:0, DET_SNR_214:0, DET_SNR_215:0, DET_SNR_216:0, DET_SUPER_RES_TARGET_213:0, DET_SUPER_RES_TARGET_214:0, DET_SUPER_RES_TARGET_215:0, DET_SUPER_RES_TARGET_216:0, DET_VALID_FLAG_213:0, DET_VALID_FLAG_214:0, DET_VALID_FLAG_215:0, DET_VALID_FLAG_216:0]}, provided-interface=Pi_SG_Detections_213_216
      Pp_SG_Detections_217_220: nonqueued-sender-com-spec{data-element=Vdp_SG_Detections_217_220, init-value=fields=[DET_AZIMUTH_217:0, DET_AZIMUTH_218:0, DET_AZIMUTH_219:0, DET_AZIMUTH_220:0, DET_AZIMUTH_ERR_217:0, DET_AZIMUTH_ERR_218:0, DET_AZIMUTH_ERR_219:0, DET_AZIMUTH_ERR_220:0, DET_BI_STATIC_FLAG_217:0, DET_BI_STATIC_FLAG_218:0, DET_BI_STATIC_FLAG_219:0, DET_BI_STATIC_FLAG_220:0, DET_CONFD_AZIMUTH_217:0, DET_CONFD_AZIMUTH_218:0, DET_CONFD_AZIMUTH_219:0, DET_CONFD_AZIMUTH_220:0, DET_CONFD_ELEVATION_217:0, DET_CONFD_ELEVATION_218:0, DET_CONFD_ELEVATION_219:0, DET_CONFD_ELEVATION_220:0, DET_ELEVATION_217:0, DET_ELEVATION_218:0, DET_ELEVATION_219:0, DET_ELEVATION_220:0, DET_ELEVATION_ERR_217:0, DET_ELEVATION_ERR_218:0, DET_ELEVATION_ERR_219:0, DET_ELEVATION_ERR_220:0, DET_EXISTENCE_PROB_217:0, DET_EXISTENCE_PROB_218:0, DET_EXISTENCE_PROB_219:0, DET_EXISTENCE_PROB_220:0, DET_HVC_FLAG_217:0, DET_HVC_FLAG_218:0, DET_HVC_FLAG_219:0, DET_HVC_FLAG_220:0, DET_MH_CRC16_217_220:0, DET_MH_CYCLE_COUNTER_217_220:0, DET_MH_SCAN_INDEX_4LSB_217_220:0, DET_OUTSIDE_SECTOR_217:0, DET_OUTSIDE_SECTOR_218:0, DET_OUTSIDE_SECTOR_219:0, DET_OUTSIDE_SECTOR_220:0, DET_POINT_TARGET_PROB_217:0, DET_POINT_TARGET_PROB_218:0, DET_POINT_TARGET_PROB_219:0, DET_POINT_TARGET_PROB_220:0, DET_RANGE_217:0, DET_RANGE_218:0, DET_RANGE_219:0, DET_RANGE_220:0, DET_RANGE_ERR_217:0, DET_RANGE_ERR_218:0, DET_RANGE_ERR_219:0, DET_RANGE_ERR_220:0, DET_RANGE_VELOCITY_217:16384, DET_RANGE_VELOCITY_218:16384, DET_RANGE_VELOCITY_219:16384, DET_RANGE_VELOCITY_220:16384, DET_RANGE_VELOCITY_ERR_217:0, DET_RANGE_VELOCITY_ERR_218:0, DET_RANGE_VELOCITY_ERR_219:0, DET_RANGE_VELOCITY_ERR_220:0, DET_RCS_217:128, DET_RCS_218:128, DET_RCS_219:128, DET_RCS_220:128, DET_SNR_217:0, DET_SNR_218:0, DET_SNR_219:0, DET_SNR_220:0, DET_SUPER_RES_TARGET_217:0, DET_SUPER_RES_TARGET_218:0, DET_SUPER_RES_TARGET_219:0, DET_SUPER_RES_TARGET_220:0, DET_VALID_FLAG_217:0, DET_VALID_FLAG_218:0, DET_VALID_FLAG_219:0, DET_VALID_FLAG_220:0]}, provided-interface=Pi_SG_Detections_217_220
      Pp_SG_Detections_221_224: nonqueued-sender-com-spec{data-element=Vdp_SG_Detections_221_224, init-value=fields=[DET_AZIMUTH_221:0, DET_AZIMUTH_222:0, DET_AZIMUTH_223:0, DET_AZIMUTH_224:0, DET_AZIMUTH_ERR_221:0, DET_AZIMUTH_ERR_222:0, DET_AZIMUTH_ERR_223:0, DET_AZIMUTH_ERR_224:0, DET_BI_STATIC_FLAG_221:0, DET_BI_STATIC_FLAG_222:0, DET_BI_STATIC_FLAG_223:0, DET_BI_STATIC_FLAG_224:0, DET_CONFD_AZIMUTH_221:0, DET_CONFD_AZIMUTH_222:0, DET_CONFD_AZIMUTH_223:0, DET_CONFD_AZIMUTH_224:0, DET_CONFD_ELEVATION_221:0, DET_CONFD_ELEVATION_222:0, DET_CONFD_ELEVATION_223:0, DET_CONFD_ELEVATION_224:0, DET_ELEVATION_221:0, DET_ELEVATION_222:0, DET_ELEVATION_223:0, DET_ELEVATION_224:0, DET_ELEVATION_ERR_221:0, DET_ELEVATION_ERR_222:0, DET_ELEVATION_ERR_223:0, DET_ELEVATION_ERR_224:0, DET_EXISTENCE_PROB_221:0, DET_EXISTENCE_PROB_222:0, DET_EXISTENCE_PROB_223:0, DET_EXISTENCE_PROB_224:0, DET_HVC_FLAG_221:0, DET_HVC_FLAG_222:0, DET_HVC_FLAG_223:0, DET_HVC_FLAG_224:0, DET_MH_CRC16_221_224:0, DET_MH_CYCLE_COUNTER_221_224:0, DET_MH_SCAN_INDEX_4LSB_221_224:0, DET_OUTSIDE_SECTOR_221:0, DET_OUTSIDE_SECTOR_222:0, DET_OUTSIDE_SECTOR_223:0, DET_OUTSIDE_SECTOR_224:0, DET_POINT_TARGET_PROB_221:0, DET_POINT_TARGET_PROB_222:0, DET_POINT_TARGET_PROB_223:0, DET_POINT_TARGET_PROB_224:0, DET_RANGE_221:0, DET_RANGE_222:0, DET_RANGE_223:0, DET_RANGE_224:0, DET_RANGE_ERR_221:0, DET_RANGE_ERR_222:0, DET_RANGE_ERR_223:0, DET_RANGE_ERR_224:0, DET_RANGE_VELOCITY_221:16384, DET_RANGE_VELOCITY_222:16384, DET_RANGE_VELOCITY_223:16384, DET_RANGE_VELOCITY_224:16384, DET_RANGE_VELOCITY_ERR_221:0, DET_RANGE_VELOCITY_ERR_222:0, DET_RANGE_VELOCITY_ERR_223:0, DET_RANGE_VELOCITY_ERR_224:0, DET_RCS_221:128, DET_RCS_222:128, DET_RCS_223:128, DET_RCS_224:128, DET_SNR_221:0, DET_SNR_222:0, DET_SNR_223:0, DET_SNR_224:0, DET_SUPER_RES_TARGET_221:0, DET_SUPER_RES_TARGET_222:0, DET_SUPER_RES_TARGET_223:0, DET_SUPER_RES_TARGET_224:0, DET_VALID_FLAG_221:0, DET_VALID_FLAG_222:0, DET_VALID_FLAG_223:0, DET_VALID_FLAG_224:0]}, provided-interface=Pi_SG_Detections_221_224
      Pp_SG_Detections_225_228: nonqueued-sender-com-spec{data-element=Vdp_SG_Detections_225_228, init-value=fields=[DET_AZIMUTH_225:0, DET_AZIMUTH_226:0, DET_AZIMUTH_227:0, DET_AZIMUTH_228:0, DET_AZIMUTH_ERR_225:0, DET_AZIMUTH_ERR_226:0, DET_AZIMUTH_ERR_227:0, DET_AZIMUTH_ERR_228:0, DET_BI_STATIC_FLAG_225:0, DET_BI_STATIC_FLAG_226:0, DET_BI_STATIC_FLAG_227:0, DET_BI_STATIC_FLAG_228:0, DET_CONFD_AZIMUTH_225:0, DET_CONFD_AZIMUTH_226:0, DET_CONFD_AZIMUTH_227:0, DET_CONFD_AZIMUTH_228:0, DET_CONFD_ELEVATION_225:0, DET_CONFD_ELEVATION_226:0, DET_CONFD_ELEVATION_227:0, DET_CONFD_ELEVATION_228:0, DET_ELEVATION_225:0, DET_ELEVATION_226:0, DET_ELEVATION_227:0, DET_ELEVATION_228:0, DET_ELEVATION_ERR_225:0, DET_ELEVATION_ERR_226:0, DET_ELEVATION_ERR_227:0, DET_ELEVATION_ERR_228:0, DET_EXISTENCE_PROB_225:0, DET_EXISTENCE_PROB_226:0, DET_EXISTENCE_PROB_227:0, DET_EXISTENCE_PROB_228:0, DET_HVC_FLAG_225:0, DET_HVC_FLAG_226:0, DET_HVC_FLAG_227:0, DET_HVC_FLAG_228:0, DET_MH_CRC16_225_228:0, DET_MH_CYCLE_COUNTER_225_228:0, DET_MH_SCAN_INDEX_4LSB_225_228:0, DET_OUTSIDE_SECTOR_225:0, DET_OUTSIDE_SECTOR_226:0, DET_OUTSIDE_SECTOR_227:0, DET_OUTSIDE_SECTOR_228:0, DET_POINT_TARGET_PROB_225:0, DET_POINT_TARGET_PROB_226:0, DET_POINT_TARGET_PROB_227:0, DET_POINT_TARGET_PROB_228:0, DET_RANGE_225:0, DET_RANGE_226:0, DET_RANGE_227:0, DET_RANGE_228:0, DET_RANGE_ERR_225:0, DET_RANGE_ERR_226:0, DET_RANGE_ERR_227:0, DET_RANGE_ERR_228:0, DET_RANGE_VELOCITY_225:16384, DET_RANGE_VELOCITY_226:16384, DET_RANGE_VELOCITY_227:16384, DET_RANGE_VELOCITY_228:16384, DET_RANGE_VELOCITY_ERR_225:0, DET_RANGE_VELOCITY_ERR_226:0, DET_RANGE_VELOCITY_ERR_227:0, DET_RANGE_VELOCITY_ERR_228:0, DET_RCS_225:128, DET_RCS_226:128, DET_RCS_227:128, DET_RCS_228:128, DET_SNR_225:0, DET_SNR_226:0, DET_SNR_227:0, DET_SNR_228:0, DET_SUPER_RES_TARGET_225:0, DET_SUPER_RES_TARGET_226:0, DET_SUPER_RES_TARGET_227:0, DET_SUPER_RES_TARGET_228:0, DET_VALID_FLAG_225:0, DET_VALID_FLAG_226:0, DET_VALID_FLAG_227:0, DET_VALID_FLAG_228:0]}, provided-interface=Pi_SG_Detections_225_228
      Pp_SG_Detections_229_232: nonqueued-sender-com-spec{data-element=Vdp_SG_Detections_229_232, init-value=fields=[DET_AZIMUTH_229:0, DET_AZIMUTH_230:0, DET_AZIMUTH_231:0, DET_AZIMUTH_232:0, DET_AZIMUTH_ERR_229:0, DET_AZIMUTH_ERR_230:0, DET_AZIMUTH_ERR_231:0, DET_AZIMUTH_ERR_232:0, DET_BI_STATIC_FLAG_229:0, DET_BI_STATIC_FLAG_230:0, DET_BI_STATIC_FLAG_231:0, DET_BI_STATIC_FLAG_232:0, DET_CONFD_AZIMUTH_229:0, DET_CONFD_AZIMUTH_230:0, DET_CONFD_AZIMUTH_231:0, DET_CONFD_AZIMUTH_232:0, DET_CONFD_ELEVATION_229:0, DET_CONFD_ELEVATION_230:0, DET_CONFD_ELEVATION_231:0, DET_CONFD_ELEVATION_232:0, DET_ELEVATION_229:0, DET_ELEVATION_230:0, DET_ELEVATION_231:0, DET_ELEVATION_232:0, DET_ELEVATION_ERR_229:0, DET_ELEVATION_ERR_230:0, DET_ELEVATION_ERR_231:0, DET_ELEVATION_ERR_232:0, DET_EXISTENCE_PROB_229:0, DET_EXISTENCE_PROB_230:0, DET_EXISTENCE_PROB_231:0, DET_EXISTENCE_PROB_232:0, DET_HVC_FLAG_229:0, DET_HVC_FLAG_230:0, DET_HVC_FLAG_231:0, DET_HVC_FLAG_232:0, DET_MH_CRC16_229_232:0, DET_MH_CYCLE_COUNTER_229_232:0, DET_MH_SCAN_INDEX_4LSB_229_232:0, DET_OUTSIDE_SECTOR_229:0, DET_OUTSIDE_SECTOR_230:0, DET_OUTSIDE_SECTOR_231:0, DET_OUTSIDE_SECTOR_232:0, DET_POINT_TARGET_PROB_229:0, DET_POINT_TARGET_PROB_230:0, DET_POINT_TARGET_PROB_231:0, DET_POINT_TARGET_PROB_232:0, DET_RANGE_229:0, DET_RANGE_230:0, DET_RANGE_231:0, DET_RANGE_232:0, DET_RANGE_ERR_229:0, DET_RANGE_ERR_230:0, DET_RANGE_ERR_231:0, DET_RANGE_ERR_232:0, DET_RANGE_VELOCITY_229:16384, DET_RANGE_VELOCITY_230:16384, DET_RANGE_VELOCITY_231:16384, DET_RANGE_VELOCITY_232:16384, DET_RANGE_VELOCITY_ERR_229:0, DET_RANGE_VELOCITY_ERR_230:0, DET_RANGE_VELOCITY_ERR_231:0, DET_RANGE_VELOCITY_ERR_232:0, DET_RCS_229:128, DET_RCS_230:128, DET_RCS_231:128, DET_RCS_232:128, DET_SNR_229:0, DET_SNR_230:0, DET_SNR_231:0, DET_SNR_232:0, DET_SUPER_RES_TARGET_229:0, DET_SUPER_RES_TARGET_230:0, DET_SUPER_RES_TARGET_231:0, DET_SUPER_RES_TARGET_232:0, DET_VALID_FLAG_229:0, DET_VALID_FLAG_230:0, DET_VALID_FLAG_231:0, DET_VALID_FLAG_232:0]}, provided-interface=Pi_SG_Detections_229_232
      Pp_SG_Detections_233_236: nonqueued-sender-com-spec{data-element=Vdp_SG_Detections_233_236, init-value=fields=[DET_AZIMUTH_233:0, DET_AZIMUTH_234:0, DET_AZIMUTH_235:0, DET_AZIMUTH_236:0, DET_AZIMUTH_ERR_233:0, DET_AZIMUTH_ERR_234:0, DET_AZIMUTH_ERR_235:0, DET_AZIMUTH_ERR_236:0, DET_BI_STATIC_FLAG_233:0, DET_BI_STATIC_FLAG_234:0, DET_BI_STATIC_FLAG_235:0, DET_BI_STATIC_FLAG_236:0, DET_CONFD_AZIMUTH_233:0, DET_CONFD_AZIMUTH_234:0, DET_CONFD_AZIMUTH_235:0, DET_CONFD_AZIMUTH_236:0, DET_CONFD_ELEVATION_233:0, DET_CONFD_ELEVATION_234:0, DET_CONFD_ELEVATION_235:0, DET_CONFD_ELEVATION_236:0, DET_ELEVATION_233:0, DET_ELEVATION_234:0, DET_ELEVATION_235:0, DET_ELEVATION_236:0, DET_ELEVATION_ERR_233:0, DET_ELEVATION_ERR_234:0, DET_ELEVATION_ERR_235:0, DET_ELEVATION_ERR_236:0, DET_EXISTENCE_PROB_233:0, DET_EXISTENCE_PROB_234:0, DET_EXISTENCE_PROB_235:0, DET_EXISTENCE_PROB_236:0, DET_HVC_FLAG_233:0, DET_HVC_FLAG_234:0, DET_HVC_FLAG_235:0, DET_HVC_FLAG_236:0, DET_MH_CRC16_233_236:0, DET_MH_CYCLE_COUNTER_233_236:0, DET_MH_SCAN_INDEX_4LSB_233_236:0, DET_OUTSIDE_SECTOR_233:0, DET_OUTSIDE_SECTOR_234:0, DET_OUTSIDE_SECTOR_235:0, DET_OUTSIDE_SECTOR_236:0, DET_POINT_TARGET_PROB_233:0, DET_POINT_TARGET_PROB_234:0, DET_POINT_TARGET_PROB_235:0, DET_POINT_TARGET_PROB_236:0, DET_RANGE_233:0, DET_RANGE_234:0, DET_RANGE_235:0, DET_RANGE_236:0, DET_RANGE_ERR_233:0, DET_RANGE_ERR_234:0, DET_RANGE_ERR_235:0, DET_RANGE_ERR_236:0, DET_RANGE_VELOCITY_233:16384, DET_RANGE_VELOCITY_234:16384, DET_RANGE_VELOCITY_235:16384, DET_RANGE_VELOCITY_236:16384, DET_RANGE_VELOCITY_ERR_233:0, DET_RANGE_VELOCITY_ERR_234:0, DET_RANGE_VELOCITY_ERR_235:0, DET_RANGE_VELOCITY_ERR_236:0, DET_RCS_233:128, DET_RCS_234:128, DET_RCS_235:128, DET_RCS_236:128, DET_SNR_233:0, DET_SNR_234:0, DET_SNR_235:0, DET_SNR_236:0, DET_SUPER_RES_TARGET_233:0, DET_SUPER_RES_TARGET_234:0, DET_SUPER_RES_TARGET_235:0, DET_SUPER_RES_TARGET_236:0, DET_VALID_FLAG_233:0, DET_VALID_FLAG_234:0, DET_VALID_FLAG_235:0, DET_VALID_FLAG_236:0]}, provided-interface=Pi_SG_Detections_233_236
      Pp_SG_Detections_237_240: nonqueued-sender-com-spec{data-element=Vdp_SG_Detections_237_240, init-value=fields=[DET_AZIMUTH_237:0, DET_AZIMUTH_238:0, DET_AZIMUTH_239:0, DET_AZIMUTH_240:0, DET_AZIMUTH_ERR_237:0, DET_AZIMUTH_ERR_238:0, DET_AZIMUTH_ERR_239:0, DET_AZIMUTH_ERR_240:0, DET_BI_STATIC_FLAG_237:0, DET_BI_STATIC_FLAG_238:0, DET_BI_STATIC_FLAG_239:0, DET_BI_STATIC_FLAG_240:0, DET_CONFD_AZIMUTH_237:0, DET_CONFD_AZIMUTH_238:0, DET_CONFD_AZIMUTH_239:0, DET_CONFD_AZIMUTH_240:0, DET_CONFD_ELEVATION_237:0, DET_CONFD_ELEVATION_238:0, DET_CONFD_ELEVATION_239:0, DET_CONFD_ELEVATION_240:0, DET_ELEVATION_237:0, DET_ELEVATION_238:0, DET_ELEVATION_239:0, DET_ELEVATION_240:0, DET_ELEVATION_ERR_237:0, DET_ELEVATION_ERR_238:0, DET_ELEVATION_ERR_239:0, DET_ELEVATION_ERR_240:0, DET_EXISTENCE_PROB_237:0, DET_EXISTENCE_PROB_238:0, DET_EXISTENCE_PROB_239:0, DET_EXISTENCE_PROB_240:0, DET_HVC_FLAG_237:0, DET_HVC_FLAG_238:0, DET_HVC_FLAG_239:0, DET_HVC_FLAG_240:0, DET_MH_CRC16_237_240:0, DET_MH_CYCLE_COUNTER_237_240:0, DET_MH_SCAN_INDEX_4LSB_237_240:0, DET_OUTSIDE_SECTOR_237:0, DET_OUTSIDE_SECTOR_238:0, DET_OUTSIDE_SECTOR_239:0, DET_OUTSIDE_SECTOR_240:0, DET_POINT_TARGET_PROB_237:0, DET_POINT_TARGET_PROB_238:0, DET_POINT_TARGET_PROB_239:0, DET_POINT_TARGET_PROB_240:0, DET_RANGE_237:0, DET_RANGE_238:0, DET_RANGE_239:0, DET_RANGE_240:0, DET_RANGE_ERR_237:0, DET_RANGE_ERR_238:0, DET_RANGE_ERR_239:0, DET_RANGE_ERR_240:0, DET_RANGE_VELOCITY_237:16384, DET_RANGE_VELOCITY_238:16384, DET_RANGE_VELOCITY_239:16384, DET_RANGE_VELOCITY_240:16384, DET_RANGE_VELOCITY_ERR_237:0, DET_RANGE_VELOCITY_ERR_238:0, DET_RANGE_VELOCITY_ERR_239:0, DET_RANGE_VELOCITY_ERR_240:0, DET_RCS_237:128, DET_RCS_238:128, DET_RCS_239:128, DET_RCS_240:128, DET_SNR_237:0, DET_SNR_238:0, DET_SNR_239:0, DET_SNR_240:0, DET_SUPER_RES_TARGET_237:0, DET_SUPER_RES_TARGET_238:0, DET_SUPER_RES_TARGET_239:0, DET_SUPER_RES_TARGET_240:0, DET_VALID_FLAG_237:0, DET_VALID_FLAG_238:0, DET_VALID_FLAG_239:0, DET_VALID_FLAG_240:0]}, provided-interface=Pi_SG_Detections_237_240
      Pp_SG_Detections_241_244: nonqueued-sender-com-spec{data-element=Vdp_SG_Detections_241_244, init-value=fields=[DET_AZIMUTH_241:0, DET_AZIMUTH_242:0, DET_AZIMUTH_243:0, DET_AZIMUTH_244:0, DET_AZIMUTH_ERR_241:0, DET_AZIMUTH_ERR_242:0, DET_AZIMUTH_ERR_243:0, DET_AZIMUTH_ERR_244:0, DET_BI_STATIC_FLAG_241:0, DET_BI_STATIC_FLAG_242:0, DET_BI_STATIC_FLAG_243:0, DET_BI_STATIC_FLAG_244:0, DET_CONFD_AZIMUTH_241:0, DET_CONFD_AZIMUTH_242:0, DET_CONFD_AZIMUTH_243:0, DET_CONFD_AZIMUTH_244:0, DET_CONFD_ELEVATION_241:0, DET_CONFD_ELEVATION_242:0, DET_CONFD_ELEVATION_243:0, DET_CONFD_ELEVATION_244:0, DET_ELEVATION_241:0, DET_ELEVATION_242:0, DET_ELEVATION_243:0, DET_ELEVATION_244:0, DET_ELEVATION_ERR_241:0, DET_ELEVATION_ERR_242:0, DET_ELEVATION_ERR_243:0, DET_ELEVATION_ERR_244:0, DET_EXISTENCE_PROB_241:0, DET_EXISTENCE_PROB_242:0, DET_EXISTENCE_PROB_243:0, DET_EXISTENCE_PROB_244:0, DET_HVC_FLAG_241:0, DET_HVC_FLAG_242:0, DET_HVC_FLAG_243:0, DET_HVC_FLAG_244:0, DET_MH_CRC16_241_244:0, DET_MH_CYCLE_COUNTER_241_244:0, DET_MH_SCAN_INDEX_4LSB_241_244:0, DET_OUTSIDE_SECTOR_241:0, DET_OUTSIDE_SECTOR_242:0, DET_OUTSIDE_SECTOR_243:0, DET_OUTSIDE_SECTOR_244:0, DET_POINT_TARGET_PROB_241:0, DET_POINT_TARGET_PROB_242:0, DET_POINT_TARGET_PROB_243:0, DET_POINT_TARGET_PROB_244:0, DET_RANGE_241:0, DET_RANGE_242:0, DET_RANGE_243:0, DET_RANGE_244:0, DET_RANGE_ERR_241:0, DET_RANGE_ERR_242:0, DET_RANGE_ERR_243:0, DET_RANGE_ERR_244:0, DET_RANGE_VELOCITY_241:16384, DET_RANGE_VELOCITY_242:16384, DET_RANGE_VELOCITY_243:16384, DET_RANGE_VELOCITY_244:16384, DET_RANGE_VELOCITY_ERR_241:0, DET_RANGE_VELOCITY_ERR_242:0, DET_RANGE_VELOCITY_ERR_243:0, DET_RANGE_VELOCITY_ERR_244:0, DET_RCS_241:128, DET_RCS_242:128, DET_RCS_243:128, DET_RCS_244:128, DET_SNR_241:0, DET_SNR_242:0, DET_SNR_243:0, DET_SNR_244:0, DET_SUPER_RES_TARGET_241:0, DET_SUPER_RES_TARGET_242:0, DET_SUPER_RES_TARGET_243:0, DET_SUPER_RES_TARGET_244:0, DET_VALID_FLAG_241:0, DET_VALID_FLAG_242:0, DET_VALID_FLAG_243:0, DET_VALID_FLAG_244:0]}, provided-interface=Pi_SG_Detections_241_244
      Pp_SG_Detections_245_248: nonqueued-sender-com-spec{data-element=Vdp_SG_Detections_245_248, init-value=fields=[DET_AZIMUTH_245:0, DET_AZIMUTH_246:0, DET_AZIMUTH_247:0, DET_AZIMUTH_248:0, DET_AZIMUTH_ERR_245:0, DET_AZIMUTH_ERR_246:0, DET_AZIMUTH_ERR_247:0, DET_AZIMUTH_ERR_248:0, DET_BI_STATIC_FLAG_245:0, DET_BI_STATIC_FLAG_246:0, DET_BI_STATIC_FLAG_247:0, DET_BI_STATIC_FLAG_248:0, DET_CONFD_AZIMUTH_245:0, DET_CONFD_AZIMUTH_246:0, DET_CONFD_AZIMUTH_247:0, DET_CONFD_AZIMUTH_248:0, DET_CONFD_ELEVATION_245:0, DET_CONFD_ELEVATION_246:0, DET_CONFD_ELEVATION_247:0, DET_CONFD_ELEVATION_248:0, DET_ELEVATION_245:0, DET_ELEVATION_246:0, DET_ELEVATION_247:0, DET_ELEVATION_248:0, DET_ELEVATION_ERR_245:0, DET_ELEVATION_ERR_246:0, DET_ELEVATION_ERR_247:0, DET_ELEVATION_ERR_248:0, DET_EXISTENCE_PROB_245:0, DET_EXISTENCE_PROB_246:0, DET_EXISTENCE_PROB_247:0, DET_EXISTENCE_PROB_248:0, DET_HVC_FLAG_245:0, DET_HVC_FLAG_246:0, DET_HVC_FLAG_247:0, DET_HVC_FLAG_248:0, DET_MH_CRC16_245_248:0, DET_MH_CYCLE_COUNTER_245_248:0, DET_MH_SCAN_INDEX_4LSB_245_248:0, DET_OUTSIDE_SECTOR_245:0, DET_OUTSIDE_SECTOR_246:0, DET_OUTSIDE_SECTOR_247:0, DET_OUTSIDE_SECTOR_248:0, DET_POINT_TARGET_PROB_245:0, DET_POINT_TARGET_PROB_246:0, DET_POINT_TARGET_PROB_247:0, DET_POINT_TARGET_PROB_248:0, DET_RANGE_245:0, DET_RANGE_246:0, DET_RANGE_247:0, DET_RANGE_248:0, DET_RANGE_ERR_245:0, DET_RANGE_ERR_246:0, DET_RANGE_ERR_247:0, DET_RANGE_ERR_248:0, DET_RANGE_VELOCITY_245:16384, DET_RANGE_VELOCITY_246:16384, DET_RANGE_VELOCITY_247:16384, DET_RANGE_VELOCITY_248:16384, DET_RANGE_VELOCITY_ERR_245:0, DET_RANGE_VELOCITY_ERR_246:0, DET_RANGE_VELOCITY_ERR_247:0, DET_RANGE_VELOCITY_ERR_248:0, DET_RCS_245:128, DET_RCS_246:128, DET_RCS_247:128, DET_RCS_248:128, DET_SNR_245:0, DET_SNR_246:0, DET_SNR_247:0, DET_SNR_248:0, DET_SUPER_RES_TARGET_245:0, DET_SUPER_RES_TARGET_246:0, DET_SUPER_RES_TARGET_247:0, DET_SUPER_RES_TARGET_248:0, DET_VALID_FLAG_245:0, DET_VALID_FLAG_246:0, DET_VALID_FLAG_247:0, DET_VALID_FLAG_248:0]}, provided-interface=Pi_SG_Detections_245_248
      Pp_SG_Detections_249_252: nonqueued-sender-com-spec{data-element=Vdp_SG_Detections_249_252, init-value=fields=[DET_AZIMUTH_249:0, DET_AZIMUTH_250:0, DET_AZIMUTH_251:0, DET_AZIMUTH_252:0, DET_AZIMUTH_ERR_249:0, DET_AZIMUTH_ERR_250:0, DET_AZIMUTH_ERR_251:0, DET_AZIMUTH_ERR_252:0, DET_BI_STATIC_FLAG_249:0, DET_BI_STATIC_FLAG_250:0, DET_BI_STATIC_FLAG_251:0, DET_BI_STATIC_FLAG_252:0, DET_CONFD_AZIMUTH_249:0, DET_CONFD_AZIMUTH_250:0, DET_CONFD_AZIMUTH_251:0, DET_CONFD_AZIMUTH_252:0, DET_CONFD_ELEVATION_249:0, DET_CONFD_ELEVATION_250:0, DET_CONFD_ELEVATION_251:0, DET_CONFD_ELEVATION_252:0, DET_ELEVATION_249:0, DET_ELEVATION_250:0, DET_ELEVATION_251:0, DET_ELEVATION_252:0, DET_ELEVATION_ERR_249:0, DET_ELEVATION_ERR_250:0, DET_ELEVATION_ERR_251:0, DET_ELEVATION_ERR_252:0, DET_EXISTENCE_PROB_249:0, DET_EXISTENCE_PROB_250:0, DET_EXISTENCE_PROB_251:0, DET_EXISTENCE_PROB_252:0, DET_HVC_FLAG_249:0, DET_HVC_FLAG_250:0, DET_HVC_FLAG_251:0, DET_HVC_FLAG_252:0, DET_MH_CRC16_249_252:0, DET_MH_CYCLE_COUNTER_249_252:0, DET_MH_SCAN_INDEX_4LSB_249_252:0, DET_OUTSIDE_SECTOR_249:0, DET_OUTSIDE_SECTOR_250:0, DET_OUTSIDE_SECTOR_251:0, DET_OUTSIDE_SECTOR_252:0, DET_POINT_TARGET_PROB_249:0, DET_POINT_TARGET_PROB_250:0, DET_POINT_TARGET_PROB_251:0, DET_POINT_TARGET_PROB_252:0, DET_RANGE_249:0, DET_RANGE_250:0, DET_RANGE_251:0, DET_RANGE_252:0, DET_RANGE_ERR_249:0, DET_RANGE_ERR_250:0, DET_RANGE_ERR_251:0, DET_RANGE_ERR_252:0, DET_RANGE_VELOCITY_249:16384, DET_RANGE_VELOCITY_250:16384, DET_RANGE_VELOCITY_251:16384, DET_RANGE_VELOCITY_252:16384, DET_RANGE_VELOCITY_ERR_249:0, DET_RANGE_VELOCITY_ERR_250:0, DET_RANGE_VELOCITY_ERR_251:0, DET_RANGE_VELOCITY_ERR_252:0, DET_RCS_249:128, DET_RCS_250:128, DET_RCS_251:128, DET_RCS_252:128, DET_SNR_249:0, DET_SNR_250:0, DET_SNR_251:0, DET_SNR_252:0, DET_SUPER_RES_TARGET_249:0, DET_SUPER_RES_TARGET_250:0, DET_SUPER_RES_TARGET_251:0, DET_SUPER_RES_TARGET_252:0, DET_VALID_FLAG_249:0, DET_VALID_FLAG_250:0, DET_VALID_FLAG_251:0, DET_VALID_FLAG_252:0]}, provided-interface=Pi_SG_Detections_249_252
      Pp_SG_Detections_253_256: nonqueued-sender-com-spec{data-element=Vdp_SG_Detections_253_256, init-value=fields=[DET_AZIMUTH_253:0, DET_AZIMUTH_254:0, DET_AZIMUTH_255:0, DET_AZIMUTH_256:0, DET_AZIMUTH_ERR_253:0, DET_AZIMUTH_ERR_254:0, DET_AZIMUTH_ERR_255:0, DET_AZIMUTH_ERR_256:0, DET_BI_STATIC_FLAG_253:0, DET_BI_STATIC_FLAG_254:0, DET_BI_STATIC_FLAG_255:0, DET_BI_STATIC_FLAG_256:0, DET_CONFD_AZIMUTH_253:0, DET_CONFD_AZIMUTH_254:0, DET_CONFD_AZIMUTH_255:0, DET_CONFD_AZIMUTH_256:0, DET_CONFD_ELEVATION_253:0, DET_CONFD_ELEVATION_254:0, DET_CONFD_ELEVATION_255:0, DET_CONFD_ELEVATION_256:0, DET_ELEVATION_253:0, DET_ELEVATION_254:0, DET_ELEVATION_255:0, DET_ELEVATION_256:0, DET_ELEVATION_ERR_253:0, DET_ELEVATION_ERR_254:0, DET_ELEVATION_ERR_255:0, DET_ELEVATION_ERR_256:0, DET_EXISTENCE_PROB_253:0, DET_EXISTENCE_PROB_254:0, DET_EXISTENCE_PROB_255:0, DET_EXISTENCE_PROB_256:0, DET_HVC_FLAG_253:0, DET_HVC_FLAG_254:0, DET_HVC_FLAG_255:0, DET_HVC_FLAG_256:0, DET_MH_CRC16_253_256:0, DET_MH_CYCLE_COUNTER_253_256:0, DET_MH_SCAN_INDEX_4LSB_253_256:0, DET_OUTSIDE_SECTOR_253:0, DET_OUTSIDE_SECTOR_254:0, DET_OUTSIDE_SECTOR_255:0, DET_OUTSIDE_SECTOR_256:0, DET_POINT_TARGET_PROB_253:0, DET_POINT_TARGET_PROB_254:0, DET_POINT_TARGET_PROB_255:0, DET_POINT_TARGET_PROB_256:0, DET_RANGE_253:0, DET_RANGE_254:0, DET_RANGE_255:0, DET_RANGE_256:0, DET_RANGE_ERR_253:0, DET_RANGE_ERR_254:0, DET_RANGE_ERR_255:0, DET_RANGE_ERR_256:0, DET_RANGE_VELOCITY_253:16384, DET_RANGE_VELOCITY_254:16384, DET_RANGE_VELOCITY_255:16384, DET_RANGE_VELOCITY_256:16384, DET_RANGE_VELOCITY_ERR_253:0, DET_RANGE_VELOCITY_ERR_254:0, DET_RANGE_VELOCITY_ERR_255:0, DET_RANGE_VELOCITY_ERR_256:0, DET_RCS_253:128, DET_RCS_254:128, DET_RCS_255:128, DET_RCS_256:128, DET_SNR_253:0, DET_SNR_254:0, DET_SNR_255:0, DET_SNR_256:0, DET_SUPER_RES_TARGET_253:0, DET_SUPER_RES_TARGET_254:0, DET_SUPER_RES_TARGET_255:0, DET_SUPER_RES_TARGET_256:0, DET_VALID_FLAG_253:0, DET_VALID_FLAG_254:0, DET_VALID_FLAG_255:0, DET_VALID_FLAG_256:0]}, provided-interface=Pi_SG_Detections_253_256
      Pp_SG_Detections_257_260: nonqueued-sender-com-spec{data-element=Vdp_SG_Detections_257_260, init-value=fields=[DET_AZIMUTH_257:0, DET_AZIMUTH_258:0, DET_AZIMUTH_259:0, DET_AZIMUTH_260:0, DET_AZIMUTH_ERR_257:0, DET_AZIMUTH_ERR_258:0, DET_AZIMUTH_ERR_259:0, DET_AZIMUTH_ERR_260:0, DET_BI_STATIC_FLAG_257:0, DET_BI_STATIC_FLAG_258:0, DET_BI_STATIC_FLAG_259:0, DET_BI_STATIC_FLAG_260:0, DET_CONFD_AZIMUTH_257:0, DET_CONFD_AZIMUTH_258:0, DET_CONFD_AZIMUTH_259:0, DET_CONFD_AZIMUTH_260:0, DET_CONFD_ELEVATION_257:0, DET_CONFD_ELEVATION_258:0, DET_CONFD_ELEVATION_259:0, DET_CONFD_ELEVATION_260:0, DET_ELEVATION_257:0, DET_ELEVATION_258:0, DET_ELEVATION_259:0, DET_ELEVATION_260:0, DET_ELEVATION_ERR_257:0, DET_ELEVATION_ERR_258:0, DET_ELEVATION_ERR_259:0, DET_ELEVATION_ERR_260:0, DET_EXISTENCE_PROB_257:0, DET_EXISTENCE_PROB_258:0, DET_EXISTENCE_PROB_259:0, DET_EXISTENCE_PROB_260:0, DET_HVC_FLAG_257:0, DET_HVC_FLAG_258:0, DET_HVC_FLAG_259:0, DET_HVC_FLAG_260:0, DET_MH_CRC16_257_260:0, DET_MH_CYCLE_COUNTER_257_260:0, DET_MH_SCAN_INDEX_4LSB_257_260:0, DET_OUTSIDE_SECTOR_257:0, DET_OUTSIDE_SECTOR_258:0, DET_OUTSIDE_SECTOR_259:0, DET_OUTSIDE_SECTOR_260:0, DET_POINT_TARGET_PROB_257:0, DET_POINT_TARGET_PROB_258:0, DET_POINT_TARGET_PROB_259:0, DET_POINT_TARGET_PROB_260:0, DET_RANGE_257:0, DET_RANGE_258:0, DET_RANGE_259:0, DET_RANGE_260:0, DET_RANGE_ERR_257:0, DET_RANGE_ERR_258:0, DET_RANGE_ERR_259:0, DET_RANGE_ERR_260:0, DET_RANGE_VELOCITY_257:16384, DET_RANGE_VELOCITY_258:16384, DET_RANGE_VELOCITY_259:16384, DET_RANGE_VELOCITY_260:16384, DET_RANGE_VELOCITY_ERR_257:0, DET_RANGE_VELOCITY_ERR_258:0, DET_RANGE_VELOCITY_ERR_259:0, DET_RANGE_VELOCITY_ERR_260:0, DET_RCS_257:128, DET_RCS_258:128, DET_RCS_259:128, DET_RCS_260:128, DET_SNR_257:0, DET_SNR_258:0, DET_SNR_259:0, DET_SNR_260:0, DET_SUPER_RES_TARGET_257:0, DET_SUPER_RES_TARGET_258:0, DET_SUPER_RES_TARGET_259:0, DET_SUPER_RES_TARGET_260:0, DET_VALID_FLAG_257:0, DET_VALID_FLAG_258:0, DET_VALID_FLAG_259:0, DET_VALID_FLAG_260:0]}, provided-interface=Pi_SG_Detections_257_260
      Pp_SG_Detections_261_264: nonqueued-sender-com-spec{data-element=Vdp_SG_Detections_261_264, init-value=fields=[DET_AZIMUTH_261:0, DET_AZIMUTH_262:0, DET_AZIMUTH_263:0, DET_AZIMUTH_264:0, DET_AZIMUTH_ERR_261:0, DET_AZIMUTH_ERR_262:0, DET_AZIMUTH_ERR_263:0, DET_AZIMUTH_ERR_264:0, DET_BI_STATIC_FLAG_261:0, DET_BI_STATIC_FLAG_262:0, DET_BI_STATIC_FLAG_263:0, DET_BI_STATIC_FLAG_264:0, DET_CONFD_AZIMUTH_261:0, DET_CONFD_AZIMUTH_262:0, DET_CONFD_AZIMUTH_263:0, DET_CONFD_AZIMUTH_264:0, DET_CONFD_ELEVATION_261:0, DET_CONFD_ELEVATION_262:0, DET_CONFD_ELEVATION_263:0, DET_CONFD_ELEVATION_264:0, DET_ELEVATION_261:0, DET_ELEVATION_262:0, DET_ELEVATION_263:0, DET_ELEVATION_264:0, DET_ELEVATION_ERR_261:0, DET_ELEVATION_ERR_262:0, DET_ELEVATION_ERR_263:0, DET_ELEVATION_ERR_264:0, DET_EXISTENCE_PROB_261:0, DET_EXISTENCE_PROB_262:0, DET_EXISTENCE_PROB_263:0, DET_EXISTENCE_PROB_264:0, DET_HVC_FLAG_261:0, DET_HVC_FLAG_262:0, DET_HVC_FLAG_263:0, DET_HVC_FLAG_264:0, DET_MH_CRC16_261_264:0, DET_MH_CYCLE_COUNTER_261_264:0, DET_MH_SCAN_INDEX_4LSB_261_264:0, DET_OUTSIDE_SECTOR_261:0, DET_OUTSIDE_SECTOR_262:0, DET_OUTSIDE_SECTOR_263:0, DET_OUTSIDE_SECTOR_264:0, DET_POINT_TARGET_PROB_261:0, DET_POINT_TARGET_PROB_262:0, DET_POINT_TARGET_PROB_263:0, DET_POINT_TARGET_PROB_264:0, DET_RANGE_261:0, DET_RANGE_262:0, DET_RANGE_263:0, DET_RANGE_264:0, DET_RANGE_ERR_261:0, DET_RANGE_ERR_262:0, DET_RANGE_ERR_263:0, DET_RANGE_ERR_264:0, DET_RANGE_VELOCITY_261:16384, DET_RANGE_VELOCITY_262:16384, DET_RANGE_VELOCITY_263:16384, DET_RANGE_VELOCITY_264:16384, DET_RANGE_VELOCITY_ERR_261:0, DET_RANGE_VELOCITY_ERR_262:0, DET_RANGE_VELOCITY_ERR_263:0, DET_RANGE_VELOCITY_ERR_264:0, DET_RCS_261:128, DET_RCS_262:128, DET_RCS_263:128, DET_RCS_264:128, DET_SNR_261:0, DET_SNR_262:0, DET_SNR_263:0, DET_SNR_264:0, DET_SUPER_RES_TARGET_261:0, DET_SUPER_RES_TARGET_262:0, DET_SUPER_RES_TARGET_263:0, DET_SUPER_RES_TARGET_264:0, DET_VALID_FLAG_261:0, DET_VALID_FLAG_262:0, DET_VALID_FLAG_263:0, DET_VALID_FLAG_264:0]}, provided-interface=Pi_SG_Detections_261_264
